VERSION ""

NS_ :

BS_:

BU_: External_Tool IPMA_ADAS SODRR SODRL
VAL_TABLE_ CAN_RADAR_ALIGN_INCOMPLETE 1 "Alignment Incomplete" 0 "Alignment Completed" ;

BO_ 3221225472 VECTOR__INDEPENDENT_SIG_MSG: 0 Vector__XXX
 SG_ FL_Resp_Phys : 0|64@0+ (1,0) [0|0] "" Vector__XXX
 SG_ FR_Resp_Phys : 0|64@0+ (1,0) [0|0] "" Vector__XXX
 SG_ FR_XCP_RESP_DAQ_Byte7 : 0|8@0+ (1,0) [0|0] "" Vector__XXX
 SG_ FR_XCP_RESP_DAQ_Byte6 : 0|8@0+ (1,0) [0|0] "" Vector__XXX
 SG_ FR_XCP_RESP_DAQ_Byte5 : 0|8@0+ (1,0) [0|0] "" Vector__XXX
 SG_ FR_XCP_RESP_DAQ_Byte4 : 0|8@0+ (1,0) [0|0] "" Vector__XXX
 SG_ FR_XCP_RESP_DAQ_Byte3 : 0|8@0+ (1,0) [0|0] "" Vector__XXX
 SG_ FR_XCP_RESP_DAQ_Byte2 : 0|8@0+ (1,0) [0|0] "" Vector__XXX
 SG_ FR_XCP_RESP_DAQ_Byte1 : 0|8@0+ (1,0) [0|0] "" Vector__XXX
 SG_ FR_XCP_RESP_DAQ_Byte0 : 0|8@0+ (1,0) [0|0] "" Vector__XXX
 SG_ FL_XCP_RESP_DAQ_Byte7 : 0|8@0+ (1,0) [0|0] "" Vector__XXX
 SG_ FL_XCP_RESP_DAQ_Byte6 : 0|8@0+ (1,0) [0|0] "" Vector__XXX
 SG_ FL_XCP_RESP_DAQ_Byte5 : 0|8@0+ (1,0) [0|0] "" Vector__XXX
 SG_ FL_XCP_RESP_DAQ_Byte4 : 0|8@0+ (1,0) [0|0] "" Vector__XXX
 SG_ FL_XCP_RESP_DAQ_Byte3 : 0|8@0+ (1,0) [0|0] "" Vector__XXX
 SG_ FL_XCP_RESP_DAQ_Byte2 : 0|8@0+ (1,0) [0|0] "" Vector__XXX
 SG_ FL_XCP_RESP_DAQ_Byte1 : 0|8@0+ (1,0) [0|0] "" Vector__XXX
 SG_ FL_XCP_RESP_DAQ_Byte0 : 0|8@0+ (1,0) [0|0] "" Vector__XXX
 SG_ FR_XCP_RESP_CTO_Byte7 : 0|8@0+ (1,0) [0|0] "" Vector__XXX
 SG_ FR_XCP_RESP_CTO_Byte6 : 0|8@0+ (1,0) [0|0] "" Vector__XXX
 SG_ FR_XCP_RESP_CTO_Byte5 : 0|8@0+ (1,0) [0|0] "" Vector__XXX
 SG_ FR_XCP_RESP_CTO_Byte4 : 0|8@0+ (1,0) [0|0] "" Vector__XXX
 SG_ FR_XCP_RESP_CTO_Byte3 : 0|8@0+ (1,0) [0|0] "" Vector__XXX
 SG_ FR_XCP_RESP_CTO_Byte2 : 0|8@0+ (1,0) [0|0] "" Vector__XXX
 SG_ FR_XCP_RESP_CTO_Byte1 : 0|8@0+ (1,0) [0|0] "" Vector__XXX
 SG_ FR_XCP_RESP_CTO_Byte0 : 0|8@0+ (1,0) [0|0] "" Vector__XXX
 SG_ FL_XCP_RESP_CTO_Byte7 : 0|8@0+ (1,0) [0|0] "" Vector__XXX
 SG_ FL_XCP_RESP_CTO_Byte6 : 0|8@0+ (1,0) [0|0] "" Vector__XXX
 SG_ FL_XCP_RESP_CTO_Byte5 : 0|8@0+ (1,0) [0|0] "" Vector__XXX
 SG_ FL_XCP_RESP_CTO_Byte4 : 0|8@0+ (1,0) [0|0] "" Vector__XXX
 SG_ FL_XCP_RESP_CTO_Byte3 : 0|8@0+ (1,0) [0|0] "" Vector__XXX
 SG_ FL_XCP_RESP_CTO_Byte2 : 0|8@0+ (1,0) [0|0] "" Vector__XXX
 SG_ FL_XCP_RESP_CTO_Byte1 : 0|8@0+ (1,0) [0|0] "" Vector__XXX
 SG_ FL_XCP_RESP_CTO_Byte0 : 0|8@0+ (1,0) [0|0] "" Vector__XXX

BO_ 16 FL_System_Control: 8 External_Tool
 SG_ FL_CAN_INST_MODE : 23|16@0+ (1,0) [0|65535] ""  SODRL

BO_ 17 FR_System_Control: 8 External_Tool
 SG_ FR_CAN_INST_MODE : 23|16@0+ (1,0) [0|65535] ""  SODRL

BO_ 18 RL_System_Control: 8 External_Tool
 SG_ RL_CAN_INST_MODE : 23|16@0+ (1,0) [0|65535] ""  SODRR

BO_ 19 RR_System_Control: 8 External_Tool
 SG_ RR_CAN_INST_MODE : 23|16@0+ (1,0) [0|65535] ""  SODRR

BO_ 396 RL_Header_InformationDetections: 8 SODRL
 SG_ RL_CAN_VRTCL_ALIGN_UPDATES_Nbr : 23|16@0+ (1,0) [0|65535] ""  IPMA_ADAS
 SG_ RL_CAN_HRZNTL_ALIGN_UPDATES_Nbr : 7|16@0+ (1,0) [0|65535] ""  IPMA_ADAS

BO_ 460 RR_Header_InformationDetections: 8 SODRR
 SG_ RR_CAN_VRTCL_ALIGN_UPDATES_Nbr : 23|16@0+ (1,0) [0|65535] ""  IPMA_ADAS
 SG_ RR_CAN_HRZNTL_ALIGN_UPDATES_Nbr : 7|16@0+ (1,0) [0|65535] ""  IPMA_ADAS

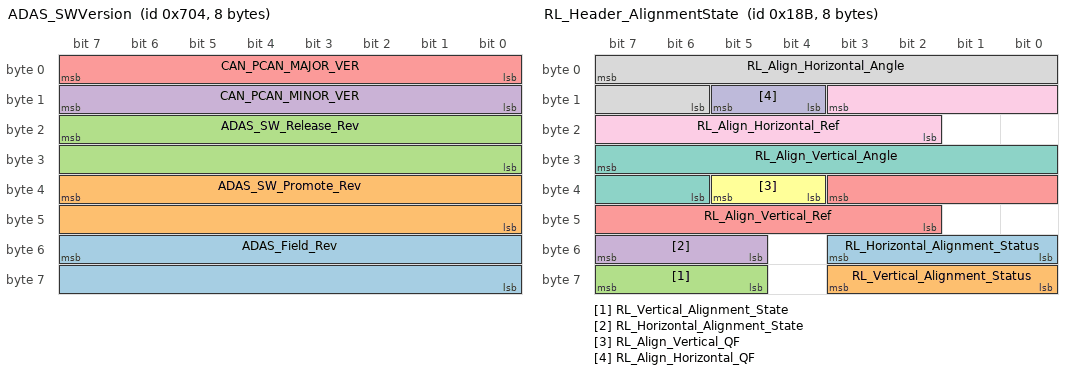
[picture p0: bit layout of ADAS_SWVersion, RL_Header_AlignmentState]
BO_ 1796 ADAS_SWVersion: 8 IPMA_ADAS
 SG_ ADAS_Field_Rev : 55|16@0+ (1,0) [0|0] ""  SODRL,SODRR
 SG_ ADAS_SW_Promote_Rev : 39|16@0+ (1,0) [0|0] ""  SODRL,SODRR
 SG_ ADAS_SW_Release_Rev : 23|16@0+ (1,0) [0|0] ""  SODRL,SODRR
 SG_ CAN_PCAN_MINOR_VER : 15|8@0+ (1,0) [0|0] ""  SODRL,SODRR
 SG_ CAN_PCAN_MAJOR_VER : 7|8@0+ (1,0) [0|0] ""  SODRL,SODRR

BO_ 395 RL_Header_AlignmentState: 8 SODRL
 SG_ RL_Horizontal_Alignment_Status : 51|4@0+ (1,0) [0|15] ""  IPMA_ADAS,External_Tool
 SG_ RL_Vertical_Alignment_Status : 59|4@0+ (1,0) [0|15] ""  IPMA_ADAS,External_Tool
 SG_ RL_Vertical_Alignment_State : 63|3@0+ (1,0) [0|7] ""  IPMA_ADAS,External_Tool
 SG_ RL_Horizontal_Alignment_State : 55|3@0+ (1,0) [0|7] ""  IPMA_ADAS,External_Tool
 SG_ RL_Align_Vertical_Ref : 35|10@0+ (0.000170608920038546,-0.0872664625997165) [-0.0872664625997165|0.0872664625997165] "Rad"  IPMA_ADAS,External_Tool
 SG_ RL_Align_Vertical_QF : 37|2@0+ (1,0) [0|3] ""  IPMA_ADAS,External_Tool
 SG_ RL_Align_Vertical_Angle : 31|10@0+ (0.000170608920038546,-0.0872664625997165) [-0.0872664625997165|0.0872664625997165] "Rad"  IPMA_ADAS,External_Tool
 SG_ RL_Align_Horizontal_Angle : 7|10@0+ (0.000341217840077093,-0.174532925199433) [-0.174532925199433|0.174532925199433] "Rad"  IPMA_ADAS,External_Tool
 SG_ RL_Align_Horizontal_Ref : 11|10@0+ (0.000341217840077093,-0.174532925199433) [-0.174532925199433|0.174532925199433] "Rad"  IPMA_ADAS,External_Tool
 SG_ RL_Align_Horizontal_QF : 13|2@0+ (1,0) [0|3] ""  IPMA_ADAS,External_Tool

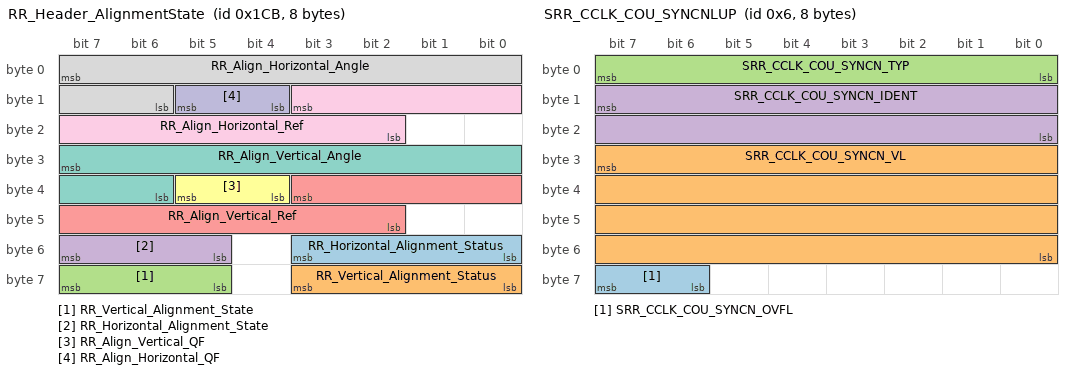
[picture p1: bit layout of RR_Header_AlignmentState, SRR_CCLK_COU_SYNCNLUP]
BO_ 459 RR_Header_AlignmentState: 8 SODRR
 SG_ RR_Horizontal_Alignment_Status : 51|4@0+ (1,0) [0|15] ""  IPMA_ADAS,External_Tool
 SG_ RR_Vertical_Alignment_Status : 59|4@0+ (1,0) [0|15] ""  IPMA_ADAS,External_Tool
 SG_ RR_Vertical_Alignment_State : 63|3@0+ (1,0) [0|7] ""  IPMA_ADAS,External_Tool
 SG_ RR_Horizontal_Alignment_State : 55|3@0+ (1,0) [0|7] ""  IPMA_ADAS,External_Tool
 SG_ RR_Align_Vertical_Ref : 35|10@0+ (0.000170608920038546,-0.0872664625997165) [-0.0872664625997165|0.0872664625997165] "Rad"  IPMA_ADAS,External_Tool
 SG_ RR_Align_Vertical_QF : 37|2@0+ (1,0) [0|3] ""  IPMA_ADAS,External_Tool
 SG_ RR_Align_Vertical_Angle : 31|10@0+ (0.000170608920038546,-0.0872664625997165) [-0.0872664625997165|0.0872664625997165] "Rad"  IPMA_ADAS,External_Tool
 SG_ RR_Align_Horizontal_Angle : 7|10@0+ (0.000341217840077093,-0.174532925199433) [-0.174532925199433|0.174532925199433] "Rad"  IPMA_ADAS,External_Tool
 SG_ RR_Align_Horizontal_Ref : 11|10@0+ (0.000341217840077093,-0.174532925199433) [-0.174532925199433|0.174532925199433] "Rad"  IPMA_ADAS,External_Tool
 SG_ RR_Align_Horizontal_QF : 13|2@0+ (1,0) [0|3] ""  IPMA_ADAS,External_Tool

BO_ 6 SRR_CCLK_COU_SYNCNLUP: 8 External_Tool
 SG_ SRR_CCLK_COU_SYNCN_OVFL : 63|2@0+ (1,0) [0|0] ""  SODRR,SODRL
 SG_ SRR_CCLK_COU_SYNCN_VL : 31|32@0+ (1,0) [0|4294967295] "micro seconds"  SODRR,SODRL
 SG_ SRR_CCLK_COU_SYNCN_TYP : 7|8@0- (1,0) [0|0] ""  SODRR,SODRL
 SG_ SRR_CCLK_COU_SYNCN_IDENT : 15|16@0- (1,0) [0|65532] ""  SODRR,SODRL

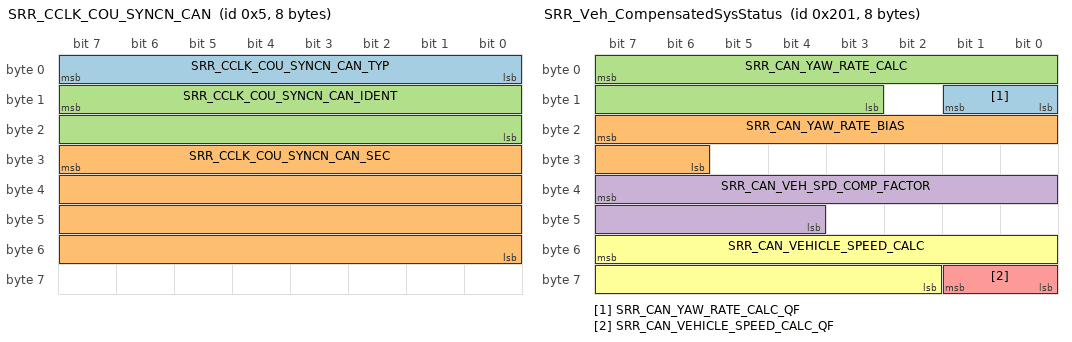
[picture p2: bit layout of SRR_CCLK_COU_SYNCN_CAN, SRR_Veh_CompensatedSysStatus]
BO_ 5 SRR_CCLK_COU_SYNCN_CAN: 8 External_Tool
 SG_ SRR_CCLK_COU_SYNCN_CAN_TYP : 7|8@0+ (1,0) [0|255] ""  SODRR,SODRL
 SG_ SRR_CCLK_COU_SYNCN_CAN_SEC : 31|32@0+ (1,0) [0|4294967292] "seconds"  SODRR,SODRL
 SG_ SRR_CCLK_COU_SYNCN_CAN_IDENT : 15|16@0+ (1,0) [0|65532] ""  SODRR,SODRL

BO_ 513 SRR_Veh_CompensatedSysStatus: 8 IPMA_ADAS
 SG_ SRR_CAN_YAW_RATE_CALC_QF : 9|2@0+ (1,0) [0|3] ""  SODRR,SODRL
 SG_ SRR_CAN_YAW_RATE_BIAS : 23|10@0+ (0.03125,-16) [-16|15.96875] "deg/s"  SODRR,SODRL
 SG_ SRR_CAN_YAW_RATE_CALC : 7|13@0+ (0.03125,-128) [-128|127.96875] "deg/s"  SODRR,SODRL
 SG_ SRR_CAN_VEH_SPD_COMP_FACTOR : 39|12@0+ (9.765625E-005,0.8) [0.8|1.19990234375] "NA"  SODRR,SODRL
 SG_ SRR_CAN_VEHICLE_SPEED_CALC_QF : 57|2@0+ (1,0) [0|3] ""  SODRR,SODRL
 SG_ SRR_CAN_VEHICLE_SPEED_CALC : 55|14@0+ (0.01,0) [0|163.83] "m/s"  SODRR,SODRL

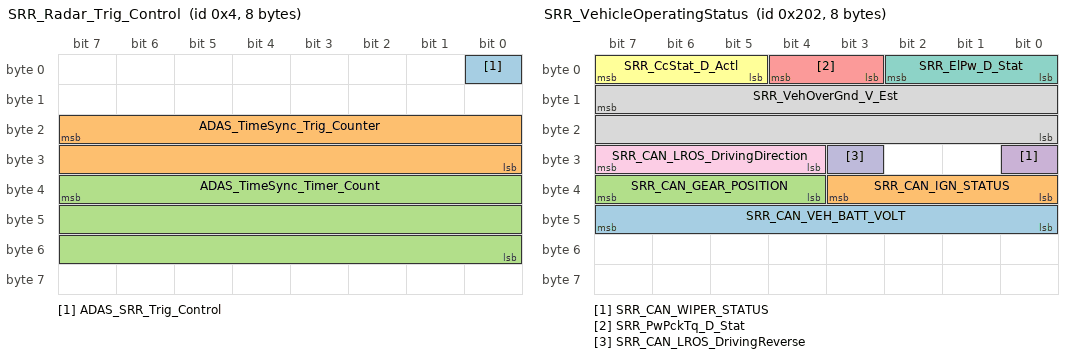
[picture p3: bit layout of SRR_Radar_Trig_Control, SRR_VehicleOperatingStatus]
BO_ 4 SRR_Radar_Trig_Control: 8 IPMA_ADAS
 SG_ ADAS_SRR_Trig_Control : 0|1@0+ (1,0) [0|0] ""  SODRR,SODRL
 SG_ ADAS_TimeSync_Trig_Counter : 23|16@0+ (1,0) [0|0] "us"  SODRR,SODRL
 SG_ ADAS_TimeSync_Timer_Count : 39|24@0+ (1,0) [0|16777215] "us"  SODRR,SODRL

BO_ 514 SRR_VehicleOperatingStatus: 8 IPMA_ADAS
 SG_ SRR_CAN_VEH_BATT_VOLT : 47|8@0+ (0.0625,0) [0|15.875] ""  SODRL,SODRR
 SG_ SRR_CAN_IGN_STATUS : 35|4@0- (1,0) [0|15] ""  SODRL,SODRR
 SG_ SRR_CAN_GEAR_POSITION : 39|4@0+ (1,0) [0|15] ""  SODRL,SODRR
 SG_ SRR_CAN_WIPER_STATUS : 24|1@0+ (1,0) [0|1] ""  SODRL,SODRR
 SG_ SRR_PwPckTq_D_Stat : 4|2@0+ (1,0) [0|3] "SED"  SODRR,SODRL
 SG_ SRR_CcStat_D_Actl : 7|3@0+ (1,0) [0|7] "SED"  SODRR,SODRL
 SG_ SRR_ElPw_D_Stat : 2|3@0+ (1,0) [0|7] "SED"  SODRR,SODRL
 SG_ SRR_VehOverGnd_V_Est : 15|16@0+ (0.01,0) [0|655.33] "kph"  SODRR,SODRL
 SG_ SRR_CAN_LROS_DrivingDirection : 31|4@0+ (1,0) [0|3] ""  SODRR,SODRL
 SG_ SRR_CAN_LROS_DrivingReverse : 27|1@0+ (1,0) [0|1] ""  SODRR,SODRL

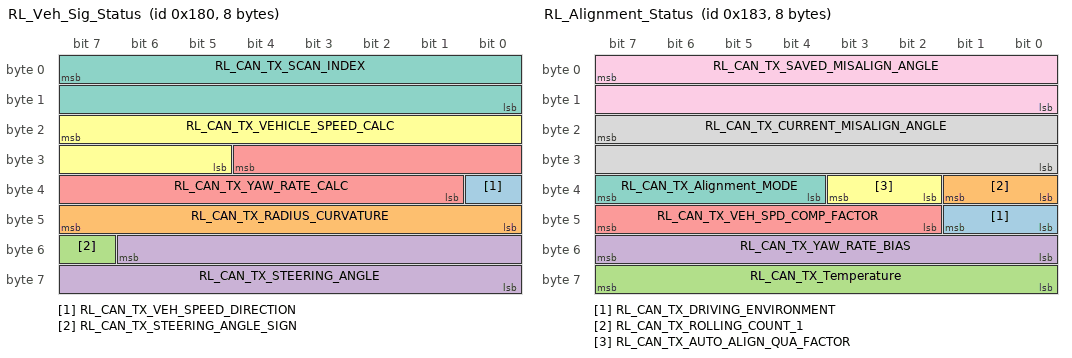
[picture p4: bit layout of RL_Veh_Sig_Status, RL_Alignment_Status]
BO_ 384 RL_Veh_Sig_Status: 8 SODRL
 SG_ RL_CAN_TX_VEH_SPEED_DIRECTION : 32|1@0+ (1,0) [0|0] ""  IPMA_ADAS
 SG_ RL_CAN_TX_RADIUS_CURVATURE : 47|8@0- (25,0) [-3200|3200] "m"  IPMA_ADAS
 SG_ RL_CAN_TX_STEERING_ANGLE_SIGN : 55|1@0+ (1,0) [0|1] ""  IPMA_ADAS
 SG_ RL_CAN_TX_STEERING_ANGLE : 54|15@0+ (1,0) [0|32767] "deg"  IPMA_ADAS
 SG_ RL_CAN_TX_YAW_RATE_CALC : 28|12@0- (0.0625,0) [-128|127.9375] "deg/s"  IPMA_ADAS
 SG_ RL_CAN_TX_VEHICLE_SPEED_CALC : 23|11@0+ (0.0625,0) [0|127.9375] "m/s"  IPMA_ADAS
 SG_ RL_CAN_TX_SCAN_INDEX : 7|16@0+ (1,0) [0|65535] ""  IPMA_ADAS

BO_ 385 RL_HW_Version_Status: 64 SODRL
 SG_ RL_Dolphin_Chip_ID_Part2 : 391|64@0+ (1,0) [0|0] ""  IPMA_ADAS
 SG_ RL_Dolphin_Chip_ID_Part1 : 327|64@0+ (1,0) [0|0] ""  IPMA_ADAS
 SG_ RL_RRU_Chip_ID_Part4 : 263|64@0+ (1,0) [0|0] ""  IPMA_ADAS
 SG_ RL_RRU_Chip_ID_Part3 : 199|64@0+ (1,0) [0|0] ""  IPMA_ADAS
 SG_ RL_RRU_Chip_ID_Part2 : 135|64@0+ (1,0) [0|0] ""  IPMA_ADAS
 SG_ RL_RRU_Chip_ID_Part1 : 71|64@0+ (1,0) [0|0] ""  IPMA_ADAS
 SG_ RL_CAN_TX_SW_VERSION_DSP : 47|24@0+ (1,0) [0|0] ""  IPMA_ADAS
 SG_ RL_CAN_TX_PCAN_PROTOCOL_MINOR : 15|8@0+ (1,0) [0|255] ""  IPMA_ADAS
 SG_ RL_CAN_TX_PCAN_PROTOCOL_MAJOR : 3|4@0+ (1,0) [0|15] ""  IPMA_ADAS
 SG_ RL_CAN_TX_SW_VERSION_ARM : 23|24@0+ (1,0) [0|0] ""  IPMA_ADAS
 SG_ RL_CAN_TX_HW_VERSION : 7|4@0+ (1,0) [0|0] ""  IPMA_ADAS

BO_ 386 RL_SW_Version_Status: 16 SODRL
 SG_ RL_CAN_TX_Field : 23|8@0+ (1,0) [0|0] ""  IPMA_ADAS
 SG_ RL_CAN_TX_Promote : 13|6@0+ (1,0) [0|0] ""  IPMA_ADAS
 SG_ RL_CAN_TX_Major : 3|6@0+ (1,0) [0|0] ""  IPMA_ADAS
 SG_ RL_CAN_TX_Hardware : 7|4@0+ (1,0) [0|0] ""  IPMA_ADAS
 SG_ RL_CAN_TX_SERIAL_NUMBER_SEQUENCE : 35|12@0+ (1,0) [0|0] ""  IPMA_ADAS
 SG_ RL_CAN_TX_SERIAL_NUM_JULIAN_YEAR : 38|3@0+ (1,2014) [0|0] ""  IPMA_ADAS
 SG_ RL_CAN_TX_SERIAL_NUM_JULIAN_DAY : 31|9@0+ (1,0) [0|0] ""  IPMA_ADAS
 SG_ RL_CAN_TX_ARM_THROUGHPUT : 63|5@0+ (3.2258,0) [0|0] ""  IPMA_ADAS
 SG_ RL_CAN_TX_SYSTEM_STATUS : 58|3@0+ (1,0) [0|0] ""  IPMA_ADAS
 SG_ RL_CAN_TX_LOOK_TYPE_1 : 50|1@0+ (1,0) [0|0] ""  IPMA_ADAS
 SG_ RL_CAN_TX_OVERHEAT_ERROR : 51|1@0+ (1,0) [0|0] ""  IPMA_ADAS
 SG_ RL_CAN_TX_RANGE_PERF_ERROR : 52|1@0+ (1,0) [0|0] ""  IPMA_ADAS
 SG_ RL_CAN_TX_COMM_ERROR : 53|1@0+ (1,0) [0|0] ""  IPMA_ADAS
 SG_ RL_CAN_TX_INTERNAL_ERROR : 54|1@0+ (1,0) [0|0] ""  IPMA_ADAS
 SG_ RL_CAN_TX_XCVR_OPERATIONAL : 55|1@0+ (1,0) [0|0] ""  IPMA_ADAS
 SG_ RL_CAN_PBL_Field_Revision : 119|8@0+ (1,0) [0|255] ""  IPMA_ADAS
 SG_ RL_CAN_PBL_Promote_Revision : 111|8@0+ (1,0) [0|255] ""  IPMA_ADAS
 SG_ RL_CAN_SW_Field_Revision : 87|8@0+ (1,0) [0|255] ""  IPMA_ADAS
 SG_ RL_CAN_SW_Promote_Revision : 79|8@0+ (1,0) [0|255] ""  IPMA_ADAS
 SG_ RL_CAN_SW_Field : 95|8@0+ (1,0) [0|255] ""  IPMA_ADAS
 SG_ RL_CAN_SW_Release_Revision : 71|8@0+ (1,0) [0|255] ""  IPMA_ADAS
 SG_ RL_CAN_PBL_Release_Revision : 103|8@0+ (1,0) [0|255] ""  IPMA_ADAS

BO_ 387 RL_Alignment_Status: 8 SODRL
 SG_ RL_CAN_TX_DRIVING_ENVIRONMENT : 41|2@0+ (1,0) [0|0] ""  IPMA_ADAS
 SG_ RL_CAN_TX_ROLLING_COUNT_1 : 33|2@0+ (1,0) [0|0] ""  IPMA_ADAS
 SG_ RL_CAN_TX_Temperature : 63|8@0+ (1,-50) [-50|205] "degC"  IPMA_ADAS
 SG_ RL_CAN_TX_YAW_RATE_BIAS : 55|8@0- (0.125,0) [-16|15.875] ""  IPMA_ADAS
 SG_ RL_CAN_TX_VEH_SPD_COMP_FACTOR : 47|6@0- (0.001953125,1) [0.9375|1.060546875] ""  IPMA_ADAS
 SG_ RL_CAN_TX_AUTO_ALIGN_QUA_FACTOR : 35|2@0+ (1,0) [0|0] ""  IPMA_ADAS
 SG_ RL_CAN_TX_Alignment_MODE : 39|4@0+ (1,0) [0|0] ""  IPMA_ADAS
 SG_ RL_CAN_TX_CURRENT_MISALIGN_ANGLE : 23|16@0- (0.0009765625,0) [-10|10] "Deg"  IPMA_ADAS
 SG_ RL_CAN_TX_SAVED_MISALIGN_ANGLE : 7|16@0- (0.0009765625,0) [-10|10] "Deg"  IPMA_ADAS

BO_ 388 RL_Fault_Status: 8 SODRL
 SG_ RL_Supply_2_3v_Out_Of_Range_Flt : 9|1@0+ (1,0) [0|0] ""  IPMA_ADAS
 SG_ RL_Supply_1_25v_Out_Of_Range_Flt : 10|1@0+ (1,0) [0|0] ""  IPMA_ADAS
 SG_ RL_Software_Incompatible_Flt : 61|1@0+ (1,0) [0|0] ""  IPMA_ADAS
 SG_ RL_Host_Spi_Checksum_Flt : 60|1@0+ (1,0) [0|0] ""  IPMA_ADAS
 SG_ RL_Loss_Of_Comm_With_Dsp_Flt : 59|1@0+ (1,0) [0|0] ""  IPMA_ADAS
 SG_ RL_No_Communication_With_Arm_Flt : 58|1@0+ (1,0) [0|0] ""  IPMA_ADAS
 SG_ RL_Communication_With_Host_Flt : 57|1@0+ (1,0) [0|0] ""  IPMA_ADAS
 SG_ RL_Communication_With_Arm_Flt : 56|1@0+ (1,0) [0|0] ""  IPMA_ADAS
 SG_ RL_Dsp_Loop_Overrun_Flt_Dsp : 51|1@0+ (1,0) [0|0] ""  IPMA_ADAS
 SG_ RL_Tuning_Sensitivity_Flt : 50|1@0+ (1,0) [0|0] ""  IPMA_ADAS
 SG_ RL_Saturated_Tuning_Freq_Flt : 49|1@0+ (1,0) [0|0] ""  IPMA_ADAS
 SG_ RL_Local_Oscillator_Power_Flt : 48|1@0+ (1,0) [0|0] ""  IPMA_ADAS
 SG_ RL_Transmitter_Power_Flt : 47|1@0+ (1,0) [0|0] ""  IPMA_ADAS
 SG_ RL_Radar_Data_Sync_Flt : 46|1@0+ (1,0) [0|0] ""  IPMA_ADAS
 SG_ RL_Dsp_Spi_Hardware_Flt : 45|1@0+ (1,0) [0|0] ""  IPMA_ADAS
 SG_ RL_Transmitter_Device_Spi_Flt : 44|1@0+ (1,0) [0|0] ""  IPMA_ADAS
 SG_ RL_Receiver_Device_Spi_Flt : 43|1@0+ (1,0) [0|0] ""  IPMA_ADAS
 SG_ RL_Freq_Synthe_Device_Spi_Flt : 42|1@0+ (1,0) [0|0] ""  IPMA_ADAS
 SG_ RL_Analog_Cnvrtr_Device_Spi_Flt : 41|1@0+ (1,0) [0|0] ""  IPMA_ADAS
 SG_ RL_Transmitter_Id_Flt : 40|1@0+ (1,0) [0|0] ""  IPMA_ADAS
 SG_ RL_Ecu_Temperature_High_Flt : 39|1@0+ (1,0) [0|0] ""  IPMA_ADAS
 SG_ RL_Transmitter_Temp_High_Flt : 38|1@0+ (1,0) [0|0] ""  IPMA_ADAS
 SG_ RL_Alignment_Routine_Failed_Flt : 37|1@0+ (1,0) [0|0] ""  IPMA_ADAS
 SG_ RL_Unreasonable_Radar_Data : 36|1@0+ (1,0) [0|0] ""  IPMA_ADAS
 SG_ RL_Sensor_Blocked_Flt : 35|1@0+ (1,0) [0|0] ""  IPMA_ADAS
 SG_ RL_Vertical_Alignt_Out_Of_Range : 34|1@0+ (1,0) [0|0] ""  IPMA_ADAS
 SG_ RL_Horizontal_Align_Out_Of_Range : 33|1@0+ (1,0) [0|0] ""  IPMA_ADAS
 SG_ RL_Factory_Alignment_Mode : 32|1@0+ (1,0) [0|0] ""  IPMA_ADAS
 SG_ RL_Battery_Low_Flt : 30|1@0+ (1,0) [0|0] ""  IPMA_ADAS
 SG_ RL_Battery_High_Flt : 29|1@0+ (1,0) [0|0] ""  IPMA_ADAS
 SG_ RL_Ecu_Position_Config_Flt : 28|1@0+ (1,0) [0|0] ""  IPMA_ADAS
 SG_ RL_Supply_1_1v_Out_Of_Range_Flt : 27|1@0+ (1,0) [0|0] ""  IPMA_ADAS
 SG_ RL_Supply_1_8v_Out_Of_Range_Flt : 26|1@0+ (1,0) [0|0] ""  IPMA_ADAS
 SG_ RL_Thermistor_Out_Of_Range_Flt : 25|1@0+ (1,0) [0|0] ""  IPMA_ADAS
 SG_ RL_Supply_5v_Out_Of_Range_Flt : 24|1@0+ (1,0) [0|0] ""  IPMA_ADAS
 SG_ RL_Pcan_Init_Missing_Message_Flt : 22|1@0+ (1,0) [0|0] ""  IPMA_ADAS
 SG_ RL_Pcan_Trk_Data_Unreasnble_Flt : 21|1@0+ (1,0) [0|0] ""  IPMA_ADAS
 SG_ RL_Pcan_Data_Range_Check_Flt : 20|1@0+ (1,0) [0|0] ""  IPMA_ADAS
 SG_ RL_Pcan_Missing_Message_Flt : 19|1@0+ (1,0) [0|0] ""  IPMA_ADAS
 SG_ RL_Pcan_Hw_Rx_Buffer_Flt : 18|1@0+ (1,0) [0|0] ""  IPMA_ADAS
 SG_ RL_Pcan_Sw_Buffer_Flt : 17|1@0+ (1,0) [0|0] ""  IPMA_ADAS
 SG_ RL_Pcan_Bus_Off : 16|1@0+ (1,0) [0|0] ""  IPMA_ADAS
 SG_ RL_Host_Instrctn_Set_Check_Flt : 15|1@0+ (1,0) [0|0] ""  IPMA_ADAS
 SG_ RL_Host_Stack_Overflow_Flt : 14|1@0+ (1,0) [0|0] ""  IPMA_ADAS
 SG_ RL_Sensor_Watchdog_Flt : 13|1@0+ (1,0) [0|0] ""  IPMA_ADAS
 SG_ RL_Sensor_Pll_Lock_Flt : 12|1@0+ (1,0) [0|0] ""  IPMA_ADAS
 SG_ RL_Host_Pll_Lock_Flt : 11|1@0+ (1,0) [0|0] ""  IPMA_ADAS
 SG_ RL_Sensor_Ram_Memory_Test_Flt : 8|1@0+ (1,0) [0|0] ""  IPMA_ADAS
 SG_ RL_Host_Ram_Memory_Test_Flt : 7|1@0+ (1,0) [0|0] ""  IPMA_ADAS
 SG_ RL_Snsr_Custmr_Cal_Flsh_Chksum : 6|1@0+ (1,0) [0|0] ""  IPMA_ADAS
 SG_ RL_Dsp_Usc_Validation_Flt : 5|1@0+ (1,0) [0|0] ""  IPMA_ADAS
 SG_ RL_Snsr_Pgrm_Cal_Flsh_Chksum : 4|1@0+ (1,0) [0|0] ""  IPMA_ADAS
 SG_ RL_Sensor_App_Flash_Checksum_Flt : 3|1@0+ (1,0) [0|0] ""  IPMA_ADAS
 SG_ RL_Host_Kp_Alv_Flsh_Chcksm_Flt : 2|1@0+ (1,0) [0|0] ""  IPMA_ADAS
 SG_ RL_Host_Pgm_Cal_Flsh_Chcksum_Flt : 1|1@0+ (1,0) [0|0] ""  IPMA_ADAS
 SG_ RL_Host_App_Flash_Checksum_Flt : 0|1@0+ (1,0) [0|0] ""  IPMA_ADAS

BO_ 389 RL_Error_Status: 12 SODRL
 SG_ RL_Dolphin_Fault_Detection : 87|8@0+ (1,0) [0|63] ""  IPMA_ADAS
 SG_ RL_RRU_Self_Test_Faults : 79|8@0+ (1,0) [0|63] ""  IPMA_ADAS
 SG_ RL_RRU_Core_Faults : 71|8@0+ (1,0) [0|63] ""  IPMA_ADAS
 SG_ RL_USC_Load_Error : 59|1@0+ (1,0) [0|0] ""  IPMA_ADAS
 SG_ RL_SMC_Load_Error : 58|1@0+ (1,0) [0|0] ""  IPMA_ADAS
 SG_ RL_TX_Temperature_Flt : 57|1@0+ (1,0) [0|0] ""  IPMA_ADAS
 SG_ RL_Dsp_Unit_Cal_Blk_Chcksm_Error : 56|1@0+ (1,0) [0|0] ""  IPMA_ADAS
 SG_ RL_Dsp_Unit_Cal_Checksum_Error : 55|1@0+ (1,0) [0|0] ""  IPMA_ADAS
 SG_ RL_Vertical_Misalignment_error : 54|1@0+ (1,0) [0|0] ""  IPMA_ADAS
 SG_ RL_RTN_SPI_Transfer_Error : 53|1@0+ (1,0) [0|0] ""  IPMA_ADAS
 SG_ RL_RRN_SPI_Transfer_Error : 52|1@0+ (1,0) [0|0] ""  IPMA_ADAS
 SG_ RL_Linearizer_SPI_Transfer_Error : 51|1@0+ (1,0) [0|0] ""  IPMA_ADAS
 SG_ RL_ADC_SPI_Transfer_Error : 50|1@0+ (1,0) [0|0] ""  IPMA_ADAS
 SG_ RL_Transmitter_ID_Error : 49|1@0+ (1,0) [0|0] ""  IPMA_ADAS
 SG_ RL_Dsp_Loop_Overrun_Error : 48|1@0+ (1,0) [0|0] ""  IPMA_ADAS
 SG_ RL_Saturated_Tuning_Freq_Error : 47|1@0+ (1,0) [0|0] ""  IPMA_ADAS
 SG_ RL_Radar_Data_sync_error : 46|1@0+ (1,0) [0|0] ""  IPMA_ADAS
 SG_ RL_Dsp_Tuning_Sensitivity_Error : 45|1@0+ (1,0) [0|0] ""  IPMA_ADAS
 SG_ RL_Radar_LO_Power_Error : 44|1@0+ (1,0) [0|0] ""  IPMA_ADAS
 SG_ RL_Radar_TX_Power_Error : 43|1@0+ (1,0) [0|0] ""  IPMA_ADAS
 SG_ RL_Timer_Create_Error : 6|1@0+ (1,0) [0|0] ""  IPMA_ADAS
 SG_ RL_Thread_Create_Error : 2|1@0+ (1,0) [0|0] ""  IPMA_ADAS
 SG_ RL_ARM_Calibration_Error : 9|1@0+ (1,0) [0|0] ""  IPMA_ADAS
 SG_ RL_SPI_FEE_Error : 14|1@0+ (1,0) [0|0] ""  IPMA_ADAS
 SG_ RL_SPI_Comm_Error : 13|1@0+ (1,0) [0|0] ""  IPMA_ADAS
 SG_ RL_Socket_Write_Error : 39|1@0+ (1,0) [0|0] ""  IPMA_ADAS
 SG_ RL_Socket_Read_error : 38|1@0+ (1,0) [0|0] ""  IPMA_ADAS
 SG_ RL_Socket_Init_Error : 37|1@0+ (1,0) [0|0] ""  IPMA_ADAS
 SG_ RL_Signal_Wait_Error : 4|1@0+ (1,0) [0|0] ""  IPMA_ADAS
 SG_ RL_Signal_Send_Error : 5|1@0+ (1,0) [0|0] ""  IPMA_ADAS
 SG_ RL_Signal_Create_Error : 3|1@0+ (1,0) [0|0] ""  IPMA_ADAS
 SG_ RL_Shared_Mem_Write_Error : 21|1@0+ (1,0) [0|0] ""  IPMA_ADAS
 SG_ RL_Shared_Mem_Read_Error : 20|1@0+ (1,0) [0|0] ""  IPMA_ADAS
 SG_ RL_Shared_Mem_Config_Error : 19|1@0+ (1,0) [0|0] ""  IPMA_ADAS
 SG_ RL_Share_Mem_Init_Error : 18|1@0+ (1,0) [0|0] ""  IPMA_ADAS
 SG_ RL_RAM_Test_Error : 1|1@0+ (1,0) [0|0] ""  IPMA_ADAS
 SG_ RL_Num_Errors : 63|1@0+ (1,0) [0|0] ""  IPMA_ADAS
 SG_ RL_MMAP_Memory_Error : 40|1@0+ (1,0) [0|0] ""  IPMA_ADAS
 SG_ RL_ISR_Attach_Error : 36|1@0+ (1,0) [0|0] ""  IPMA_ADAS
 SG_ RL_IPC_DRV_Write_Error : 29|1@0+ (1,0) [0|0] ""  IPMA_ADAS
 SG_ RL_IPC_DRV_Trigger_Error : 31|1@0+ (1,0) [0|0] ""  IPMA_ADAS
 SG_ RL_IPC_DRV_Sync_Error : 30|1@0+ (1,0) [0|0] ""  IPMA_ADAS
 SG_ RL_IPC_DRV_Read_Error : 28|1@0+ (1,0) [0|0] ""  IPMA_ADAS
 SG_ RL_IPC_DRV_Init_Error : 27|1@0+ (1,0) [0|0] ""  IPMA_ADAS
 SG_ RL_Interrupt_Enable_Error : 42|1@0+ (1,0) [0|0] ""  IPMA_ADAS
 SG_ RL_HIL_Format_Error : 41|1@0+ (1,0) [0|0] ""  IPMA_ADAS
 SG_ RL_Flash_Filesystem_Error : 7|1@0+ (1,0) [0|0] ""  IPMA_ADAS
 SG_ RL_Error_none : 0|1@0+ (1,0) [0|0] ""  IPMA_ADAS
 SG_ RL_Dsp_Load_Read_Error : 34|1@0+ (1,0) [0|0] ""  IPMA_ADAS
 SG_ RL_Dsp_Load_Open_Error : 33|1@0+ (1,0) [0|0] ""  IPMA_ADAS
 SG_ RL_Dsp_Load_Address_Error : 35|1@0+ (1,0) [0|0] ""  IPMA_ADAS
 SG_ RL_Dsp_ISP_Write_Error : 17|1@0+ (1,0) [0|0] ""  IPMA_ADAS
 SG_ RL_Dsp_IPC_Read_Error : 16|1@0+ (1,0) [0|0] ""  IPMA_ADAS
 SG_ RL_Dsp_IPC_Init : 15|1@0+ (1,0) [0|0] ""  IPMA_ADAS
 SG_ RL_Dsp_Init_Error : 32|1@0+ (1,0) [0|0] ""  IPMA_ADAS
 SG_ RL_Dsp_DRV_Start_Error : 26|1@0+ (1,0) [0|0] ""  IPMA_ADAS
 SG_ RL_Dsp_DRV_Load_Error : 25|1@0+ (1,0) [0|0] ""  IPMA_ADAS
 SG_ RL_Dsp_DRV_Init_Error : 22|1@0+ (1,0) [0|0] ""  IPMA_ADAS
 SG_ RL_Dsp_DRV_Init2_error : 24|1@0+ (1,0) [0|0] ""  IPMA_ADAS
 SG_ RL_Dsp_DRV_Init1_error : 23|1@0+ (1,0) [0|0] ""  IPMA_ADAS
 SG_ RL_CAN_XMT_Error : 10|1@0+ (1,0) [0|0] ""  IPMA_ADAS
 SG_ RL_CAN_RCV_Error : 11|1@0+ (1,0) [0|0] ""  IPMA_ADAS
 SG_ RL_CAN_Hardware_Error : 12|1@0+ (1,0) [0|0] ""  IPMA_ADAS
 SG_ RL_Always_True : 62|1@0+ (1,0) [0|0] ""  IPMA_ADAS

BO_ 390 RL_General_Info_Status: 8 SODRL
 SG_ RL_CAN_TX_MUX_SVK_CAL_DATA_5 m128 : 63|8@0+ (1,0) [0|0] ""  IPMA_ADAS
 SG_ RL_CAN_TX_MUX_SVK_CAL_DATA_4 m128 : 55|8@0+ (1,0) [0|0] ""  IPMA_ADAS
 SG_ RL_CAN_TX_MUX_SVK_CAL_DATA_3 m128 : 47|8@0+ (1,0) [0|0] ""  IPMA_ADAS
 SG_ RL_CAN_TX_MUX_SVK_CAL_DATA_2 m128 : 39|8@0+ (1,0) [0|0] ""  IPMA_ADAS
 SG_ RL_CAN_TX_MUX_SVK_CAL_DATA_1 m128 : 31|8@0+ (1,0) [0|0] ""  IPMA_ADAS
 SG_ RL_CAN_TX_MUX_SVK_CAL_DATA_0 m128 : 23|8@0+ (1,0) [0|0] ""  IPMA_ADAS
 SG_ RL_CAN_TX_MUX_SVK_CAL_MSG_CNT m128 : 15|8@0+ (1,0) [0|0] ""  IPMA_ADAS
 SG_ RL_CAN_TX_MUX_RCWM_CAL_MSG_CNT m29 : 15|8@0+ (1,0) [0|0] ""  IPMA_ADAS
 SG_ RL_CAN_TX_MUX_RCWM_CAL_DATA_0 m29 : 23|8@0+ (1,0) [0|0] ""  IPMA_ADAS
 SG_ RL_CAN_TX_MUX_RCWM_CAL_DATA_1 m29 : 31|8@0+ (1,0) [0|0] ""  IPMA_ADAS
 SG_ RL_CAN_TX_MUX_RCWM_CAL_DATA_2 m29 : 39|8@0+ (1,0) [0|0] ""  IPMA_ADAS
 SG_ RL_CAN_TX_MUX_RCWM_CAL_DATA_3 m29 : 47|8@0+ (1,0) [0|0] ""  IPMA_ADAS
 SG_ RL_CAN_TX_MUX_RCWM_CAL_DATA_4 m29 : 55|8@0+ (1,0) [0|0] ""  IPMA_ADAS
 SG_ RL_CAN_TX_MUX_RCWM_CAL_DATA_5 m29 : 63|8@0+ (1,0) [0|0] ""  IPMA_ADAS
 SG_ RL_CAN_TX_MUX_RECW_CAL_MSG_CNT m28 : 15|8@0+ (1,0) [0|0] ""  IPMA_ADAS
 SG_ RL_CAN_TX_MUX_RECW_CAL_DATA_0 m28 : 23|8@0+ (1,0) [0|0] ""  IPMA_ADAS
 SG_ RL_CAN_TX_MUX_RECW_CAL_DATA_1 m28 : 31|8@0+ (1,0) [0|0] ""  IPMA_ADAS
 SG_ RL_CAN_TX_MUX_RECW_CAL_DATA_2 m28 : 39|8@0+ (1,0) [0|0] ""  IPMA_ADAS
 SG_ RL_CAN_TX_MUX_RECW_CAL_DATA_3 m28 : 47|8@0+ (1,0) [0|0] ""  IPMA_ADAS
 SG_ RL_CAN_TX_MUX_RECW_CAL_DATA_4 m28 : 55|8@0+ (1,0) [0|0] ""  IPMA_ADAS
 SG_ RL_CAN_TX_MUX_RECW_CAL_DATA_5 m28 : 63|8@0+ (1,0) [0|0] ""  IPMA_ADAS
 SG_ RL_CAN_TX_MUX_FRESPCE_CALMSG_CNT m27 : 15|8@0+ (1,0) [0|0] ""  IPMA_ADAS
 SG_ RL_CAN_TX_MUX_FRESPCE_CAL_DATA_0 m27 : 23|8@0+ (1,0) [0|0] ""  IPMA_ADAS
 SG_ RL_CAN_TX_MUX_FRESPCE_CAL_DATA_1 m27 : 31|8@0+ (1,0) [0|0] ""  IPMA_ADAS
 SG_ RL_CAN_TX_MUX_FRESPCE_CAL_DATA_2 m27 : 39|8@0+ (1,0) [0|0] ""  IPMA_ADAS
 SG_ RL_CAN_TX_MUX_FRESPCE_CAL_DATA_3 m27 : 47|8@0+ (1,0) [0|0] ""  IPMA_ADAS
 SG_ RL_CAN_TX_MUX_FRESPCE_CAL_DATA_4 m27 : 55|8@0+ (1,0) [0|0] ""  IPMA_ADAS
 SG_ RL_CAN_TX_MUX_FRESPCE_CAL_DATA_5 m27 : 63|8@0+ (1,0) [0|0] ""  IPMA_ADAS
 SG_ RL_CAN_TX_MUX_LCDA_CAL_MSG_CNT m26 : 15|8@0+ (1,0) [0|0] ""  IPMA_ADAS
 SG_ RL_CAN_TX_MUX_LCDA_CAL_DATA_0 m26 : 23|8@0+ (1,0) [0|0] ""  IPMA_ADAS
 SG_ RL_CAN_TX_MUX_LCDA_CAL_DATA_1 m26 : 31|8@0+ (1,0) [0|0] ""  IPMA_ADAS
 SG_ RL_CAN_TX_MUX_LCDA_CAL_DATA_2 m26 : 39|8@0+ (1,0) [0|0] ""  IPMA_ADAS
 SG_ RL_CAN_TX_MUX_LCDA_CAL_DATA_3 m26 : 47|8@0+ (1,0) [0|0] ""  IPMA_ADAS
 SG_ RL_CAN_TX_MUX_LCDA_CAL_DATA_4 m26 : 55|8@0+ (1,0) [0|0] ""  IPMA_ADAS
 SG_ RL_CAN_TX_MUX_LCDA_CAL_DATA_5 m26 : 63|8@0+ (1,0) [0|0] ""  IPMA_ADAS
 SG_ RL_CAN_TX_MUX_CTA_CAL_MSG_CNT m25 : 15|8@0+ (1,0) [0|0] ""  IPMA_ADAS
 SG_ RL_CAN_TX_MUX_CTA_CAL_DATA_0 m25 : 23|8@0+ (1,0) [0|0] ""  IPMA_ADAS
 SG_ RL_CAN_TX_MUX_CTA_CAL_DATA_1 m25 : 31|8@0+ (1,0) [0|0] ""  IPMA_ADAS
 SG_ RL_CAN_TX_MUX_CTA_CAL_DATA_2 m25 : 39|8@0+ (1,0) [0|0] ""  IPMA_ADAS
 SG_ RL_CAN_TX_MUX_CTA_CAL_DATA_3 m25 : 47|8@0+ (1,0) [0|0] ""  IPMA_ADAS
 SG_ RL_CAN_TX_MUX_CTA_CAL_DATA_4 m25 : 55|8@0+ (1,0) [0|0] ""  IPMA_ADAS
 SG_ RL_CAN_TX_MUX_CTA_CAL_DATA_5 m25 : 63|8@0+ (1,0) [0|0] ""  IPMA_ADAS
 SG_ RL_CAN_TX_MUX_LOOKID_CAL_MSG_CNT m24 : 15|8@0+ (1,0) [0|0] ""  IPMA_ADAS
 SG_ RL_CAN_TX_MUX_LOOKID_CAL_DATA_0 m24 : 23|8@0+ (1,0) [0|0] ""  IPMA_ADAS
 SG_ RL_CAN_TX_MUX_LOOKID_CAL_DATA_1 m24 : 31|8@0+ (1,0) [0|0] ""  IPMA_ADAS
 SG_ RL_CAN_TX_MUX_LOOKID_CAL_DATA_2 m24 : 39|8@0+ (1,0) [0|0] ""  IPMA_ADAS
 SG_ RL_CAN_TX_MUX_LOOKID_CAL_DATA_3 m24 : 47|8@0+ (1,0) [0|0] ""  IPMA_ADAS
 SG_ RL_CAN_TX_MUX_LOOKID_CAL_DATA_4 m24 : 55|8@0+ (1,0) [0|0] ""  IPMA_ADAS
 SG_ RL_CAN_TX_MUX_LOOKID_CAL_DATA_5 m24 : 63|8@0+ (1,0) [0|0] ""  IPMA_ADAS
 SG_ RL_CAN_TX_MUX_ALIGNMT_CALMSG_CNT m23 : 15|8@0+ (1,0) [0|0] ""  IPMA_ADAS
 SG_ RL_CAN_TX_MUX_ALIGNMT_CAL_DATA_0 m23 : 23|8@0+ (1,0) [0|0] ""  IPMA_ADAS
 SG_ RL_CAN_TX_MUX_ALIGNMT_CAL_DATA_1 m23 : 31|8@0+ (1,0) [0|0] ""  IPMA_ADAS
 SG_ RL_CAN_TX_MUX_ALIGNMT_CAL_DATA_2 m23 : 39|8@0+ (1,0) [0|0] ""  IPMA_ADAS
 SG_ RL_CAN_TX_MUX_ALIGNMT_CAL_DATA_3 m23 : 47|8@0+ (1,0) [0|0] ""  IPMA_ADAS
 SG_ RL_CAN_TX_MUX_ALIGNMT_CAL_DATA_4 m23 : 55|8@0+ (1,0) [0|0] ""  IPMA_ADAS
 SG_ RL_CAN_TX_MUX_ALIGNMT_CAL_DATA_5 m23 : 63|8@0+ (1,0) [0|0] ""  IPMA_ADAS
 SG_ RL_CAN_TX_MUX_TRKER_CAL_MSG_CNT m22 : 15|8@0+ (1,0) [0|0] ""  IPMA_ADAS
 SG_ RL_CAN_TX_MUX_TRKER_CAL_DATA_0 m22 : 23|8@0+ (1,0) [0|0] ""  IPMA_ADAS
 SG_ RL_CAN_TX_MUX_TRKER_CAL_DATA_1 m22 : 31|8@0+ (1,0) [0|0] ""  IPMA_ADAS
 SG_ RL_CAN_TX_MUX_TRKER_CAL_DATA_2 m22 : 39|8@0+ (1,0) [0|0] ""  IPMA_ADAS
 SG_ RL_CAN_TX_MUX_TRKER_CAL_DATA_3 m22 : 47|8@0+ (1,0) [0|0] ""  IPMA_ADAS
 SG_ RL_CAN_TX_MUX_TRKER_CAL_DATA_4 m22 : 55|8@0+ (1,0) [0|0] ""  IPMA_ADAS
 SG_ RL_CAN_TX_MUX_TRKER_CAL_DATA_5 m22 : 63|8@0+ (1,0) [0|0] ""  IPMA_ADAS
 SG_ RL_CAN_TX_MUX_SMC_CAL_MSG_CNT m21 : 15|8@0+ (1,0) [0|0] ""  IPMA_ADAS
 SG_ RL_CAN_TX_MUX_SMC_CAL_DATA_0 m21 : 23|8@0+ (1,0) [0|0] ""  IPMA_ADAS
 SG_ RL_CAN_TX_MUX_SMC_CAL_DATA_1 m21 : 31|8@0+ (1,0) [0|0] ""  IPMA_ADAS
 SG_ RL_CAN_TX_MUX_SMC_CAL_DATA_2 m21 : 39|8@0+ (1,0) [0|0] ""  IPMA_ADAS
 SG_ RL_CAN_TX_MUX_SMC_CAL_DATA_3 m21 : 47|8@0+ (1,0) [0|0] ""  IPMA_ADAS
 SG_ RL_CAN_TX_MUX_SMC_CAL_DATA_4 m21 : 55|8@0+ (1,0) [0|0] ""  IPMA_ADAS
 SG_ RL_CAN_TX_MUX_SMC_CAL_DATA_5 m21 : 63|8@0+ (1,0) [0|0] ""  IPMA_ADAS
 SG_ RL_CAN_TX_MUX_USC_CAL_MSG_CNT m20 : 15|8@0+ (1,0) [0|0] ""  IPMA_ADAS
 SG_ RL_CAN_TX_MUX_USC_CAL_DATA_0 m20 : 23|8@0+ (1,0) [0|0] ""  IPMA_ADAS
 SG_ RL_CAN_TX_MUX_USC_CAL_DATA_1 m20 : 31|8@0+ (1,0) [0|0] ""  IPMA_ADAS
 SG_ RL_CAN_TX_MUX_USC_CAL_DATA_2 m20 : 39|8@0+ (1,0) [0|0] ""  IPMA_ADAS
 SG_ RL_CAN_TX_MUX_USC_CAL_DATA_3 m20 : 47|8@0+ (1,0) [0|0] ""  IPMA_ADAS
 SG_ RL_CAN_TX_MUX_USC_CAL_DATA_4 m20 : 55|8@0+ (1,0) [0|0] ""  IPMA_ADAS
 SG_ RL_CAN_TX_MUX_USC_CAL_DATA_5 m20 : 63|8@0+ (1,0) [0|0] ""  IPMA_ADAS
 SG_ RL_CAN_TX_MUX_ALIGN_CAL_VER_MNR m18 : 15|16@0+ (1,0) [0|0] ""  IPMA_ADAS
 SG_ RL_CAN_TX_MUX_ALIGN_CAL_VER_MJR m18 : 31|16@0+ (1,0) [0|0] ""  IPMA_ADAS
 SG_ RL_CAN_TX_MUX_ALIGN_SW_VER_MINOR m19 : 15|16@0+ (1,0) [0|0] ""  IPMA_ADAS
 SG_ RL_CAN_TX_MUX_ALIGN_SW_VER_MAJOR m19 : 31|16@0+ (1,0) [0|0] ""  IPMA_ADAS
 SG_ RL_CAN_TX_MUX_USC_CAL_VER_MAJOR m2 : 15|32@0+ (1,0) [0|0] ""  IPMA_ADAS
 SG_ RL_CAN_TX_MUX_TRKR_CAL_VER_MINOR m4 : 15|16@0+ (1,0) [0|0] ""  IPMA_ADAS
 SG_ RL_CAN_TX_MUX_TRKR_CAL_VER_MAJOR m4 : 31|16@0+ (1,0) [0|0] ""  IPMA_ADAS
 SG_ RL_CAN_TX_MUX_TRKR_SW_VER_MINOR m11 : 15|16@0+ (1,0) [0|0] ""  IPMA_ADAS
 SG_ RL_CAN_TX_MUX_TRKR_SW_VER_MAJOR m11 : 31|16@0+ (1,0) [0|0] ""  IPMA_ADAS
 SG_ RL_CAN_TX_MUX_SMC_CAL_VER_MINOR m3 : 15|16@0+ (1,0) [0|0] ""  IPMA_ADAS
 SG_ RL_CAN_TX_MUX_SMC_CAL_VER_MAJOR m3 : 31|16@0+ (1,0) [0|0] ""  IPMA_ADAS
 SG_ RL_CAN_TX_MUX_RECW_CAL_VER_MINOR m8 : 15|16@0+ (1,0) [0|0] ""  IPMA_ADAS
 SG_ RL_CAN_TX_MUX_RECW_CAL_VER_MAJOR m8 : 31|16@0+ (1,0) [0|0] ""  IPMA_ADAS
 SG_ RL_CAN_TX_MUX_RECW_SW_VER_MINOR m12 : 15|16@0+ (1,0) [0|0] ""  IPMA_ADAS
 SG_ RL_CAN_TX_MUX_RECW_SW_VER_MAJOR m12 : 31|16@0+ (1,0) [0|0] ""  IPMA_ADAS
 SG_ RL_CAN_TX_MUX_RCWM_CAL_VER_MINOR m9 : 15|16@0+ (1,0) [0|0] ""  IPMA_ADAS
 SG_ RL_CAN_TX_MUX_RCWM_CAL_VER_MAJOR m9 : 31|16@0+ (1,0) [0|0] ""  IPMA_ADAS
 SG_ RL_CAN_TX_MUX_RCWM_SW_VER_MINOR m13 : 15|16@0+ (1,0) [0|0] ""  IPMA_ADAS
 SG_ RL_CAN_TX_MUX_RCWM_SW_VER_MAJOR m13 : 31|16@0+ (1,0) [0|0] ""  IPMA_ADAS
 SG_ RL_CAN_TX_MUX_RCTA_CAL_VER_MINOR m6 : 15|16@0+ (1,0) [0|0] ""  IPMA_ADAS
 SG_ RL_CAN_TX_MUX_RCTA_CAL_VER_MAJOR m6 : 31|16@0+ (1,0) [0|0] ""  IPMA_ADAS
 SG_ RL_CAN_TX_MUX_RCTA_SW_VER_MINOR m14 : 15|16@0+ (1,0) [0|0] ""  IPMA_ADAS
 SG_ RL_CAN_TX_MUX_RCTA_SW_VER_MAJOR m14 : 31|16@0+ (1,0) [0|0] ""  IPMA_ADAS
 SG_ RL_CAN_TX_MUX_LCDA_CAL_VER_MINOR m5 : 15|16@0+ (1,0) [0|0] ""  IPMA_ADAS
 SG_ RL_CAN_TX_MUX_LCDA_CAL_VER_MAJOR m5 : 31|16@0+ (1,0) [0|0] ""  IPMA_ADAS
 SG_ RL_CAN_TX_MUX_LCDA_SW_VER_MINOR m15 : 15|16@0+ (1,0) [0|0] ""  IPMA_ADAS
 SG_ RL_CAN_TX_MUX_LCDA_SW_VER_MAJOR m15 : 31|16@0+ (1,0) [0|0] ""  IPMA_ADAS
 SG_ RL_CAN_TX_MUX_FRESP_CAL_VER_MNR m10 : 15|16@0+ (1,0) [0|0] ""  IPMA_ADAS
 SG_ RL_CAN_TX_MUX_FRESP_CAL_VER_MJR m10 : 31|16@0+ (1,0) [0|0] ""  IPMA_ADAS
 SG_ RL_CAN_TX_MUX_FRESP_SW_VER_MINOR m16 : 15|16@0+ (1,0) [0|0] ""  IPMA_ADAS
 SG_ RL_CAN_TX_MUX_FRESP_SW_VER_MAJOR m16 : 31|16@0+ (1,0) [0|0] ""  IPMA_ADAS
 SG_ RL_CAN_TX_MUX_FCTA_CAL_VER_MINOR m7 : 15|16@0+ (1,0) [0|0] ""  IPMA_ADAS
 SG_ RL_CAN_TX_MUX_FCTA_CAL_VER_MAJOR m7 : 31|16@0+ (1,0) [0|0] ""  IPMA_ADAS
 SG_ RL_CAN_TX_MUX_FCTA_SW_VER_MINOR m17 : 15|16@0+ (1,0) [0|0] ""  IPMA_ADAS
 SG_ RL_CAN_TX_MUX_FCTA_SW_VER_MAJOR m17 : 31|16@0+ (1,0) [0|0] ""  IPMA_ADAS
 SG_ RL_CAN_TX_MUX_VCS_OFFSET_LONG m1 : 31|16@0+ (0.01,-655.35) [-655.35|0] "cm"  IPMA_ADAS
 SG_ RL_CAN_TX_MUX_VCS_OFFSET_LAT m1 : 15|16@0+ (0.01,-327.675) [-327.675|327.675] "cm"  IPMA_ADAS
 SG_ RL_CAN_TX_MUX_CORE_VERSION m0 : 63|8@0+ (1,0) [0|0] ""  IPMA_ADAS
 SG_ RL_CAN_TX_MUX_SENSOR_POLARITY m0 : 47|1@0+ (1,0) [0|1] ""  IPMA_ADAS
 SG_ RL_CAN_TX_MUX_SENSOR_LAT_OFFSET m0 : 46|15@0+ (0.01,-200) [-200|200] ""  IPMA_ADAS
 SG_ RL_CAN_TX_MUX_SENSOR_LONG_OFFSET m0 : 31|16@0+ (0.01,0) [0|655.35] "cm"  IPMA_ADAS
 SG_ RL_CAN_TX_MUX_SNSR_ANGLE_OFFSET m0 : 15|16@0+ (0.01,-200) [-200|200] "deg"  IPMA_ADAS
 SG_ RL_CAN_TX_MUX_KINK_ANGL_VER_MNR m30 : 15|16@0+ (1,0) [0|0] ""  IPMA_ADAS
 SG_ RL_CAN_TX_MUX_KINK_ANGL_VER_MJR m30 : 31|16@0+ (1,0) [0|0] ""  IPMA_ADAS
 SG_ RL_CAN_TX_MUX_ID M : 7|8@0+ (1,0) [0|255] ""  IPMA_ADAS

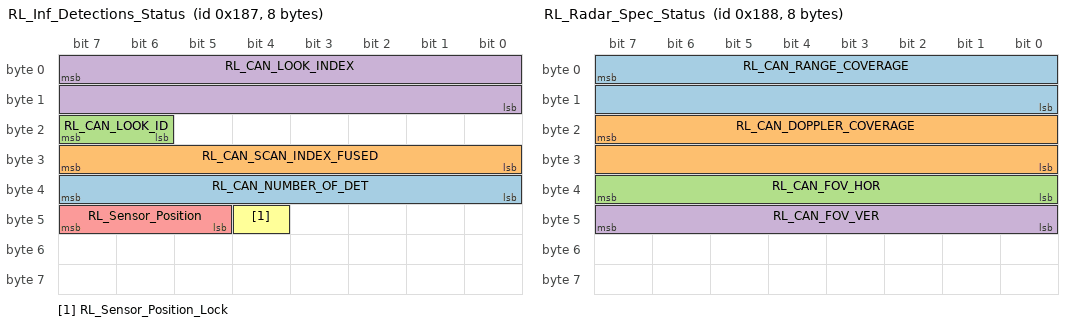
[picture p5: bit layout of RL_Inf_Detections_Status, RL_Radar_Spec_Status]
BO_ 391 RL_Inf_Detections_Status: 8 SODRL
 SG_ RL_CAN_NUMBER_OF_DET : 39|8@0+ (1,0) [0|255] ""  IPMA_ADAS
 SG_ RL_CAN_SCAN_INDEX_FUSED : 31|8@0+ (1,0) [0|255] ""  IPMA_ADAS
 SG_ RL_CAN_LOOK_ID : 23|2@0+ (1,0) [0|3] ""  IPMA_ADAS
 SG_ RL_CAN_LOOK_INDEX : 7|16@0+ (1,0) [0|65535] ""  IPMA_ADAS
 SG_ RL_Sensor_Position : 47|3@0+ (1,0) [0|0] ""  IPMA_ADAS
 SG_ RL_Sensor_Position_Lock : 44|1@0+ (1,0) [0|0] ""  IPMA_ADAS

BO_ 392 RL_Radar_Spec_Status: 8 SODRL
 SG_ RL_CAN_RANGE_COVERAGE : 7|16@0+ (0.00390625,0) [0|255.99609375] "m"  IPMA_ADAS
 SG_ RL_CAN_DOPPLER_COVERAGE : 23|16@0+ (0.00390625,-128) [-128|127.99609375] "m/s"  IPMA_ADAS
 SG_ RL_CAN_FOV_HOR : 39|8@0+ (1,0) [0|255] "deg"  IPMA_ADAS
 SG_ RL_CAN_FOV_VER : 47|8@0+ (1,0) [0|255] "deg"  IPMA_ADAS

BO_ 393 RL_Active_Flts_Status: 8 SODRL
 SG_ RL_CAN_ACTIVE_FAULTS : 7|64@0+ (1,0) [0|1.8446744074E+019] ""  IPMA_ADAS

BO_ 394 RL_Latch_Flts_Status: 8 SODRL
 SG_ RL_CAN_LATCH_FAULTS : 7|64@0+ (1,0) [0|1.84467E+019] ""  IPMA_ADAS

BO_ 397 RL_Status_Temp_Volt: 12 SODRL
 SG_ RL_CAN_Dolphin_AFC : 95|8@0+ (1,-50) [-50|205] "C"  External_Tool,IPMA_ADAS
 SG_ RL_CAN_Dolphin_Tx3 : 87|8@0+ (1,-50) [-50|205] "C"  External_Tool,IPMA_ADAS
 SG_ RL_CAN_Dolphin_Tx2 : 79|8@0+ (1,-50) [-50|205] "C"  External_Tool,IPMA_ADAS
 SG_ RL_CAN_1_8_V : 71|8@0+ (1,0) [0|0] ""  External_Tool,IPMA_ADAS
 SG_ RL_CAN_BATT_VOLTS : 63|8@0+ (0.08,0) [0|20.4] "V"  External_Tool,IPMA_ADAS
 SG_ RL_CAN_1_25_V : 55|8@0+ (0.08,0) [0|20.4] "V"  External_Tool,IPMA_ADAS
 SG_ RL_CAN_5_V : 47|8@0+ (0.08,0) [0|20.4] "V"  External_Tool,IPMA_ADAS
 SG_ RL_CAN_1_1_V : 31|8@0+ (0.08,0) [0|20.4] "V"  External_Tool,IPMA_ADAS
 SG_ RL_CAN_2_3_V : 15|8@0+ (0.08,0) [0|20.4] "V"  External_Tool,IPMA_ADAS
 SG_ RL_CAN_Dolphin_Tx1 : 39|8@0+ (1,-50) [-50|205] "C"  External_Tool,IPMA_ADAS
 SG_ RL_CAN_OnBoard_Thermistor : 23|8@0+ (1,-50) [-50|205] "C"  External_Tool,IPMA_ADAS
 SG_ RL_CAN_RRU_Temp1 : 7|8@0+ (1,-50) [-50|205] "C"  External_Tool,IPMA_ADAS

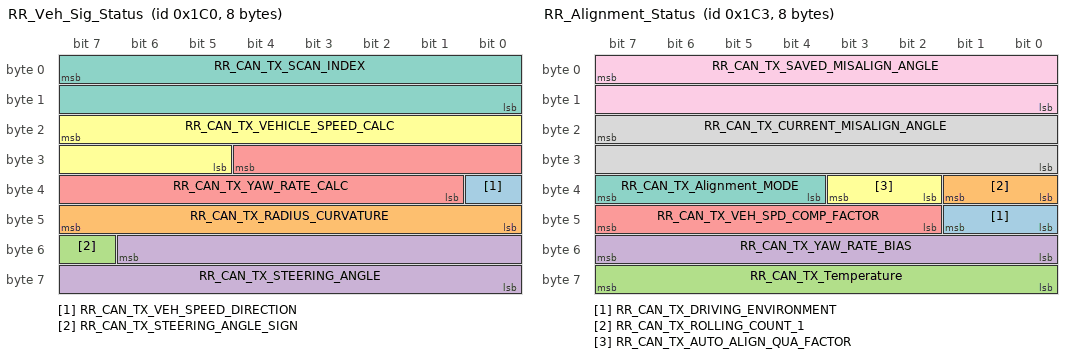
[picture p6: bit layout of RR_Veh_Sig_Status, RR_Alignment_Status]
BO_ 448 RR_Veh_Sig_Status: 8 SODRR
 SG_ RR_CAN_TX_VEH_SPEED_DIRECTION : 32|1@0+ (1,0) [0|0] ""  IPMA_ADAS
 SG_ RR_CAN_TX_RADIUS_CURVATURE : 47|8@0- (25,0) [-3200|3200] "m"  IPMA_ADAS
 SG_ RR_CAN_TX_STEERING_ANGLE_SIGN : 55|1@0+ (1,0) [0|1] ""  IPMA_ADAS
 SG_ RR_CAN_TX_STEERING_ANGLE : 54|15@0+ (1,0) [0|32767] "deg"  IPMA_ADAS
 SG_ RR_CAN_TX_YAW_RATE_CALC : 28|12@0- (0.0625,0) [-128|127.9375] "deg/s"  IPMA_ADAS
 SG_ RR_CAN_TX_VEHICLE_SPEED_CALC : 23|11@0+ (0.0625,0) [0|127.9375] "m/s"  IPMA_ADAS
 SG_ RR_CAN_TX_SCAN_INDEX : 7|16@0+ (1,0) [0|65535] ""  IPMA_ADAS

BO_ 449 RR_HW_Version_Status: 64 SODRR
 SG_ RR_Dolphin_Chip_ID_Part2 : 391|64@0+ (1,0) [0|0] ""  IPMA_ADAS
 SG_ RR_Dolphin_Chip_ID_Part1 : 327|64@0+ (1,0) [0|0] ""  IPMA_ADAS
 SG_ RR_RRU_Chip_ID_Part4 : 263|64@0+ (1,0) [0|0] ""  IPMA_ADAS
 SG_ RR_RRU_Chip_ID_Part3 : 199|64@0+ (1,0) [0|0] ""  IPMA_ADAS
 SG_ RR_RRU_Chip_ID_Part2 : 135|64@0+ (1,0) [0|0] ""  IPMA_ADAS
 SG_ RR_RRU_Chip_ID_Part1 : 71|64@0+ (1,0) [0|0] ""  IPMA_ADAS
 SG_ RR_CAN_TX_SW_VERSION_DSP : 47|24@0+ (1,0) [0|0] ""  IPMA_ADAS
 SG_ RR_CAN_TX_PCAN_PROTOCOL_MINOR : 15|8@0+ (1,0) [0|255] ""  IPMA_ADAS
 SG_ RR_CAN_TX_PCAN_PROTOCOL_MAJOR : 3|4@0+ (1,0) [0|15] ""  IPMA_ADAS
 SG_ RR_CAN_TX_SW_VERSION_ARM : 23|24@0+ (1,0) [0|0] ""  IPMA_ADAS
 SG_ RR_CAN_TX_HW_VERSION : 7|4@0+ (1,0) [0|0] ""  IPMA_ADAS

BO_ 450 RR_SW_Version_Status: 16 SODRR
 SG_ RR_CAN_TX_Field : 47|8@0+ (1,0) [0|0] ""  IPMA_ADAS
 SG_ RR_CAN_TX_Promote : 13|6@0+ (1,0) [0|0] ""  IPMA_ADAS
 SG_ RR_CAN_TX_Major : 3|6@0+ (1,0) [0|0] ""  IPMA_ADAS
 SG_ RR_CAN_TX_Hardware : 7|4@0+ (1,0) [0|0] ""  IPMA_ADAS
 SG_ RR_CAN_TX_SERIAL_NUMBER_SEQUENCE : 27|12@0+ (1,0) [0|0] ""  IPMA_ADAS
 SG_ RR_CAN_TX_SERIAL_NUM_JULIAN_YEAR : 30|3@0+ (1,2014) [0|0] ""  IPMA_ADAS
 SG_ RR_CAN_TX_SERIAL_NUM_JULIAN_DAY : 23|9@0+ (1,0) [0|0] ""  IPMA_ADAS
 SG_ RR_CAN_TX_ARM_THROUGHPUT : 63|5@0+ (3.2258,0) [0|0] ""  IPMA_ADAS
 SG_ RR_CAN_TX_SYSTEM_STATUS : 58|3@0+ (1,0) [0|0] ""  IPMA_ADAS
 SG_ RR_CAN_TX_LOOK_TYPE_1 : 50|1@0+ (1,0) [0|0] ""  IPMA_ADAS
 SG_ RR_CAN_TX_OVERHEAT_ERROR : 51|1@0+ (1,0) [0|0] ""  IPMA_ADAS
 SG_ RR_CAN_TX_RANGE_PERF_ERROR : 52|1@0+ (1,0) [0|0] ""  IPMA_ADAS
 SG_ RR_CAN_TX_COMM_ERROR : 53|1@0+ (1,0) [0|0] ""  IPMA_ADAS
 SG_ RR_CAN_TX_INTERNAL_ERROR : 54|1@0+ (1,0) [0|0] ""  IPMA_ADAS
 SG_ RR_CAN_TX_XCVR_OPERATIONAL : 55|1@0+ (1,0) [0|0] ""  IPMA_ADAS
 SG_ RR_CAN_PBL_Field_Revision : 119|8@0+ (1,0) [0|255] ""  IPMA_ADAS
 SG_ RR_CAN_PBL_Promote_Revision : 111|8@0+ (1,0) [0|255] ""  IPMA_ADAS
 SG_ RR_CAN_SW_Field_Revision : 87|8@0+ (1,0) [0|255] ""  IPMA_ADAS
 SG_ RR_CAN_SW_Promote_Revision : 79|8@0+ (1,0) [0|255] ""  IPMA_ADAS
 SG_ RR_CAN_SW_Field : 95|8@0+ (1,0) [0|255] ""  IPMA_ADAS
 SG_ RR_CAN_SW_Release_Revision : 71|8@0+ (1,0) [0|255] ""  IPMA_ADAS
 SG_ RR_CAN_PBL_Release_Revision : 103|8@0+ (1,0) [0|255] ""  IPMA_ADAS

BO_ 451 RR_Alignment_Status: 8 SODRR
 SG_ RR_CAN_TX_DRIVING_ENVIRONMENT : 41|2@0+ (1,0) [0|0] ""  IPMA_ADAS
 SG_ RR_CAN_TX_ROLLING_COUNT_1 : 33|2@0+ (1,0) [0|0] ""  IPMA_ADAS
 SG_ RR_CAN_TX_Temperature : 63|8@0+ (1,-50) [-50|205] "degC"  IPMA_ADAS
 SG_ RR_CAN_TX_YAW_RATE_BIAS : 55|8@0- (0.125,0) [-16|15.875] ""  IPMA_ADAS
 SG_ RR_CAN_TX_VEH_SPD_COMP_FACTOR : 47|6@0- (0.001953125,1) [0.9375|1.060546875] ""  IPMA_ADAS
 SG_ RR_CAN_TX_AUTO_ALIGN_QUA_FACTOR : 35|2@0+ (1,0) [0|0] ""  IPMA_ADAS
 SG_ RR_CAN_TX_Alignment_MODE : 39|4@0+ (1,0) [0|0] ""  IPMA_ADAS
 SG_ RR_CAN_TX_CURRENT_MISALIGN_ANGLE : 23|16@0- (0.0009765625,0) [-10|10] "Deg"  IPMA_ADAS
 SG_ RR_CAN_TX_SAVED_MISALIGN_ANGLE : 7|16@0- (0.0009765625,0) [-10|10] "Deg"  IPMA_ADAS

BO_ 452 RR_Fault_Status: 8 SODRR
 SG_ RR_Supply_2_3v_Out_Of_Range_Flt : 9|1@0+ (1,0) [0|0] ""  IPMA_ADAS
 SG_ RR_Supply_1_25v_Out_Of_Range_Flt : 10|1@0+ (1,0) [0|0] ""  IPMA_ADAS
 SG_ RR_Software_Incompatible_Flt : 61|1@0+ (1,0) [0|0] ""  IPMA_ADAS
 SG_ RR_Host_Spi_Checksum_Flt : 60|1@0+ (1,0) [0|0] ""  IPMA_ADAS
 SG_ RR_Loss_Of_Comm_With_Dsp_Flt : 59|1@0+ (1,0) [0|0] ""  IPMA_ADAS
 SG_ RR_No_Communication_With_Arm_Flt : 58|1@0+ (1,0) [0|0] ""  IPMA_ADAS
 SG_ RR_Communication_With_Host_Flt : 57|1@0+ (1,0) [0|0] ""  IPMA_ADAS
 SG_ RR_Communication_With_Arm_Flt : 56|1@0+ (1,0) [0|0] ""  IPMA_ADAS
 SG_ RR_Dsp_Loop_Overrun_Flt_Dsp : 51|1@0+ (1,0) [0|0] ""  IPMA_ADAS
 SG_ RR_Tuning_Sensitivity_Flt : 50|1@0+ (1,0) [0|0] ""  IPMA_ADAS
 SG_ RR_Saturated_Tuning_Freq_Flt : 49|1@0+ (1,0) [0|0] ""  IPMA_ADAS
 SG_ RR_Local_Oscillator_Power_Flt : 48|1@0+ (1,0) [0|0] ""  IPMA_ADAS
 SG_ RR_Transmitter_Power_Flt : 47|1@0+ (1,0) [0|0] ""  IPMA_ADAS
 SG_ RR_Radar_Data_Sync_Flt : 46|1@0+ (1,0) [0|0] ""  IPMA_ADAS
 SG_ RR_Dsp_Spi_Hardware_Flt : 45|1@0+ (1,0) [0|0] ""  IPMA_ADAS
 SG_ RR_Transmitter_Device_Spi_Flt : 44|1@0+ (1,0) [0|0] ""  IPMA_ADAS
 SG_ RR_Receiver_Device_Spi_Flt : 43|1@0+ (1,0) [0|0] ""  IPMA_ADAS
 SG_ RR_Freq_Synthe_Device_Spi_Flt : 42|1@0+ (1,0) [0|0] ""  IPMA_ADAS
 SG_ RR_Analog_Cnvrtr_Device_Spi_Flt : 41|1@0+ (1,0) [0|0] ""  IPMA_ADAS
 SG_ RR_Transmitter_Id_Flt : 40|1@0+ (1,0) [0|0] ""  IPMA_ADAS
 SG_ RR_Ecu_Temperature_High_Flt : 39|1@0+ (1,0) [0|0] ""  IPMA_ADAS
 SG_ RR_Transmitter_Temp_High_Flt : 38|1@0+ (1,0) [0|0] ""  IPMA_ADAS
 SG_ RR_Alignment_Routine_Failed_Flt : 37|1@0+ (1,0) [0|0] ""  IPMA_ADAS
 SG_ RR_Unreasonable_Radar_Data : 36|1@0+ (1,0) [0|0] ""  IPMA_ADAS
 SG_ RR_Sensor_Blocked_Flt : 35|1@0+ (1,0) [0|0] ""  IPMA_ADAS
 SG_ RR_Vertical_Alignt_Out_Of_Range : 34|1@0+ (1,0) [0|0] ""  IPMA_ADAS
 SG_ RR_Horizontal_Align_Out_Of_Range : 33|1@0+ (1,0) [0|0] ""  IPMA_ADAS
 SG_ RR_Factory_Alignment_Mode : 32|1@0+ (1,0) [0|0] ""  IPMA_ADAS
 SG_ RR_Battery_Low_Flt : 30|1@0+ (1,0) [0|0] ""  IPMA_ADAS
 SG_ RR_Battery_High_Flt : 29|1@0+ (1,0) [0|0] ""  IPMA_ADAS
 SG_ RR_Ecu_Position_Config_Flt : 28|1@0+ (1,0) [0|0] ""  IPMA_ADAS
 SG_ RR_Supply_1_1v_Out_Of_Range_Flt : 27|1@0+ (1,0) [0|0] ""  IPMA_ADAS
 SG_ RR_Supply_1_8v_Out_Of_Range_Flt : 26|1@0+ (1,0) [0|0] ""  IPMA_ADAS
 SG_ RR_Thermistor_Out_Of_Range_Flt : 25|1@0+ (1,0) [0|0] ""  IPMA_ADAS
 SG_ RR_Supply_5v_Out_Of_Range_Flt : 24|1@0+ (1,0) [0|0] ""  IPMA_ADAS
 SG_ RR_Pcan_Init_Missing_Message_Flt : 22|1@0+ (1,0) [0|0] ""  IPMA_ADAS
 SG_ RR_Pcan_Trk_Data_Unreasnble_Flt : 21|1@0+ (1,0) [0|0] ""  IPMA_ADAS
 SG_ RR_Pcan_Data_Range_Check_Flt : 20|1@0+ (1,0) [0|0] ""  IPMA_ADAS
 SG_ RR_Pcan_Missing_Message_Flt : 19|1@0+ (1,0) [0|0] ""  IPMA_ADAS
 SG_ RR_Pcan_Hw_Rx_Buffer_Flt : 18|1@0+ (1,0) [0|0] ""  IPMA_ADAS
 SG_ RR_Pcan_Sw_Buffer_Flt : 17|1@0+ (1,0) [0|0] ""  IPMA_ADAS
 SG_ RR_Pcan_Bus_Off : 16|1@0+ (1,0) [0|0] ""  IPMA_ADAS
 SG_ RR_Host_Instrctn_Set_Check_Flt : 15|1@0+ (1,0) [0|0] ""  IPMA_ADAS
 SG_ RR_Host_Stack_Overflow_Flt : 14|1@0+ (1,0) [0|0] ""  IPMA_ADAS
 SG_ RR_Sensor_Watchdog_Flt : 13|1@0+ (1,0) [0|0] ""  IPMA_ADAS
 SG_ RR_Sensor_Pll_Lock_Flt : 12|1@0+ (1,0) [0|0] ""  IPMA_ADAS
 SG_ RR_Host_Pll_Lock_Flt : 11|1@0+ (1,0) [0|0] ""  IPMA_ADAS
 SG_ RR_Sensor_Ram_Memory_Test_Flt : 8|1@0+ (1,0) [0|0] ""  IPMA_ADAS
 SG_ RR_Host_Ram_Memory_Test_Flt : 7|1@0+ (1,0) [0|0] ""  IPMA_ADAS
 SG_ RR_Snsr_Custmr_Cal_Flsh_Chksum : 6|1@0+ (1,0) [0|0] ""  IPMA_ADAS
 SG_ RR_Dsp_Usc_Validation_Flt : 5|1@0+ (1,0) [0|0] ""  IPMA_ADAS
 SG_ RR_Snsr_Pgrm_Cal_Flsh_Chksum : 4|1@0+ (1,0) [0|0] ""  IPMA_ADAS
 SG_ RR_Sensor_App_Flash_Checksum_Flt : 3|1@0+ (1,0) [0|0] ""  IPMA_ADAS
 SG_ RR_Host_Kp_Alv_Flsh_Chcksm_Flt : 2|1@0+ (1,0) [0|0] ""  IPMA_ADAS
 SG_ RR_Host_Pgm_Cal_Flsh_Chcksum_Flt : 1|1@0+ (1,0) [0|0] ""  IPMA_ADAS
 SG_ RR_Host_App_Flash_Checksum_Flt : 0|1@0+ (1,0) [0|0] ""  IPMA_ADAS

BO_ 453 RR_Error_Status: 12 SODRR
 SG_ RR_Dolphin_Fault_Detection : 87|8@0+ (1,0) [0|63] ""  IPMA_ADAS
 SG_ RR_RRU_Self_Test_Faults : 79|8@0+ (1,0) [0|63] ""  IPMA_ADAS
 SG_ RR_RRU_Core_Faults : 71|8@0+ (1,0) [0|63] ""  IPMA_ADAS
 SG_ RR_USC_Load_Error : 59|1@0+ (1,0) [0|0] ""  IPMA_ADAS
 SG_ RR_SMC_Load_Error : 58|1@0+ (1,0) [0|0] ""  IPMA_ADAS
 SG_ RR_TX_Temperature_Flt : 57|1@0+ (1,0) [0|0] ""  IPMA_ADAS
 SG_ RR_Dsp_Unit_Cal_Blk_Chcksm_Error : 56|1@0+ (1,0) [0|0] ""  IPMA_ADAS
 SG_ RR_Dsp_Unit_Cal_Checksum_Error : 55|1@0+ (1,0) [0|0] ""  IPMA_ADAS
 SG_ RR_Vertical_Misalignment_error : 54|1@0+ (1,0) [0|0] ""  IPMA_ADAS
 SG_ RR_RTN_SPI_Transfer_Error : 53|1@0+ (1,0) [0|0] ""  IPMA_ADAS
 SG_ RR_RRN_SPI_Transfer_Error : 52|1@0+ (1,0) [0|0] ""  IPMA_ADAS
 SG_ RR_Linearizer_SPI_Transfer_Error : 51|1@0+ (1,0) [0|0] ""  IPMA_ADAS
 SG_ RR_ADC_SPI_Transfer_Error : 50|1@0+ (1,0) [0|0] ""  IPMA_ADAS
 SG_ RR_Transmitter_ID_Error : 49|1@0+ (1,0) [0|0] ""  IPMA_ADAS
 SG_ RR_Dsp_Loop_Overrun_Error : 48|1@0+ (1,0) [0|0] ""  IPMA_ADAS
 SG_ RR_Saturated_Tuning_Freq_Error : 47|1@0+ (1,0) [0|0] ""  IPMA_ADAS
 SG_ RR_Radar_Data_sync_error : 46|1@0+ (1,0) [0|0] ""  IPMA_ADAS
 SG_ RR_Dsp_Tuning_Sensitivity_Error : 45|1@0+ (1,0) [0|0] ""  IPMA_ADAS
 SG_ RR_Radar_LO_Power_Error : 44|1@0+ (1,0) [0|0] ""  IPMA_ADAS
 SG_ RR_Radar_TX_Power_Error : 43|1@0+ (1,0) [0|0] ""  IPMA_ADAS
 SG_ RR_Timer_Create_Error : 6|1@0+ (1,0) [0|0] ""  IPMA_ADAS
 SG_ RR_Thread_Create_Error : 2|1@0+ (1,0) [0|0] ""  IPMA_ADAS
 SG_ RR_ARM_Calibration_Error : 9|1@0+ (1,0) [0|0] ""  IPMA_ADAS
 SG_ RR_SPI_FEE_Error : 14|1@0+ (1,0) [0|0] ""  IPMA_ADAS
 SG_ RR_SPI_Comm_Error : 13|1@0+ (1,0) [0|0] ""  IPMA_ADAS
 SG_ RR_Socket_Write_Error : 39|1@0+ (1,0) [0|0] ""  IPMA_ADAS
 SG_ RR_Socket_Read_error : 38|1@0+ (1,0) [0|0] ""  IPMA_ADAS
 SG_ RR_Socket_Init_Error : 37|1@0+ (1,0) [0|0] ""  IPMA_ADAS
 SG_ RR_Signal_Wait_Error : 4|1@0+ (1,0) [0|0] ""  IPMA_ADAS
 SG_ RR_Signal_Send_Error : 5|1@0+ (1,0) [0|0] ""  IPMA_ADAS
 SG_ RR_Signal_Create_Error : 3|1@0+ (1,0) [0|0] ""  IPMA_ADAS
 SG_ RR_Shared_Mem_Write_Error : 21|1@0+ (1,0) [0|0] ""  IPMA_ADAS
 SG_ RR_Shared_Mem_Read_Error : 20|1@0+ (1,0) [0|0] ""  IPMA_ADAS
 SG_ RR_Shared_Mem_Config_Error : 19|1@0+ (1,0) [0|0] ""  IPMA_ADAS
 SG_ RR_Share_Mem_Init_Error : 18|1@0+ (1,0) [0|0] ""  IPMA_ADAS
 SG_ RR_RAM_Test_Error : 1|1@0+ (1,0) [0|0] ""  IPMA_ADAS
 SG_ RR_Num_Errors : 63|1@0+ (1,0) [0|0] ""  IPMA_ADAS
 SG_ RR_MMAP_Memory_Error : 40|1@0+ (1,0) [0|0] ""  IPMA_ADAS
 SG_ RR_ISR_Attach_Error : 36|1@0+ (1,0) [0|0] ""  IPMA_ADAS
 SG_ RR_IPC_DRV_Write_Error : 29|1@0+ (1,0) [0|0] ""  IPMA_ADAS
 SG_ RR_IPC_DRV_Trigger_Error : 31|1@0+ (1,0) [0|0] ""  IPMA_ADAS
 SG_ RR_IPC_DRV_Sync_Error : 30|1@0+ (1,0) [0|0] ""  IPMA_ADAS
 SG_ RR_IPC_DRV_Read_Error : 28|1@0+ (1,0) [0|0] ""  IPMA_ADAS
 SG_ RR_IPC_DRV_Init_Error : 27|1@0+ (1,0) [0|0] ""  IPMA_ADAS
 SG_ RR_Interrupt_Enable_Error : 42|1@0+ (1,0) [0|0] ""  IPMA_ADAS
 SG_ RR_HIL_Format_Error : 41|1@0+ (1,0) [0|0] ""  IPMA_ADAS
 SG_ RR_Flash_Filesystem_Error : 7|1@0+ (1,0) [0|0] ""  IPMA_ADAS
 SG_ RR_Error_none : 0|1@0+ (1,0) [0|0] ""  IPMA_ADAS
 SG_ RR_Dsp_Load_Read_Error : 34|1@0+ (1,0) [0|0] ""  IPMA_ADAS
 SG_ RR_Dsp_Load_Open_Error : 33|1@0+ (1,0) [0|0] ""  IPMA_ADAS
 SG_ RR_Dsp_Load_Address_Error : 35|1@0+ (1,0) [0|0] ""  IPMA_ADAS
 SG_ RR_Dsp_ISP_Write_Error : 17|1@0+ (1,0) [0|0] ""  IPMA_ADAS
 SG_ RR_Dsp_IPC_Read_Error : 16|1@0+ (1,0) [0|0] ""  IPMA_ADAS
 SG_ RR_Dsp_IPC_Init : 15|1@0+ (1,0) [0|0] ""  IPMA_ADAS
 SG_ RR_Dsp_Init_Error : 32|1@0+ (1,0) [0|0] ""  IPMA_ADAS
 SG_ RR_Dsp_DRV_Start_Error : 26|1@0+ (1,0) [0|0] ""  IPMA_ADAS
 SG_ RR_Dsp_DRV_Load_Error : 25|1@0+ (1,0) [0|0] ""  IPMA_ADAS
 SG_ RR_Dsp_DRV_Init_Error : 22|1@0+ (1,0) [0|0] ""  IPMA_ADAS
 SG_ RR_Dsp_DRV_Init2_error : 24|1@0+ (1,0) [0|0] ""  IPMA_ADAS
 SG_ RR_Dsp_DRV_Init1_error : 23|1@0+ (1,0) [0|0] ""  IPMA_ADAS
 SG_ RR_CAN_XMT_Error : 10|1@0+ (1,0) [0|0] ""  IPMA_ADAS
 SG_ RR_CAN_RCV_Error : 11|1@0+ (1,0) [0|0] ""  IPMA_ADAS
 SG_ RR_CAN_Hardware_Error : 12|1@0+ (1,0) [0|0] ""  IPMA_ADAS
 SG_ RR_Always_True : 62|1@0+ (1,0) [0|0] ""  IPMA_ADAS

BO_ 454 RR_General_Info_Status: 8 SODRR
 SG_ RR_CAN_TX_MUX_SVK_CAL_DATA_5 m128 : 63|8@0+ (1,0) [0|0] ""  IPMA_ADAS
 SG_ RR_CAN_TX_MUX_SVK_CAL_DATA_4 m128 : 55|8@0+ (1,0) [0|0] ""  IPMA_ADAS
 SG_ RR_CAN_TX_MUX_SVK_CAL_DATA_3 m128 : 47|8@0+ (1,0) [0|0] ""  IPMA_ADAS
 SG_ RR_CAN_TX_MUX_SVK_CAL_DATA_2 m128 : 39|8@0+ (1,0) [0|0] ""  IPMA_ADAS
 SG_ RR_CAN_TX_MUX_SVK_CAL_DATA_1 m128 : 31|8@0+ (1,0) [0|0] ""  IPMA_ADAS
 SG_ RR_CAN_TX_MUX_SVK_CAL_DATA_0 m128 : 23|8@0+ (1,0) [0|0] ""  IPMA_ADAS
 SG_ RR_CAN_TX_MUX_SVK_CAL_MSG_CNT m128 : 15|8@0+ (1,0) [0|0] ""  IPMA_ADAS
 SG_ RR_CAN_TX_MUX_RCWM_CAL_MSG_CNT m29 : 15|8@0+ (1,0) [0|0] ""  IPMA_ADAS
 SG_ RR_CAN_TX_MUX_RCWM_CAL_DATA_0 m29 : 23|8@0+ (1,0) [0|0] ""  IPMA_ADAS
 SG_ RR_CAN_TX_MUX_RCWM_CAL_DATA_1 m29 : 31|8@0+ (1,0) [0|0] ""  IPMA_ADAS
 SG_ RR_CAN_TX_MUX_RCWM_CAL_DATA_2 m29 : 39|8@0+ (1,0) [0|0] ""  IPMA_ADAS
 SG_ RR_CAN_TX_MUX_RCWM_CAL_DATA_3 m29 : 47|8@0+ (1,0) [0|0] ""  IPMA_ADAS
 SG_ RR_CAN_TX_MUX_RCWM_CAL_DATA_4 m29 : 55|8@0+ (1,0) [0|0] ""  IPMA_ADAS
 SG_ RR_CAN_TX_MUX_RCWM_CAL_DATA_5 m29 : 63|8@0+ (1,0) [0|0] ""  IPMA_ADAS
 SG_ RR_CAN_TX_MUX_RECW_CAL_MSG_CNT m28 : 15|8@0+ (1,0) [0|0] ""  IPMA_ADAS
 SG_ RR_CAN_TX_MUX_RECW_CAL_DATA_0 m28 : 23|8@0+ (1,0) [0|0] ""  IPMA_ADAS
 SG_ RR_CAN_TX_MUX_RECW_CAL_DATA_1 m28 : 31|8@0+ (1,0) [0|0] ""  IPMA_ADAS
 SG_ RR_CAN_TX_MUX_RECW_CAL_DATA_2 m28 : 39|8@0+ (1,0) [0|0] ""  IPMA_ADAS
 SG_ RR_CAN_TX_MUX_RECW_CAL_DATA_3 m28 : 47|8@0+ (1,0) [0|0] ""  IPMA_ADAS
 SG_ RR_CAN_TX_MUX_RECW_CAL_DATA_4 m28 : 55|8@0+ (1,0) [0|0] ""  IPMA_ADAS
 SG_ RR_CAN_TX_MUX_RECW_CAL_DATA_5 m28 : 63|8@0+ (1,0) [0|0] ""  IPMA_ADAS
 SG_ RR_CAN_TX_MUX_FRESPCE_CALMSG_CNT m27 : 15|8@0+ (1,0) [0|0] ""  IPMA_ADAS
 SG_ RR_CAN_TX_MUX_FRESPCE_CAL_DATA_0 m27 : 23|8@0+ (1,0) [0|0] ""  IPMA_ADAS
 SG_ RR_CAN_TX_MUX_FRESPCE_CAL_DATA_1 m27 : 31|8@0+ (1,0) [0|0] ""  IPMA_ADAS
 SG_ RR_CAN_TX_MUX_FRESPCE_CAL_DATA_2 m27 : 39|8@0+ (1,0) [0|0] ""  IPMA_ADAS
 SG_ RR_CAN_TX_MUX_FRESPCE_CAL_DATA_3 m27 : 47|8@0+ (1,0) [0|0] ""  IPMA_ADAS
 SG_ RR_CAN_TX_MUX_FRESPCE_CAL_DATA_4 m27 : 55|8@0+ (1,0) [0|0] ""  IPMA_ADAS
 SG_ RR_CAN_TX_MUX_FRESPCE_CAL_DATA_5 m27 : 63|8@0+ (1,0) [0|0] ""  IPMA_ADAS
 SG_ RR_CAN_TX_MUX_LCDA_CAL_MSG_CNT m26 : 15|8@0+ (1,0) [0|0] ""  IPMA_ADAS
 SG_ RR_CAN_TX_MUX_LCDA_CAL_DATA_0 m26 : 23|8@0+ (1,0) [0|0] ""  IPMA_ADAS
 SG_ RR_CAN_TX_MUX_LCDA_CAL_DATA_1 m26 : 31|8@0+ (1,0) [0|0] ""  IPMA_ADAS
 SG_ RR_CAN_TX_MUX_LCDA_CAL_DATA_2 m26 : 39|8@0+ (1,0) [0|0] ""  IPMA_ADAS
 SG_ RR_CAN_TX_MUX_LCDA_CAL_DATA_3 m26 : 47|8@0+ (1,0) [0|0] ""  IPMA_ADAS
 SG_ RR_CAN_TX_MUX_LCDA_CAL_DATA_4 m26 : 55|8@0+ (1,0) [0|0] ""  IPMA_ADAS
 SG_ RR_CAN_TX_MUX_LCDA_CAL_DATA_5 m26 : 63|8@0+ (1,0) [0|0] ""  IPMA_ADAS
 SG_ RR_CAN_TX_MUX_CTA_CAL_MSG_CNT m25 : 15|8@0+ (1,0) [0|0] ""  IPMA_ADAS
 SG_ RR_CAN_TX_MUX_CTA_CAL_DATA_0 m25 : 23|8@0+ (1,0) [0|0] ""  IPMA_ADAS
 SG_ RR_CAN_TX_MUX_CTA_CAL_DATA_1 m25 : 31|8@0+ (1,0) [0|0] ""  IPMA_ADAS
 SG_ RR_CAN_TX_MUX_CTA_CAL_DATA_2 m25 : 39|8@0+ (1,0) [0|0] ""  IPMA_ADAS
 SG_ RR_CAN_TX_MUX_CTA_CAL_DATA_3 m25 : 47|8@0+ (1,0) [0|0] ""  IPMA_ADAS
 SG_ RR_CAN_TX_MUX_CTA_CAL_DATA_4 m25 : 55|8@0+ (1,0) [0|0] ""  IPMA_ADAS
 SG_ RR_CAN_TX_MUX_CTA_CAL_DATA_5 m25 : 63|8@0+ (1,0) [0|0] ""  IPMA_ADAS
 SG_ RR_CAN_TX_MUX_LOOKID_CAL_MSG_CNT m24 : 15|8@0+ (1,0) [0|0] ""  IPMA_ADAS
 SG_ RR_CAN_TX_MUX_LOOKID_CAL_DATA_0 m24 : 23|8@0+ (1,0) [0|0] ""  IPMA_ADAS
 SG_ RR_CAN_TX_MUX_LOOKID_CAL_DATA_1 m24 : 31|8@0+ (1,0) [0|0] ""  IPMA_ADAS
 SG_ RR_CAN_TX_MUX_LOOKID_CAL_DATA_2 m24 : 39|8@0+ (1,0) [0|0] ""  IPMA_ADAS
 SG_ RR_CAN_TX_MUX_LOOKID_CAL_DATA_3 m24 : 47|8@0+ (1,0) [0|0] ""  IPMA_ADAS
 SG_ RR_CAN_TX_MUX_LOOKID_CAL_DATA_4 m24 : 55|8@0+ (1,0) [0|0] ""  IPMA_ADAS
 SG_ RR_CAN_TX_MUX_LOOKID_CAL_DATA_5 m24 : 63|8@0+ (1,0) [0|0] ""  IPMA_ADAS
 SG_ RR_CAN_TX_MUX_ALIGNMT_CALMSG_CNT m23 : 15|8@0+ (1,0) [0|0] ""  IPMA_ADAS
 SG_ RR_CAN_TX_MUX_ALIGNMT_CAL_DATA_0 m23 : 23|8@0+ (1,0) [0|0] ""  IPMA_ADAS
 SG_ RR_CAN_TX_MUX_ALIGNMT_CAL_DATA_1 m23 : 31|8@0+ (1,0) [0|0] ""  IPMA_ADAS
 SG_ RR_CAN_TX_MUX_ALIGNMT_CAL_DATA_2 m23 : 39|8@0+ (1,0) [0|0] ""  IPMA_ADAS
 SG_ RR_CAN_TX_MUX_ALIGNMT_CAL_DATA_3 m23 : 47|8@0+ (1,0) [0|0] ""  IPMA_ADAS
 SG_ RR_CAN_TX_MUX_ALIGNMT_CAL_DATA_4 m23 : 55|8@0+ (1,0) [0|0] ""  IPMA_ADAS
 SG_ RR_CAN_TX_MUX_ALIGNMT_CAL_DATA_5 m23 : 63|8@0+ (1,0) [0|0] ""  IPMA_ADAS
 SG_ RR_CAN_TX_MUX_TRKER_CAL_MSG_CNT m22 : 15|8@0+ (1,0) [0|0] ""  IPMA_ADAS
 SG_ RR_CAN_TX_MUX_TRKER_CAL_DATA_0 m22 : 23|8@0+ (1,0) [0|0] ""  IPMA_ADAS
 SG_ RR_CAN_TX_MUX_TRKER_CAL_DATA_1 m22 : 31|8@0+ (1,0) [0|0] ""  IPMA_ADAS
 SG_ RR_CAN_TX_MUX_TRKER_CAL_DATA_2 m22 : 39|8@0+ (1,0) [0|0] ""  IPMA_ADAS
 SG_ RR_CAN_TX_MUX_TRKER_CAL_DATA_3 m22 : 47|8@0+ (1,0) [0|0] ""  IPMA_ADAS
 SG_ RR_CAN_TX_MUX_TRKER_CAL_DATA_4 m22 : 55|8@0+ (1,0) [0|0] ""  IPMA_ADAS
 SG_ RR_CAN_TX_MUX_TRKER_CAL_DATA_5 m22 : 63|8@0+ (1,0) [0|0] ""  IPMA_ADAS
 SG_ RR_CAN_TX_MUX_SMC_CAL_MSG_CNT m21 : 15|8@0+ (1,0) [0|0] ""  IPMA_ADAS
 SG_ RR_CAN_TX_MUX_SMC_CAL_DATA_0 m21 : 23|8@0+ (1,0) [0|0] ""  IPMA_ADAS
 SG_ RR_CAN_TX_MUX_SMC_CAL_DATA_1 m21 : 31|8@0+ (1,0) [0|0] ""  IPMA_ADAS
 SG_ RR_CAN_TX_MUX_SMC_CAL_DATA_2 m21 : 39|8@0+ (1,0) [0|0] ""  IPMA_ADAS
 SG_ RR_CAN_TX_MUX_SMC_CAL_DATA_3 m21 : 47|8@0+ (1,0) [0|0] ""  IPMA_ADAS
 SG_ RR_CAN_TX_MUX_SMC_CAL_DATA_4 m21 : 55|8@0+ (1,0) [0|0] ""  IPMA_ADAS
 SG_ RR_CAN_TX_MUX_SMC_CAL_DATA_5 m21 : 63|8@0+ (1,0) [0|0] ""  IPMA_ADAS
 SG_ RR_CAN_TX_MUX_USC_CAL_MSG_CNT m20 : 15|8@0+ (1,0) [0|0] ""  IPMA_ADAS
 SG_ RR_CAN_TX_MUX_USC_CAL_DATA_0 m20 : 23|8@0+ (1,0) [0|0] ""  IPMA_ADAS
 SG_ RR_CAN_TX_MUX_USC_CAL_DATA_1 m20 : 31|8@0+ (1,0) [0|0] ""  IPMA_ADAS
 SG_ RR_CAN_TX_MUX_USC_CAL_DATA_2 m20 : 39|8@0+ (1,0) [0|0] ""  IPMA_ADAS
 SG_ RR_CAN_TX_MUX_USC_CAL_DATA_3 m20 : 47|8@0+ (1,0) [0|0] ""  IPMA_ADAS
 SG_ RR_CAN_TX_MUX_USC_CAL_DATA_4 m20 : 55|8@0+ (1,0) [0|0] ""  IPMA_ADAS
 SG_ RR_CAN_TX_MUX_USC_CAL_DATA_5 m20 : 63|8@0+ (1,0) [0|0] ""  IPMA_ADAS
 SG_ RR_CAN_TX_MUX_ALIGN_CAL_VER_MNR m18 : 15|16@0+ (1,0) [0|0] ""  IPMA_ADAS
 SG_ RR_CAN_TX_MUX_ALIGN_CAL_VER_MJR m18 : 31|16@0+ (1,0) [0|0] ""  IPMA_ADAS
 SG_ RR_CAN_TX_MUX_ALIGN_SW_VER_MINOR m19 : 15|16@0+ (1,0) [0|0] ""  IPMA_ADAS
 SG_ RR_CAN_TX_MUX_ALIGN_SW_VER_MAJOR m19 : 31|16@0+ (1,0) [0|0] ""  IPMA_ADAS
 SG_ RR_CAN_TX_MUX_USC_CAL_VER_MAJOR m2 : 15|32@0+ (1,0) [0|0] ""  IPMA_ADAS
 SG_ RR_CAN_TX_MUX_TRKR_CAL_VER_MINOR m4 : 15|16@0+ (1,0) [0|0] ""  IPMA_ADAS
 SG_ RR_CAN_TX_MUX_TRKR_CAL_VER_MAJOR m4 : 31|16@0+ (1,0) [0|0] ""  IPMA_ADAS
 SG_ RR_CAN_TX_MUX_TRKR_SW_VER_MINOR m11 : 15|16@0+ (1,0) [0|0] ""  IPMA_ADAS
 SG_ RR_CAN_TX_MUX_TRKR_SW_VER_MAJOR m11 : 31|16@0+ (1,0) [0|0] ""  IPMA_ADAS
 SG_ RR_CAN_TX_MUX_SMC_CAL_VER_MINOR m3 : 15|16@0+ (1,0) [0|0] ""  IPMA_ADAS
 SG_ RR_CAN_TX_MUX_SMC_CAL_VER_MAJOR m3 : 31|16@0+ (1,0) [0|0] ""  IPMA_ADAS
 SG_ RR_CAN_TX_MUX_RECW_CAL_VER_MINOR m8 : 15|16@0+ (1,0) [0|0] ""  IPMA_ADAS
 SG_ RR_CAN_TX_MUX_RECW_CAL_VER_MAJOR m8 : 31|16@0+ (1,0) [0|0] ""  IPMA_ADAS
 SG_ RR_CAN_TX_MUX_RECW_SW_VER_MINOR m12 : 15|16@0+ (1,0) [0|0] ""  IPMA_ADAS
 SG_ RR_CAN_TX_MUX_RECW_SW_VER_MAJOR m12 : 31|16@0+ (1,0) [0|0] ""  IPMA_ADAS
 SG_ RR_CAN_TX_MUX_RCWM_CAL_VER_MINOR m9 : 15|16@0+ (1,0) [0|0] ""  IPMA_ADAS
 SG_ RR_CAN_TX_MUX_RCWM_CAL_VER_MAJOR m9 : 31|16@0+ (1,0) [0|0] ""  IPMA_ADAS
 SG_ RR_CAN_TX_MUX_RCWM_SW_VER_MINOR m13 : 15|16@0+ (1,0) [0|0] ""  IPMA_ADAS
 SG_ RR_CAN_TX_MUX_RCWM_SW_VER_MAJOR m13 : 31|16@0+ (1,0) [0|0] ""  IPMA_ADAS
 SG_ RR_CAN_TX_MUX_RCTA_CAL_VER_MINOR m6 : 15|16@0+ (1,0) [0|0] ""  IPMA_ADAS
 SG_ RR_CAN_TX_MUX_RCTA_CAL_VER_MAJOR m6 : 31|16@0+ (1,0) [0|0] ""  IPMA_ADAS
 SG_ RR_CAN_TX_MUX_RCTA_SW_VER_MINOR m14 : 15|16@0+ (1,0) [0|0] ""  IPMA_ADAS
 SG_ RR_CAN_TX_MUX_RCTA_SW_VER_MAJOR m14 : 31|16@0+ (1,0) [0|0] ""  IPMA_ADAS
 SG_ RR_CAN_TX_MUX_LCDA_CAL_VER_MINOR m5 : 15|16@0+ (1,0) [0|0] ""  IPMA_ADAS
 SG_ RR_CAN_TX_MUX_LCDA_CAL_VER_MAJOR m5 : 31|16@0+ (1,0) [0|0] ""  IPMA_ADAS
 SG_ RR_CAN_TX_MUX_LCDA_SW_VER_MINOR m15 : 15|16@0+ (1,0) [0|0] ""  IPMA_ADAS
 SG_ RR_CAN_TX_MUX_LCDA_SW_VER_MAJOR m15 : 31|16@0+ (1,0) [0|0] ""  IPMA_ADAS
 SG_ RR_CAN_TX_MUX_FRESP_CAL_VER_MNR m10 : 15|16@0+ (1,0) [0|0] ""  IPMA_ADAS
 SG_ RR_CAN_TX_MUX_FRESP_CAL_VER_MJR m10 : 31|16@0+ (1,0) [0|0] ""  IPMA_ADAS
 SG_ RR_CAN_TX_MUX_FRESP_SW_VER_MINOR m16 : 15|16@0+ (1,0) [0|0] ""  IPMA_ADAS
 SG_ RR_CAN_TX_MUX_FRESP_SW_VER_MAJOR m16 : 31|16@0+ (1,0) [0|0] ""  IPMA_ADAS
 SG_ RR_CAN_TX_MUX_FCTA_CAL_VER_MINOR m7 : 15|16@0+ (1,0) [0|0] ""  IPMA_ADAS
 SG_ RR_CAN_TX_MUX_FCTA_CAL_VER_MAJOR m7 : 31|16@0+ (1,0) [0|0] ""  IPMA_ADAS
 SG_ RR_CAN_TX_MUX_FCTA_SW_VER_MINOR m17 : 15|16@0+ (1,0) [0|0] ""  IPMA_ADAS
 SG_ RR_CAN_TX_MUX_FCTA_SW_VER_MAJOR m17 : 31|16@0+ (1,0) [0|0] ""  IPMA_ADAS
 SG_ RR_CAN_TX_MUX_VCS_OFFSET_LONG m1 : 31|16@0+ (0.01,-655.35) [-655.35|0] "cm"  IPMA_ADAS
 SG_ RR_CAN_TX_MUX_VCS_OFFSET_LAT m1 : 15|16@0+ (0.01,-327.675) [-327.675|327.675] "cm"  IPMA_ADAS
 SG_ RR_CAN_TX_MUX_CORE_VERSION m0 : 63|8@0+ (1,0) [0|0] ""  IPMA_ADAS
 SG_ RR_CAN_TX_MUX_SENSOR_POLARITY m0 : 47|1@0+ (1,0) [0|1] ""  IPMA_ADAS
 SG_ RR_CAN_TX_MUX_SENSOR_LAT_OFFSET m0 : 46|15@0+ (0.01,-200) [-200|200] ""  IPMA_ADAS
 SG_ RR_CAN_TX_MUX_SENSOR_LONG_OFFSET m0 : 31|16@0+ (0.01,0) [0|655.35] "cm"  IPMA_ADAS
 SG_ RR_CAN_TX_MUX_SNSR_ANGLE_OFFSET m0 : 15|16@0+ (0.01,-200) [-200|200] "deg"  IPMA_ADAS
 SG_ RR_CAN_TX_MUX_KINK_ANGL_VER_MNR m30 : 15|16@0+ (1,0) [0|0] ""  IPMA_ADAS
 SG_ RR_CAN_TX_MUX_KINK_ANGL_VER_MJR m30 : 31|16@0+ (1,0) [0|0] ""  IPMA_ADAS
 SG_ RR_CAN_TX_MUX_ID M : 7|8@0+ (1,0) [0|255] ""  IPMA_ADAS

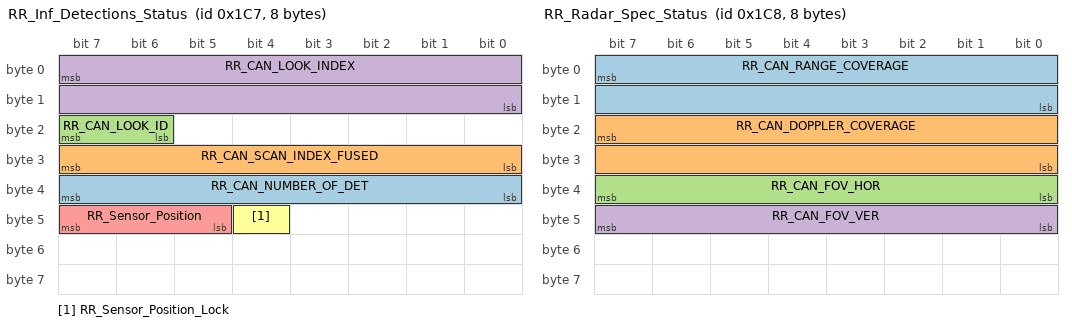
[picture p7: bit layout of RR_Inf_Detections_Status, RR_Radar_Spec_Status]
BO_ 455 RR_Inf_Detections_Status: 8 SODRR
 SG_ RR_CAN_NUMBER_OF_DET : 39|8@0+ (1,0) [0|255] ""  IPMA_ADAS
 SG_ RR_CAN_SCAN_INDEX_FUSED : 31|8@0+ (1,0) [0|255] ""  IPMA_ADAS
 SG_ RR_CAN_LOOK_ID : 23|2@0+ (1,0) [0|3] ""  IPMA_ADAS
 SG_ RR_CAN_LOOK_INDEX : 7|16@0+ (1,0) [0|65535] ""  IPMA_ADAS
 SG_ RR_Sensor_Position : 47|3@0+ (1,0) [0|0] ""  IPMA_ADAS
 SG_ RR_Sensor_Position_Lock : 44|1@0+ (1,0) [0|0] ""  IPMA_ADAS

BO_ 456 RR_Radar_Spec_Status: 8 SODRR
 SG_ RR_CAN_RANGE_COVERAGE : 7|16@0+ (0.00390625,0) [0|255.99609375] "m"  IPMA_ADAS
 SG_ RR_CAN_DOPPLER_COVERAGE : 23|16@0+ (0.00390625,-128) [-128|127.99609375] "m/s"  IPMA_ADAS
 SG_ RR_CAN_FOV_HOR : 39|8@0+ (1,0) [0|255] "deg"  IPMA_ADAS
 SG_ RR_CAN_FOV_VER : 47|8@0+ (1,0) [0|255] "deg"  IPMA_ADAS

BO_ 457 RR_Active_Flts_Status: 8 SODRR
 SG_ RR_CAN_ACTIVE_FAULTS : 7|64@0+ (1,0) [0|1.8446744074E+019] ""  IPMA_ADAS

BO_ 458 RR_Latch_Flts_Status: 8 SODRR
 SG_ RR_CAN_LATCH_FAULTS : 7|64@0+ (1,0) [0|1.84467E+019] ""  IPMA_ADAS

BO_ 461 RR_Status_Temp_Volt: 12 SODRR
 SG_ RR_CAN_Dolphin_AFC : 95|8@0+ (1,-50) [-50|205] "C"  External_Tool,IPMA_ADAS
 SG_ RR_CAN_Dolphin_Tx3 : 87|8@0+ (1,-50) [-50|205] "C"  External_Tool,IPMA_ADAS
 SG_ RR_CAN_Dolphin_Tx2 : 79|8@0+ (1,-50) [-50|205] "C"  External_Tool,IPMA_ADAS
 SG_ RR_CAN_1_8_V : 71|8@0+ (0.08,0) [0|20.4] ""  External_Tool,IPMA_ADAS
 SG_ RR_CAN_BATT_VOLTS : 63|8@0+ (0.08,0) [0|20.4] "V"  External_Tool,IPMA_ADAS
 SG_ RR_CAN_1_25_V : 55|8@0+ (0.08,0) [0|20.4] "V"  External_Tool,IPMA_ADAS
 SG_ RR_CAN_5_V : 47|8@0+ (0.08,0) [0|20.4] "V"  External_Tool,IPMA_ADAS
 SG_ RR_CAN_1_1_V : 31|8@0+ (0.08,0) [0|20.4] "V"  External_Tool,IPMA_ADAS
 SG_ RR_CAN_2_3_V : 15|8@0+ (0.08,0) [0|20.4] "V"  External_Tool,IPMA_ADAS
 SG_ RR_CAN_Dolphin_Tx1 : 39|8@0+ (1,-50) [-50|205] "C"  External_Tool,IPMA_ADAS
 SG_ RR_CAN_OnBoard_Thermistor : 23|8@0+ (1,-50) [-50|205] "C"  External_Tool,IPMA_ADAS
 SG_ RR_CAN_RRU_Temp1 : 7|8@0+ (1,-50) [-50|205] "C"  External_Tool,IPMA_ADAS

CM_ "CAN bus that communicates the Short Range Radars with ADAS";
CM_ BO_ 3221225472 "This is a message for not used signals, created by Vector CANdb++ DBC OLE DB Provider.";
CM_ SG_ 5 SRR_CCLK_COU_SYNCN_CAN_SEC "For Delphi message definition, this signal is NOT USED. This signal is used when in BMW message format is being used.";
BA_DEF_ BU_  "NodeLayerModules" STRING ;
BA_DEF_ BO_  "VFrameFormat" ENUM  "StandardCAN","ExtendedCAN","reserved","reserved","reserved","reserved","reserved","reserved","reserved","reserved","reserved","reserved","reserved","reserved","StandardCAN_FD","ExtendedCAN_FD";
BA_DEF_ BO_  "DiagConnection" INT 0 65535;
BA_DEF_ BO_  "CanTpBs" INT 0 255;
BA_DEF_ BO_  "EventRateOfChange" INT 10 10000;
BA_DEF_ BO_  "DiagState" ENUM  "No","Yes";
BA_DEF_ BO_  "DiagRequest" ENUM  "No","Yes";
BA_DEF_ BO_  "DiagResponse" ENUM  "No","Yes";
BA_DEF_ BU_  "NmAsrNodeIdentifier" HEX 128 255;
BA_DEF_ BU_  "TpOwnSystemEcuNumber" HEX 0 255;
BA_DEF_  "NetworkSpeed" ENUM  "500kBits/s","125kBit/s","2MBits/s";
BA_DEF_  "NmAsrMessageCount" INT 64 128;
BA_DEF_  "NmAsrBaseAddress" HEX 1408 1408;
BA_DEF_  "VersionDay" INT 1 31;
BA_DEF_  "Manufacturer" STRING ;
BA_DEF_  "VersionMonth" INT 1 12;
BA_DEF_  "VersionYear" INT 2000 3000;
BA_DEF_ SG_  "GenSigTimeoutTime_SRR01RR" INT 0 0;
BA_DEF_ SG_  "GenSigCycleTime" INT 0 0;
BA_DEF_ SG_  "GenSigVtName" STRING ;
BA_DEF_ SG_  "GenSigVtEn" STRING ;
BA_DEF_  "GenNetworkMuxEn" STRING ;
BA_DEF_  "GenNetworkBaudrate" STRING ;
BA_DEF_  "GenNetworkName" STRING ;
BA_DEF_ SG_  "GenSigCmt" STRING ;
BA_DEF_  "GenRevisionDate" STRING ;
BA_DEF_  "GenRevision" STRING ;
BA_DEF_  "GenDescription" STRING ;
BA_DEF_  "GenCompany" STRING ;
BA_DEF_  "GenAuthor" STRING ;
BA_DEF_ BU_  "NmStationAddress" HEX 0 0;
BA_DEF_ SG_  "GenSigSendType" ENUM  "Cyclic","OnWrite","OnChange","IfActive","NoSigSendType";
BA_DEF_ SG_  "GenSigInactiveValue" INT 0 100000;
BA_DEF_ SG_  "GenSigMissingSourceValue" INT 0 1000000000;
BA_DEF_ SG_  "GenSigStartValue" INT 0 1000000000;
BA_DEF_ BO_  "GenMsgILSupport" ENUM  "No","Yes";
BA_DEF_ BO_  "GenMsgSendType" ENUM  "FixedPeriodic","Event","EnabledPeriodic","EventPeriodic","NoMsgSendType";
BA_DEF_ BO_  "GenMsgCycleTime" INT 0 100000;
BA_DEF_ BO_  "GenMsgNrOfRepetition" INT 0 100;
BA_DEF_ BO_  "NetworkInitialization" ENUM  "No","Yes";
BA_DEF_ BU_  "PowerType" ENUM  "Switched","Latched","Sleep";
BA_DEF_ BU_  "NodeStartUpTime" INT 0 10000;
BA_DEF_ BU_  "NodeWakeUpTime" INT 0 10000;
BA_DEF_  "DBName" STRING ;
BA_DEF_  "BusType" STRING ;
BA_DEF_DEF_  "NodeLayerModules" "CANoeILNLFord.dll";
BA_DEF_DEF_  "VFrameFormat" "StandardCAN_FD";
BA_DEF_DEF_  "DiagConnection" 0;
BA_DEF_DEF_  "CanTpBs" 255;
BA_DEF_DEF_  "EventRateOfChange" 10000;
BA_DEF_DEF_  "DiagState" "No";
BA_DEF_DEF_  "DiagRequest" "No";
BA_DEF_DEF_  "DiagResponse" "No";
BA_DEF_DEF_  "NmAsrNodeIdentifier" 128;
BA_DEF_DEF_  "TpOwnSystemEcuNumber" 0;
BA_DEF_DEF_  "NetworkSpeed" "2MBits/s";
BA_DEF_DEF_  "NmAsrMessageCount" 64;
BA_DEF_DEF_  "NmAsrBaseAddress" 1408;
BA_DEF_DEF_  "VersionDay" 23;
BA_DEF_DEF_  "Manufacturer" "Ford";
BA_DEF_DEF_  "VersionMonth" 5;
BA_DEF_DEF_  "VersionYear" 2018;
BA_DEF_DEF_  "GenSigTimeoutTime_SRR01RR" 0;
BA_DEF_DEF_  "GenSigCycleTime" 0;
BA_DEF_DEF_  "GenSigVtName" "";
BA_DEF_DEF_  "GenSigVtEn" "";
BA_DEF_DEF_  "GenNetworkMuxEn" "FALSE";
BA_DEF_DEF_  "GenNetworkBaudrate" "500 kbps";
BA_DEF_DEF_  "GenNetworkName" "SRR5 PCAN";
BA_DEF_DEF_  "GenSigCmt" "";
BA_DEF_DEF_  "GenRevisionDate" "June 7, 2018";
BA_DEF_DEF_  "GenRevision" "v3.04";
BA_DEF_DEF_  "GenDescription" "CAN bus that communicates the Short Range Radars with ADAS";
BA_DEF_DEF_  "GenCompany" "APTIV";
BA_DEF_DEF_  "GenAuthor" "Salah Mohamed";
BA_DEF_DEF_  "NmStationAddress" 0;
BA_DEF_DEF_  "GenSigSendType" "OnWrite";
BA_DEF_DEF_  "GenSigInactiveValue" 0;
BA_DEF_DEF_  "GenSigMissingSourceValue" 0;
BA_DEF_DEF_  "GenSigStartValue" 0;
BA_DEF_DEF_  "GenMsgILSupport" "Yes";
BA_DEF_DEF_  "GenMsgSendType" "NoMsgSendType";
BA_DEF_DEF_  "GenMsgCycleTime" 0;
BA_DEF_DEF_  "GenMsgNrOfRepetition" 0;
BA_DEF_DEF_  "NetworkInitialization" "Yes";
BA_DEF_DEF_  "PowerType" "Switched";
BA_DEF_DEF_  "NodeStartUpTime" 250;
BA_DEF_DEF_  "NodeWakeUpTime" 10;
BA_DEF_DEF_  "DBName" "";
BA_DEF_DEF_  "BusType" "CAN";
BA_ "GenCompany" "Aptiv";
BA_ "VersionMonth" 6;
BA_ "BusType" "CAN FD";
BA_ "GenNetworkBaudrate" "500000";
BA_ "GenRevisionDate" "July 2, 2018";
BA_ "GenRevision" "V03.05";
BA_ "GenAuthor" "Osama Ghanem";
BA_ "VersionDay" 7;
BA_ "DBName" "PCAN_SRR5_R";
BA_ "GenMsgSendType" BO_ 16 1;
BA_ "GenMsgSendType" BO_ 17 1;
BA_ "GenMsgSendType" BO_ 18 1;
BA_ "GenMsgSendType" BO_ 19 1;
BA_ "GenMsgSendType" BO_ 396 1;
BA_ "GenMsgSendType" BO_ 460 1;
BA_ "GenMsgCycleTime" BO_ 1796 50;
BA_ "GenMsgSendType" BO_ 1796 0;
BA_ "GenMsgSendType" BO_ 395 1;
BA_ "GenMsgSendType" BO_ 459 1;
BA_ "GenMsgSendType" BO_ 6 1;
BA_ "GenMsgSendType" BO_ 5 1;
BA_ "GenMsgCycleTime" BO_ 513 25;
BA_ "GenMsgSendType" BO_ 513 0;
BA_ "GenMsgSendType" BO_ 4 1;
BA_ "GenMsgCycleTime" BO_ 4 50;
BA_ "GenMsgCycleTime" BO_ 514 25;
BA_ "GenMsgSendType" BO_ 514 0;
BA_ "GenMsgSendType" BO_ 384 1;
BA_ "GenMsgSendType" BO_ 385 1;
BA_ "GenMsgSendType" BO_ 386 1;
BA_ "GenMsgSendType" BO_ 387 1;
BA_ "GenMsgSendType" BO_ 388 1;
BA_ "GenMsgSendType" BO_ 389 1;
BA_ "GenMsgSendType" BO_ 390 1;
BA_ "GenMsgSendType" BO_ 391 1;
BA_ "GenMsgSendType" BO_ 392 1;
BA_ "GenMsgSendType" BO_ 393 1;
BA_ "GenMsgSendType" BO_ 394 1;
BA_ "GenMsgSendType" BO_ 397 1;
BA_ "GenMsgSendType" BO_ 448 1;
BA_ "GenMsgSendType" BO_ 449 1;
BA_ "GenMsgSendType" BO_ 450 1;
BA_ "GenMsgSendType" BO_ 451 1;
BA_ "GenMsgSendType" BO_ 452 1;
BA_ "GenMsgSendType" BO_ 453 1;
BA_ "GenMsgSendType" BO_ 454 1;
BA_ "GenMsgSendType" BO_ 455 1;
BA_ "GenMsgSendType" BO_ 456 1;
BA_ "GenMsgSendType" BO_ 457 1;
BA_ "GenMsgSendType" BO_ 458 1;
BA_ "GenMsgSendType" BO_ 461 1;
BA_ "GenSigCmt" SG_ 16 FL_CAN_INST_MODE "Instrumentation mode";
BA_ "GenSigVtName" SG_ 16 FL_CAN_INST_MODE "VtSig_CAN_INST_MODE";
BA_ "GenSigVtEn" SG_ 16 FL_CAN_INST_MODE "TRUE";
BA_ "GenSigCmt" SG_ 17 FR_CAN_INST_MODE "Instrumentation mode";
BA_ "GenSigVtName" SG_ 17 FR_CAN_INST_MODE "VtSig_CAN_INST_MODE";
BA_ "GenSigVtEn" SG_ 17 FR_CAN_INST_MODE "TRUE";
BA_ "GenSigCmt" SG_ 18 RL_CAN_INST_MODE "Instrumentation mode";
BA_ "GenSigVtName" SG_ 18 RL_CAN_INST_MODE "VtSig_CAN_INST_MODE";
BA_ "GenSigVtEn" SG_ 18 RL_CAN_INST_MODE "TRUE";
BA_ "GenSigCmt" SG_ 19 RR_CAN_INST_MODE "Instrumentation mode";
BA_ "GenSigVtName" SG_ 19 RR_CAN_INST_MODE "VtSig_CAN_INST_MODE";
BA_ "GenSigVtEn" SG_ 19 RR_CAN_INST_MODE "TRUE";
BA_ "GenSigCmt" SG_ 396 RL_CAN_VRTCL_ALIGN_UPDATES_Nbr "Number of alignment updates done.";
BA_ "GenSigCmt" SG_ 396 RL_CAN_HRZNTL_ALIGN_UPDATES_Nbr "Number of alignment updates done.";
BA_ "GenSigCmt" SG_ 460 RR_CAN_VRTCL_ALIGN_UPDATES_Nbr "Number of alignment updates done.";
BA_ "GenSigCmt" SG_ 460 RR_CAN_HRZNTL_ALIGN_UPDATES_Nbr "Number of alignment updates done.";
BA_ "GenSigStartValue" SG_ 395 RL_Align_Vertical_Ref 511.500000000001;
BA_ "GenSigStartValue" SG_ 395 RL_Align_Vertical_Angle 511.500000000001;
BA_ "GenSigStartValue" SG_ 395 RL_Align_Horizontal_Angle 511.5;
BA_ "GenSigStartValue" SG_ 395 RL_Align_Horizontal_Ref 511.5;
BA_ "GenSigStartValue" SG_ 459 RR_Align_Vertical_Ref 511.500000000001;
BA_ "GenSigStartValue" SG_ 459 RR_Align_Vertical_Angle 511.500000000001;
BA_ "GenSigStartValue" SG_ 459 RR_Align_Horizontal_Angle 511.5;
BA_ "GenSigStartValue" SG_ 459 RR_Align_Horizontal_Ref 511.5;
BA_ "GenSigCmt" SG_ 513 SRR_CAN_YAW_RATE_CALC_QF "Quality factor of the CAN_YAW_RATE_CALC signal";
BA_ "GenSigVtName" SG_ 513 SRR_CAN_YAW_RATE_CALC_QF "VtSig_CAN_YAW_RATE_CALC_QF";
BA_ "GenSigVtEn" SG_ 513 SRR_CAN_YAW_RATE_CALC_QF "TRUE";
BA_ "GenSigStartValue" SG_ 513 SRR_CAN_YAW_RATE_BIAS 512;
BA_ "GenSigCmt" SG_ 513 SRR_CAN_YAW_RATE_BIAS "Yaw rate bias";
BA_ "GenSigStartValue" SG_ 513 SRR_CAN_YAW_RATE_CALC 4096;
BA_ "GenSigCmt" SG_ 513 SRR_CAN_YAW_RATE_CALC "Contains the bias-compensated yaw rate";
BA_ "GenSigCmt" SG_ 513 SRR_CAN_VEH_SPD_COMP_FACTOR "Compensated vehicle speed factor";
BA_ "GenSigStartValue" SG_ 513 SRR_CAN_VEH_SPD_COMP_FACTOR 2048;
BA_ "GenSigCmt" SG_ 513 SRR_CAN_VEHICLE_SPEED_CALC_QF "Quality factor of the CAN_VEHICLE_SPEED_CALC";
BA_ "GenSigVtName" SG_ 513 SRR_CAN_VEHICLE_SPEED_CALC_QF "VtSig_CAN_VEHICLE_SPEED_CALC_QF";
BA_ "GenSigVtEn" SG_ 513 SRR_CAN_VEHICLE_SPEED_CALC_QF "TRUE";
BA_ "GenSigCmt" SG_ 513 SRR_CAN_VEHICLE_SPEED_CALC "Contains the compensated vehicle speed used within the FCR";
BA_ "GenSigCmt" SG_ 514 SRR_CAN_GEAR_POSITION "Gear Position";
BA_ "GenSigVtEn" SG_ 514 SRR_CAN_GEAR_POSITION "TRUE";
BA_ "GenSigVtName" SG_ 514 SRR_CAN_GEAR_POSITION "VtSig_CAN_GEAR_POSITION";
BA_ "GenSigCycleTime" SG_ 384 RL_CAN_TX_VEH_SPEED_DIRECTION 50;
BA_ "GenSigTimeoutTime_SRR01RR" SG_ 384 RL_CAN_TX_VEH_SPEED_DIRECTION 150;
BA_ "GenSigCycleTime" SG_ 384 RL_CAN_TX_RADIUS_CURVATURE 50;
BA_ "GenSigTimeoutTime_SRR01RR" SG_ 384 RL_CAN_TX_RADIUS_CURVATURE 150;
BA_ "GenSigCycleTime" SG_ 384 RL_CAN_TX_STEERING_ANGLE_SIGN 50;
BA_ "GenSigTimeoutTime_SRR01RR" SG_ 384 RL_CAN_TX_STEERING_ANGLE_SIGN 150;
BA_ "GenSigCycleTime" SG_ 384 RL_CAN_TX_STEERING_ANGLE 50;
BA_ "GenSigTimeoutTime_SRR01RR" SG_ 384 RL_CAN_TX_STEERING_ANGLE 150;
BA_ "GenSigCycleTime" SG_ 384 RL_CAN_TX_YAW_RATE_CALC 50;
BA_ "GenSigTimeoutTime_SRR01RR" SG_ 384 RL_CAN_TX_YAW_RATE_CALC 150;
BA_ "GenSigCycleTime" SG_ 384 RL_CAN_TX_VEHICLE_SPEED_CALC 50;
BA_ "GenSigTimeoutTime_SRR01RR" SG_ 384 RL_CAN_TX_VEHICLE_SPEED_CALC 150;
BA_ "GenSigCycleTime" SG_ 384 RL_CAN_TX_SCAN_INDEX 50;
BA_ "GenSigTimeoutTime_SRR01RR" SG_ 384 RL_CAN_TX_SCAN_INDEX 150;
BA_ "GenSigCycleTime" SG_ 385 RL_CAN_TX_SW_VERSION_DSP 50;
BA_ "GenSigTimeoutTime_SRR01RR" SG_ 385 RL_CAN_TX_SW_VERSION_DSP 150;
BA_ "GenSigCycleTime" SG_ 385 RL_CAN_TX_PCAN_PROTOCOL_MINOR 50;
BA_ "GenSigTimeoutTime_SRR01RR" SG_ 385 RL_CAN_TX_PCAN_PROTOCOL_MINOR 150;
BA_ "GenSigCycleTime" SG_ 385 RL_CAN_TX_PCAN_PROTOCOL_MAJOR 50;
BA_ "GenSigTimeoutTime_SRR01RR" SG_ 385 RL_CAN_TX_PCAN_PROTOCOL_MAJOR 150;
BA_ "GenSigCycleTime" SG_ 385 RL_CAN_TX_SW_VERSION_ARM 50;
BA_ "GenSigTimeoutTime_SRR01RR" SG_ 385 RL_CAN_TX_SW_VERSION_ARM 150;
BA_ "GenSigCycleTime" SG_ 385 RL_CAN_TX_HW_VERSION 50;
BA_ "GenSigTimeoutTime_SRR01RR" SG_ 385 RL_CAN_TX_HW_VERSION 150;
BA_ "GenSigCycleTime" SG_ 386 RL_CAN_TX_SERIAL_NUMBER_SEQUENCE 50;
BA_ "GenSigTimeoutTime_SRR01RR" SG_ 386 RL_CAN_TX_SERIAL_NUMBER_SEQUENCE 150;
BA_ "GenSigCycleTime" SG_ 386 RL_CAN_TX_SERIAL_NUM_JULIAN_YEAR 50;
BA_ "GenSigTimeoutTime_SRR01RR" SG_ 386 RL_CAN_TX_SERIAL_NUM_JULIAN_YEAR 150;
BA_ "GenSigCycleTime" SG_ 386 RL_CAN_TX_SERIAL_NUM_JULIAN_DAY 50;
BA_ "GenSigTimeoutTime_SRR01RR" SG_ 386 RL_CAN_TX_SERIAL_NUM_JULIAN_DAY 150;
BA_ "GenSigCycleTime" SG_ 386 RL_CAN_TX_ARM_THROUGHPUT 50;
BA_ "GenSigTimeoutTime_SRR01RR" SG_ 386 RL_CAN_TX_ARM_THROUGHPUT 150;
BA_ "GenSigCycleTime" SG_ 386 RL_CAN_TX_SYSTEM_STATUS 50;
BA_ "GenSigTimeoutTime_SRR01RR" SG_ 386 RL_CAN_TX_SYSTEM_STATUS 150;
BA_ "GenSigCycleTime" SG_ 386 RL_CAN_TX_LOOK_TYPE_1 50;
BA_ "GenSigTimeoutTime_SRR01RR" SG_ 386 RL_CAN_TX_LOOK_TYPE_1 150;
BA_ "GenSigCycleTime" SG_ 386 RL_CAN_TX_OVERHEAT_ERROR 50;
BA_ "GenSigTimeoutTime_SRR01RR" SG_ 386 RL_CAN_TX_OVERHEAT_ERROR 150;
BA_ "GenSigCycleTime" SG_ 386 RL_CAN_TX_RANGE_PERF_ERROR 50;
BA_ "GenSigTimeoutTime_SRR01RR" SG_ 386 RL_CAN_TX_RANGE_PERF_ERROR 150;
BA_ "GenSigCycleTime" SG_ 386 RL_CAN_TX_COMM_ERROR 50;
BA_ "GenSigTimeoutTime_SRR01RR" SG_ 386 RL_CAN_TX_COMM_ERROR 150;
BA_ "GenSigCycleTime" SG_ 386 RL_CAN_TX_INTERNAL_ERROR 50;
BA_ "GenSigTimeoutTime_SRR01RR" SG_ 386 RL_CAN_TX_INTERNAL_ERROR 150;
BA_ "GenSigCycleTime" SG_ 386 RL_CAN_TX_XCVR_OPERATIONAL 50;
BA_ "GenSigTimeoutTime_SRR01RR" SG_ 386 RL_CAN_TX_XCVR_OPERATIONAL 150;
BA_ "GenSigCycleTime" SG_ 387 RL_CAN_TX_DRIVING_ENVIRONMENT 50;
BA_ "GenSigTimeoutTime_SRR01RR" SG_ 387 RL_CAN_TX_DRIVING_ENVIRONMENT 150;
BA_ "GenSigCycleTime" SG_ 387 RL_CAN_TX_ROLLING_COUNT_1 50;
BA_ "GenSigTimeoutTime_SRR01RR" SG_ 387 RL_CAN_TX_ROLLING_COUNT_1 150;
BA_ "GenSigCycleTime" SG_ 387 RL_CAN_TX_Temperature 50;
BA_ "GenSigTimeoutTime_SRR01RR" SG_ 387 RL_CAN_TX_Temperature 150;
BA_ "GenSigCycleTime" SG_ 387 RL_CAN_TX_YAW_RATE_BIAS 50;
BA_ "GenSigTimeoutTime_SRR01RR" SG_ 387 RL_CAN_TX_YAW_RATE_BIAS 150;
BA_ "GenSigCycleTime" SG_ 387 RL_CAN_TX_VEH_SPD_COMP_FACTOR 50;
BA_ "GenSigTimeoutTime_SRR01RR" SG_ 387 RL_CAN_TX_VEH_SPD_COMP_FACTOR 150;
BA_ "GenSigCycleTime" SG_ 387 RL_CAN_TX_AUTO_ALIGN_QUA_FACTOR 50;
BA_ "GenSigTimeoutTime_SRR01RR" SG_ 387 RL_CAN_TX_AUTO_ALIGN_QUA_FACTOR 150;
BA_ "GenSigCycleTime" SG_ 387 RL_CAN_TX_Alignment_MODE 50;
BA_ "GenSigTimeoutTime_SRR01RR" SG_ 387 RL_CAN_TX_Alignment_MODE 150;
BA_ "GenSigCycleTime" SG_ 387 RL_CAN_TX_CURRENT_MISALIGN_ANGLE 50;
BA_ "GenSigTimeoutTime_SRR01RR" SG_ 387 RL_CAN_TX_CURRENT_MISALIGN_ANGLE 150;
BA_ "GenSigCycleTime" SG_ 387 RL_CAN_TX_SAVED_MISALIGN_ANGLE 50;
BA_ "GenSigTimeoutTime_SRR01RR" SG_ 387 RL_CAN_TX_SAVED_MISALIGN_ANGLE 150;
BA_ "GenSigCycleTime" SG_ 388 RL_Supply_2_3v_Out_Of_Range_Flt 50;
BA_ "GenSigTimeoutTime_SRR01RR" SG_ 388 RL_Supply_2_3v_Out_Of_Range_Flt 150;
BA_ "GenSigCycleTime" SG_ 388 RL_Supply_1_25v_Out_Of_Range_Flt 50;
BA_ "GenSigTimeoutTime_SRR01RR" SG_ 388 RL_Supply_1_25v_Out_Of_Range_Flt 150;
BA_ "GenSigCycleTime" SG_ 388 RL_Software_Incompatible_Flt 50;
BA_ "GenSigTimeoutTime_SRR01RR" SG_ 388 RL_Software_Incompatible_Flt 150;
BA_ "GenSigCycleTime" SG_ 388 RL_Host_Spi_Checksum_Flt 50;
BA_ "GenSigTimeoutTime_SRR01RR" SG_ 388 RL_Host_Spi_Checksum_Flt 150;
BA_ "GenSigCycleTime" SG_ 388 RL_Loss_Of_Comm_With_Dsp_Flt 50;
BA_ "GenSigTimeoutTime_SRR01RR" SG_ 388 RL_Loss_Of_Comm_With_Dsp_Flt 150;
BA_ "GenSigCycleTime" SG_ 388 RL_No_Communication_With_Arm_Flt 50;
BA_ "GenSigTimeoutTime_SRR01RR" SG_ 388 RL_No_Communication_With_Arm_Flt 150;
BA_ "GenSigCycleTime" SG_ 388 RL_Communication_With_Host_Flt 50;
BA_ "GenSigTimeoutTime_SRR01RR" SG_ 388 RL_Communication_With_Host_Flt 150;
BA_ "GenSigCycleTime" SG_ 388 RL_Communication_With_Arm_Flt 50;
BA_ "GenSigTimeoutTime_SRR01RR" SG_ 388 RL_Communication_With_Arm_Flt 150;
BA_ "GenSigCycleTime" SG_ 388 RL_Dsp_Loop_Overrun_Flt_Dsp 50;
BA_ "GenSigTimeoutTime_SRR01RR" SG_ 388 RL_Dsp_Loop_Overrun_Flt_Dsp 150;
BA_ "GenSigCycleTime" SG_ 388 RL_Tuning_Sensitivity_Flt 50;
BA_ "GenSigTimeoutTime_SRR01RR" SG_ 388 RL_Tuning_Sensitivity_Flt 150;
BA_ "GenSigCycleTime" SG_ 388 RL_Saturated_Tuning_Freq_Flt 50;
BA_ "GenSigTimeoutTime_SRR01RR" SG_ 388 RL_Saturated_Tuning_Freq_Flt 150;
BA_ "GenSigCycleTime" SG_ 388 RL_Local_Oscillator_Power_Flt 50;
BA_ "GenSigTimeoutTime_SRR01RR" SG_ 388 RL_Local_Oscillator_Power_Flt 150;
BA_ "GenSigCycleTime" SG_ 388 RL_Transmitter_Power_Flt 50;
BA_ "GenSigTimeoutTime_SRR01RR" SG_ 388 RL_Transmitter_Power_Flt 150;
BA_ "GenSigCycleTime" SG_ 388 RL_Radar_Data_Sync_Flt 50;
BA_ "GenSigTimeoutTime_SRR01RR" SG_ 388 RL_Radar_Data_Sync_Flt 150;
BA_ "GenSigCycleTime" SG_ 388 RL_Dsp_Spi_Hardware_Flt 50;
BA_ "GenSigTimeoutTime_SRR01RR" SG_ 388 RL_Dsp_Spi_Hardware_Flt 150;
BA_ "GenSigCycleTime" SG_ 388 RL_Transmitter_Device_Spi_Flt 50;
BA_ "GenSigTimeoutTime_SRR01RR" SG_ 388 RL_Transmitter_Device_Spi_Flt 150;
BA_ "GenSigCycleTime" SG_ 388 RL_Receiver_Device_Spi_Flt 50;
BA_ "GenSigTimeoutTime_SRR01RR" SG_ 388 RL_Receiver_Device_Spi_Flt 150;
BA_ "GenSigCycleTime" SG_ 388 RL_Freq_Synthe_Device_Spi_Flt 50;
BA_ "GenSigTimeoutTime_SRR01RR" SG_ 388 RL_Freq_Synthe_Device_Spi_Flt 150;
BA_ "GenSigCycleTime" SG_ 388 RL_Analog_Cnvrtr_Device_Spi_Flt 50;
BA_ "GenSigTimeoutTime_SRR01RR" SG_ 388 RL_Analog_Cnvrtr_Device_Spi_Flt 150;
BA_ "GenSigCycleTime" SG_ 388 RL_Transmitter_Id_Flt 50;
BA_ "GenSigTimeoutTime_SRR01RR" SG_ 388 RL_Transmitter_Id_Flt 150;
BA_ "GenSigCycleTime" SG_ 388 RL_Ecu_Temperature_High_Flt 50;
BA_ "GenSigTimeoutTime_SRR01RR" SG_ 388 RL_Ecu_Temperature_High_Flt 150;
BA_ "GenSigCycleTime" SG_ 388 RL_Transmitter_Temp_High_Flt 50;
BA_ "GenSigTimeoutTime_SRR01RR" SG_ 388 RL_Transmitter_Temp_High_Flt 150;
BA_ "GenSigCycleTime" SG_ 388 RL_Alignment_Routine_Failed_Flt 50;
BA_ "GenSigTimeoutTime_SRR01RR" SG_ 388 RL_Alignment_Routine_Failed_Flt 150;
BA_ "GenSigCycleTime" SG_ 388 RL_Unreasonable_Radar_Data 50;
BA_ "GenSigTimeoutTime_SRR01RR" SG_ 388 RL_Unreasonable_Radar_Data 150;
BA_ "GenSigCycleTime" SG_ 388 RL_Sensor_Blocked_Flt 50;
BA_ "GenSigTimeoutTime_SRR01RR" SG_ 388 RL_Sensor_Blocked_Flt 150;
BA_ "GenSigCycleTime" SG_ 388 RL_Vertical_Alignt_Out_Of_Range 50;
BA_ "GenSigTimeoutTime_SRR01RR" SG_ 388 RL_Vertical_Alignt_Out_Of_Range 150;
BA_ "GenSigCycleTime" SG_ 388 RL_Horizontal_Align_Out_Of_Range 50;
BA_ "GenSigTimeoutTime_SRR01RR" SG_ 388 RL_Horizontal_Align_Out_Of_Range 150;
BA_ "GenSigCycleTime" SG_ 388 RL_Factory_Alignment_Mode 50;
BA_ "GenSigTimeoutTime_SRR01RR" SG_ 388 RL_Factory_Alignment_Mode 150;
BA_ "GenSigCycleTime" SG_ 388 RL_Battery_Low_Flt 50;
BA_ "GenSigTimeoutTime_SRR01RR" SG_ 388 RL_Battery_Low_Flt 150;
BA_ "GenSigCycleTime" SG_ 388 RL_Battery_High_Flt 50;
BA_ "GenSigTimeoutTime_SRR01RR" SG_ 388 RL_Battery_High_Flt 150;
BA_ "GenSigCycleTime" SG_ 388 RL_Ecu_Position_Config_Flt 50;
BA_ "GenSigTimeoutTime_SRR01RR" SG_ 388 RL_Ecu_Position_Config_Flt 150;
BA_ "GenSigCycleTime" SG_ 388 RL_Supply_1_1v_Out_Of_Range_Flt 50;
BA_ "GenSigTimeoutTime_SRR01RR" SG_ 388 RL_Supply_1_1v_Out_Of_Range_Flt 150;
BA_ "GenSigCycleTime" SG_ 388 RL_Supply_1_8v_Out_Of_Range_Flt 50;
BA_ "GenSigTimeoutTime_SRR01RR" SG_ 388 RL_Supply_1_8v_Out_Of_Range_Flt 150;
BA_ "GenSigCycleTime" SG_ 388 RL_Thermistor_Out_Of_Range_Flt 50;
BA_ "GenSigTimeoutTime_SRR01RR" SG_ 388 RL_Thermistor_Out_Of_Range_Flt 150;
BA_ "GenSigCycleTime" SG_ 388 RL_Supply_5v_Out_Of_Range_Flt 50;
BA_ "GenSigTimeoutTime_SRR01RR" SG_ 388 RL_Supply_5v_Out_Of_Range_Flt 150;
BA_ "GenSigCycleTime" SG_ 388 RL_Pcan_Init_Missing_Message_Flt 50;
BA_ "GenSigTimeoutTime_SRR01RR" SG_ 388 RL_Pcan_Init_Missing_Message_Flt 150;
BA_ "GenSigCycleTime" SG_ 388 RL_Pcan_Trk_Data_Unreasnble_Flt 50;
BA_ "GenSigTimeoutTime_SRR01RR" SG_ 388 RL_Pcan_Trk_Data_Unreasnble_Flt 150;
BA_ "GenSigCycleTime" SG_ 388 RL_Pcan_Data_Range_Check_Flt 50;
BA_ "GenSigTimeoutTime_SRR01RR" SG_ 388 RL_Pcan_Data_Range_Check_Flt 150;
BA_ "GenSigCycleTime" SG_ 388 RL_Pcan_Missing_Message_Flt 50;
BA_ "GenSigTimeoutTime_SRR01RR" SG_ 388 RL_Pcan_Missing_Message_Flt 150;
BA_ "GenSigCycleTime" SG_ 388 RL_Pcan_Hw_Rx_Buffer_Flt 50;
BA_ "GenSigTimeoutTime_SRR01RR" SG_ 388 RL_Pcan_Hw_Rx_Buffer_Flt 150;
BA_ "GenSigCycleTime" SG_ 388 RL_Pcan_Sw_Buffer_Flt 50;
BA_ "GenSigTimeoutTime_SRR01RR" SG_ 388 RL_Pcan_Sw_Buffer_Flt 150;
BA_ "GenSigCycleTime" SG_ 388 RL_Pcan_Bus_Off 50;
BA_ "GenSigTimeoutTime_SRR01RR" SG_ 388 RL_Pcan_Bus_Off 150;
BA_ "GenSigCycleTime" SG_ 388 RL_Host_Instrctn_Set_Check_Flt 50;
BA_ "GenSigTimeoutTime_SRR01RR" SG_ 388 RL_Host_Instrctn_Set_Check_Flt 150;
BA_ "GenSigCycleTime" SG_ 388 RL_Host_Stack_Overflow_Flt 50;
BA_ "GenSigTimeoutTime_SRR01RR" SG_ 388 RL_Host_Stack_Overflow_Flt 150;
BA_ "GenSigCycleTime" SG_ 388 RL_Sensor_Watchdog_Flt 50;
BA_ "GenSigTimeoutTime_SRR01RR" SG_ 388 RL_Sensor_Watchdog_Flt 150;
BA_ "GenSigCycleTime" SG_ 388 RL_Sensor_Pll_Lock_Flt 50;
BA_ "GenSigTimeoutTime_SRR01RR" SG_ 388 RL_Sensor_Pll_Lock_Flt 150;
BA_ "GenSigCycleTime" SG_ 388 RL_Host_Pll_Lock_Flt 50;
BA_ "GenSigTimeoutTime_SRR01RR" SG_ 388 RL_Host_Pll_Lock_Flt 150;
BA_ "GenSigCycleTime" SG_ 388 RL_Sensor_Ram_Memory_Test_Flt 50;
BA_ "GenSigTimeoutTime_SRR01RR" SG_ 388 RL_Sensor_Ram_Memory_Test_Flt 150;
BA_ "GenSigCycleTime" SG_ 388 RL_Host_Ram_Memory_Test_Flt 50;
BA_ "GenSigTimeoutTime_SRR01RR" SG_ 388 RL_Host_Ram_Memory_Test_Flt 150;
BA_ "GenSigCycleTime" SG_ 388 RL_Snsr_Custmr_Cal_Flsh_Chksum 50;
BA_ "GenSigTimeoutTime_SRR01RR" SG_ 388 RL_Snsr_Custmr_Cal_Flsh_Chksum 150;
BA_ "GenSigCycleTime" SG_ 388 RL_Dsp_Usc_Validation_Flt 50;
BA_ "GenSigTimeoutTime_SRR01RR" SG_ 388 RL_Dsp_Usc_Validation_Flt 150;
BA_ "GenSigCycleTime" SG_ 388 RL_Sensor_App_Flash_Checksum_Flt 50;
BA_ "GenSigTimeoutTime_SRR01RR" SG_ 388 RL_Sensor_App_Flash_Checksum_Flt 150;
BA_ "GenSigCycleTime" SG_ 388 RL_Host_Kp_Alv_Flsh_Chcksm_Flt 50;
BA_ "GenSigTimeoutTime_SRR01RR" SG_ 388 RL_Host_Kp_Alv_Flsh_Chcksm_Flt 150;
BA_ "GenSigCycleTime" SG_ 388 RL_Host_Pgm_Cal_Flsh_Chcksum_Flt 50;
BA_ "GenSigTimeoutTime_SRR01RR" SG_ 388 RL_Host_Pgm_Cal_Flsh_Chcksum_Flt 150;
BA_ "GenSigCycleTime" SG_ 388 RL_Host_App_Flash_Checksum_Flt 50;
BA_ "GenSigTimeoutTime_SRR01RR" SG_ 388 RL_Host_App_Flash_Checksum_Flt 150;
BA_ "GenSigCycleTime" SG_ 389 RL_USC_Load_Error 50;
BA_ "GenSigTimeoutTime_SRR01RR" SG_ 389 RL_USC_Load_Error 150;
BA_ "GenSigCycleTime" SG_ 389 RL_SMC_Load_Error 50;
BA_ "GenSigTimeoutTime_SRR01RR" SG_ 389 RL_SMC_Load_Error 150;
BA_ "GenSigCycleTime" SG_ 389 RL_TX_Temperature_Flt 50;
BA_ "GenSigTimeoutTime_SRR01RR" SG_ 389 RL_TX_Temperature_Flt 150;
BA_ "GenSigCycleTime" SG_ 389 RL_Dsp_Unit_Cal_Blk_Chcksm_Error 50;
BA_ "GenSigTimeoutTime_SRR01RR" SG_ 389 RL_Dsp_Unit_Cal_Blk_Chcksm_Error 150;
BA_ "GenSigCycleTime" SG_ 389 RL_Dsp_Unit_Cal_Checksum_Error 50;
BA_ "GenSigTimeoutTime_SRR01RR" SG_ 389 RL_Dsp_Unit_Cal_Checksum_Error 150;
BA_ "GenSigCycleTime" SG_ 389 RL_Vertical_Misalignment_error 50;
BA_ "GenSigTimeoutTime_SRR01RR" SG_ 389 RL_Vertical_Misalignment_error 150;
BA_ "GenSigCycleTime" SG_ 389 RL_RTN_SPI_Transfer_Error 50;
BA_ "GenSigTimeoutTime_SRR01RR" SG_ 389 RL_RTN_SPI_Transfer_Error 150;
BA_ "GenSigCycleTime" SG_ 389 RL_RRN_SPI_Transfer_Error 50;
BA_ "GenSigTimeoutTime_SRR01RR" SG_ 389 RL_RRN_SPI_Transfer_Error 150;
BA_ "GenSigCycleTime" SG_ 389 RL_Linearizer_SPI_Transfer_Error 50;
BA_ "GenSigTimeoutTime_SRR01RR" SG_ 389 RL_Linearizer_SPI_Transfer_Error 150;
BA_ "GenSigCycleTime" SG_ 389 RL_ADC_SPI_Transfer_Error 50;
BA_ "GenSigTimeoutTime_SRR01RR" SG_ 389 RL_ADC_SPI_Transfer_Error 150;
BA_ "GenSigCycleTime" SG_ 389 RL_Transmitter_ID_Error 50;
BA_ "GenSigTimeoutTime_SRR01RR" SG_ 389 RL_Transmitter_ID_Error 150;
BA_ "GenSigCycleTime" SG_ 389 RL_Dsp_Loop_Overrun_Error 50;
BA_ "GenSigTimeoutTime_SRR01RR" SG_ 389 RL_Dsp_Loop_Overrun_Error 150;
BA_ "GenSigCycleTime" SG_ 389 RL_Saturated_Tuning_Freq_Error 50;
BA_ "GenSigTimeoutTime_SRR01RR" SG_ 389 RL_Saturated_Tuning_Freq_Error 150;
BA_ "GenSigCycleTime" SG_ 389 RL_Radar_Data_sync_error 50;
BA_ "GenSigTimeoutTime_SRR01RR" SG_ 389 RL_Radar_Data_sync_error 150;
BA_ "GenSigCycleTime" SG_ 389 RL_Dsp_Tuning_Sensitivity_Error 50;
BA_ "GenSigTimeoutTime_SRR01RR" SG_ 389 RL_Dsp_Tuning_Sensitivity_Error 150;
BA_ "GenSigCycleTime" SG_ 389 RL_Radar_LO_Power_Error 50;
BA_ "GenSigTimeoutTime_SRR01RR" SG_ 389 RL_Radar_LO_Power_Error 150;
BA_ "GenSigCycleTime" SG_ 389 RL_Radar_TX_Power_Error 50;
BA_ "GenSigTimeoutTime_SRR01RR" SG_ 389 RL_Radar_TX_Power_Error 150;
BA_ "GenSigCycleTime" SG_ 389 RL_Timer_Create_Error 50;
BA_ "GenSigTimeoutTime_SRR01RR" SG_ 389 RL_Timer_Create_Error 150;
BA_ "GenSigCycleTime" SG_ 389 RL_Thread_Create_Error 50;
BA_ "GenSigTimeoutTime_SRR01RR" SG_ 389 RL_Thread_Create_Error 150;
BA_ "GenSigCycleTime" SG_ 389 RL_ARM_Calibration_Error 50;
BA_ "GenSigTimeoutTime_SRR01RR" SG_ 389 RL_ARM_Calibration_Error 150;
BA_ "GenSigCycleTime" SG_ 389 RL_SPI_FEE_Error 50;
BA_ "GenSigTimeoutTime_SRR01RR" SG_ 389 RL_SPI_FEE_Error 150;
BA_ "GenSigCycleTime" SG_ 389 RL_SPI_Comm_Error 50;
BA_ "GenSigTimeoutTime_SRR01RR" SG_ 389 RL_SPI_Comm_Error 150;
BA_ "GenSigCycleTime" SG_ 389 RL_Socket_Write_Error 50;
BA_ "GenSigTimeoutTime_SRR01RR" SG_ 389 RL_Socket_Write_Error 150;
BA_ "GenSigCycleTime" SG_ 389 RL_Socket_Read_error 50;
BA_ "GenSigTimeoutTime_SRR01RR" SG_ 389 RL_Socket_Read_error 150;
BA_ "GenSigCycleTime" SG_ 389 RL_Socket_Init_Error 50;
BA_ "GenSigTimeoutTime_SRR01RR" SG_ 389 RL_Socket_Init_Error 150;
BA_ "GenSigCycleTime" SG_ 389 RL_Signal_Wait_Error 50;
BA_ "GenSigTimeoutTime_SRR01RR" SG_ 389 RL_Signal_Wait_Error 150;
BA_ "GenSigCycleTime" SG_ 389 RL_Signal_Send_Error 50;
BA_ "GenSigTimeoutTime_SRR01RR" SG_ 389 RL_Signal_Send_Error 150;
BA_ "GenSigCycleTime" SG_ 389 RL_Signal_Create_Error 50;
BA_ "GenSigTimeoutTime_SRR01RR" SG_ 389 RL_Signal_Create_Error 150;
BA_ "GenSigCycleTime" SG_ 389 RL_Shared_Mem_Write_Error 50;
BA_ "GenSigTimeoutTime_SRR01RR" SG_ 389 RL_Shared_Mem_Write_Error 150;
BA_ "GenSigCycleTime" SG_ 389 RL_Shared_Mem_Read_Error 50;
BA_ "GenSigTimeoutTime_SRR01RR" SG_ 389 RL_Shared_Mem_Read_Error 150;
BA_ "GenSigCycleTime" SG_ 389 RL_Shared_Mem_Config_Error 50;
BA_ "GenSigTimeoutTime_SRR01RR" SG_ 389 RL_Shared_Mem_Config_Error 150;
BA_ "GenSigCycleTime" SG_ 389 RL_Share_Mem_Init_Error 50;
BA_ "GenSigTimeoutTime_SRR01RR" SG_ 389 RL_Share_Mem_Init_Error 150;
BA_ "GenSigCycleTime" SG_ 389 RL_RAM_Test_Error 50;
BA_ "GenSigTimeoutTime_SRR01RR" SG_ 389 RL_RAM_Test_Error 150;
BA_ "GenSigCycleTime" SG_ 389 RL_Num_Errors 50;
BA_ "GenSigTimeoutTime_SRR01RR" SG_ 389 RL_Num_Errors 150;
BA_ "GenSigCycleTime" SG_ 389 RL_MMAP_Memory_Error 50;
BA_ "GenSigTimeoutTime_SRR01RR" SG_ 389 RL_MMAP_Memory_Error 150;
BA_ "GenSigCycleTime" SG_ 389 RL_ISR_Attach_Error 50;
BA_ "GenSigTimeoutTime_SRR01RR" SG_ 389 RL_ISR_Attach_Error 150;
BA_ "GenSigCycleTime" SG_ 389 RL_IPC_DRV_Write_Error 50;
BA_ "GenSigTimeoutTime_SRR01RR" SG_ 389 RL_IPC_DRV_Write_Error 150;
BA_ "GenSigCycleTime" SG_ 389 RL_IPC_DRV_Trigger_Error 50;
BA_ "GenSigTimeoutTime_SRR01RR" SG_ 389 RL_IPC_DRV_Trigger_Error 150;
BA_ "GenSigCycleTime" SG_ 389 RL_IPC_DRV_Sync_Error 50;
BA_ "GenSigTimeoutTime_SRR01RR" SG_ 389 RL_IPC_DRV_Sync_Error 150;
BA_ "GenSigCycleTime" SG_ 389 RL_IPC_DRV_Read_Error 50;
BA_ "GenSigTimeoutTime_SRR01RR" SG_ 389 RL_IPC_DRV_Read_Error 150;
BA_ "GenSigCycleTime" SG_ 389 RL_IPC_DRV_Init_Error 50;
BA_ "GenSigTimeoutTime_SRR01RR" SG_ 389 RL_IPC_DRV_Init_Error 150;
BA_ "GenSigCycleTime" SG_ 389 RL_Interrupt_Enable_Error 50;
BA_ "GenSigTimeoutTime_SRR01RR" SG_ 389 RL_Interrupt_Enable_Error 150;
BA_ "GenSigCycleTime" SG_ 389 RL_HIL_Format_Error 50;
BA_ "GenSigTimeoutTime_SRR01RR" SG_ 389 RL_HIL_Format_Error 150;
BA_ "GenSigCycleTime" SG_ 389 RL_Flash_Filesystem_Error 50;
BA_ "GenSigTimeoutTime_SRR01RR" SG_ 389 RL_Flash_Filesystem_Error 150;
BA_ "GenSigCycleTime" SG_ 389 RL_Error_none 50;
BA_ "GenSigTimeoutTime_SRR01RR" SG_ 389 RL_Error_none 150;
BA_ "GenSigCycleTime" SG_ 389 RL_Dsp_Load_Read_Error 50;
BA_ "GenSigTimeoutTime_SRR01RR" SG_ 389 RL_Dsp_Load_Read_Error 150;
BA_ "GenSigCycleTime" SG_ 389 RL_Dsp_Load_Open_Error 50;
BA_ "GenSigTimeoutTime_SRR01RR" SG_ 389 RL_Dsp_Load_Open_Error 150;
BA_ "GenSigCycleTime" SG_ 389 RL_Dsp_Load_Address_Error 50;
BA_ "GenSigTimeoutTime_SRR01RR" SG_ 389 RL_Dsp_Load_Address_Error 150;
BA_ "GenSigCycleTime" SG_ 389 RL_Dsp_ISP_Write_Error 50;
BA_ "GenSigTimeoutTime_SRR01RR" SG_ 389 RL_Dsp_ISP_Write_Error 150;
BA_ "GenSigCycleTime" SG_ 389 RL_Dsp_IPC_Read_Error 50;
BA_ "GenSigTimeoutTime_SRR01RR" SG_ 389 RL_Dsp_IPC_Read_Error 150;
BA_ "GenSigCycleTime" SG_ 389 RL_Dsp_IPC_Init 50;
BA_ "GenSigTimeoutTime_SRR01RR" SG_ 389 RL_Dsp_IPC_Init 150;
BA_ "GenSigCycleTime" SG_ 389 RL_Dsp_Init_Error 50;
BA_ "GenSigTimeoutTime_SRR01RR" SG_ 389 RL_Dsp_Init_Error 150;
BA_ "GenSigCycleTime" SG_ 389 RL_Dsp_DRV_Start_Error 50;
BA_ "GenSigTimeoutTime_SRR01RR" SG_ 389 RL_Dsp_DRV_Start_Error 150;
BA_ "GenSigCycleTime" SG_ 389 RL_Dsp_DRV_Load_Error 50;
BA_ "GenSigTimeoutTime_SRR01RR" SG_ 389 RL_Dsp_DRV_Load_Error 150;
BA_ "GenSigCycleTime" SG_ 389 RL_Dsp_DRV_Init_Error 50;
BA_ "GenSigTimeoutTime_SRR01RR" SG_ 389 RL_Dsp_DRV_Init_Error 150;
BA_ "GenSigCycleTime" SG_ 389 RL_Dsp_DRV_Init2_error 50;
BA_ "GenSigTimeoutTime_SRR01RR" SG_ 389 RL_Dsp_DRV_Init2_error 150;
BA_ "GenSigCycleTime" SG_ 389 RL_Dsp_DRV_Init1_error 50;
BA_ "GenSigTimeoutTime_SRR01RR" SG_ 389 RL_Dsp_DRV_Init1_error 150;
BA_ "GenSigCycleTime" SG_ 389 RL_CAN_XMT_Error 50;
BA_ "GenSigTimeoutTime_SRR01RR" SG_ 389 RL_CAN_XMT_Error 150;
BA_ "GenSigCycleTime" SG_ 389 RL_CAN_RCV_Error 50;
BA_ "GenSigTimeoutTime_SRR01RR" SG_ 389 RL_CAN_RCV_Error 150;
BA_ "GenSigCycleTime" SG_ 389 RL_CAN_Hardware_Error 50;
BA_ "GenSigTimeoutTime_SRR01RR" SG_ 389 RL_CAN_Hardware_Error 150;
BA_ "GenSigCycleTime" SG_ 389 RL_Always_True 50;
BA_ "GenSigTimeoutTime_SRR01RR" SG_ 389 RL_Always_True 150;
BA_ "GenSigCycleTime" SG_ 390 RL_CAN_TX_MUX_SVK_CAL_DATA_5 50;
BA_ "GenSigTimeoutTime_SRR01RR" SG_ 390 RL_CAN_TX_MUX_SVK_CAL_DATA_5 150;
BA_ "GenSigCycleTime" SG_ 390 RL_CAN_TX_MUX_SVK_CAL_DATA_4 50;
BA_ "GenSigTimeoutTime_SRR01RR" SG_ 390 RL_CAN_TX_MUX_SVK_CAL_DATA_4 150;
BA_ "GenSigCycleTime" SG_ 390 RL_CAN_TX_MUX_SVK_CAL_DATA_3 50;
BA_ "GenSigTimeoutTime_SRR01RR" SG_ 390 RL_CAN_TX_MUX_SVK_CAL_DATA_3 150;
BA_ "GenSigCycleTime" SG_ 390 RL_CAN_TX_MUX_SVK_CAL_DATA_2 50;
BA_ "GenSigTimeoutTime_SRR01RR" SG_ 390 RL_CAN_TX_MUX_SVK_CAL_DATA_2 150;
BA_ "GenSigCycleTime" SG_ 390 RL_CAN_TX_MUX_SVK_CAL_DATA_1 50;
BA_ "GenSigTimeoutTime_SRR01RR" SG_ 390 RL_CAN_TX_MUX_SVK_CAL_DATA_1 150;
BA_ "GenSigCycleTime" SG_ 390 RL_CAN_TX_MUX_SVK_CAL_DATA_0 50;
BA_ "GenSigTimeoutTime_SRR01RR" SG_ 390 RL_CAN_TX_MUX_SVK_CAL_DATA_0 150;
BA_ "GenSigCycleTime" SG_ 390 RL_CAN_TX_MUX_SVK_CAL_MSG_CNT 50;
BA_ "GenSigTimeoutTime_SRR01RR" SG_ 390 RL_CAN_TX_MUX_SVK_CAL_MSG_CNT 150;
BA_ "GenSigCycleTime" SG_ 390 RL_CAN_TX_MUX_RCWM_CAL_MSG_CNT 50;
BA_ "GenSigTimeoutTime_SRR01RR" SG_ 390 RL_CAN_TX_MUX_RCWM_CAL_MSG_CNT 150;
BA_ "GenSigCycleTime" SG_ 390 RL_CAN_TX_MUX_RCWM_CAL_DATA_0 50;
BA_ "GenSigTimeoutTime_SRR01RR" SG_ 390 RL_CAN_TX_MUX_RCWM_CAL_DATA_0 150;
BA_ "GenSigCycleTime" SG_ 390 RL_CAN_TX_MUX_RCWM_CAL_DATA_1 50;
BA_ "GenSigTimeoutTime_SRR01RR" SG_ 390 RL_CAN_TX_MUX_RCWM_CAL_DATA_1 150;
BA_ "GenSigCycleTime" SG_ 390 RL_CAN_TX_MUX_RCWM_CAL_DATA_2 50;
BA_ "GenSigTimeoutTime_SRR01RR" SG_ 390 RL_CAN_TX_MUX_RCWM_CAL_DATA_2 150;
BA_ "GenSigCycleTime" SG_ 390 RL_CAN_TX_MUX_RCWM_CAL_DATA_3 50;
BA_ "GenSigTimeoutTime_SRR01RR" SG_ 390 RL_CAN_TX_MUX_RCWM_CAL_DATA_3 150;
BA_ "GenSigCycleTime" SG_ 390 RL_CAN_TX_MUX_RCWM_CAL_DATA_4 50;
BA_ "GenSigTimeoutTime_SRR01RR" SG_ 390 RL_CAN_TX_MUX_RCWM_CAL_DATA_4 150;
BA_ "GenSigCycleTime" SG_ 390 RL_CAN_TX_MUX_RCWM_CAL_DATA_5 50;
BA_ "GenSigTimeoutTime_SRR01RR" SG_ 390 RL_CAN_TX_MUX_RCWM_CAL_DATA_5 150;
BA_ "GenSigCycleTime" SG_ 390 RL_CAN_TX_MUX_RECW_CAL_MSG_CNT 50;
BA_ "GenSigTimeoutTime_SRR01RR" SG_ 390 RL_CAN_TX_MUX_RECW_CAL_MSG_CNT 150;
BA_ "GenSigCycleTime" SG_ 390 RL_CAN_TX_MUX_RECW_CAL_DATA_0 50;
BA_ "GenSigTimeoutTime_SRR01RR" SG_ 390 RL_CAN_TX_MUX_RECW_CAL_DATA_0 150;
BA_ "GenSigCycleTime" SG_ 390 RL_CAN_TX_MUX_RECW_CAL_DATA_1 50;
BA_ "GenSigTimeoutTime_SRR01RR" SG_ 390 RL_CAN_TX_MUX_RECW_CAL_DATA_1 150;
BA_ "GenSigCycleTime" SG_ 390 RL_CAN_TX_MUX_RECW_CAL_DATA_2 50;
BA_ "GenSigTimeoutTime_SRR01RR" SG_ 390 RL_CAN_TX_MUX_RECW_CAL_DATA_2 150;
BA_ "GenSigCycleTime" SG_ 390 RL_CAN_TX_MUX_RECW_CAL_DATA_3 50;
BA_ "GenSigTimeoutTime_SRR01RR" SG_ 390 RL_CAN_TX_MUX_RECW_CAL_DATA_3 150;
BA_ "GenSigCycleTime" SG_ 390 RL_CAN_TX_MUX_RECW_CAL_DATA_4 50;
BA_ "GenSigTimeoutTime_SRR01RR" SG_ 390 RL_CAN_TX_MUX_RECW_CAL_DATA_4 150;
BA_ "GenSigCycleTime" SG_ 390 RL_CAN_TX_MUX_RECW_CAL_DATA_5 50;
BA_ "GenSigTimeoutTime_SRR01RR" SG_ 390 RL_CAN_TX_MUX_RECW_CAL_DATA_5 150;
BA_ "GenSigCycleTime" SG_ 390 RL_CAN_TX_MUX_FRESPCE_CALMSG_CNT 50;
BA_ "GenSigTimeoutTime_SRR01RR" SG_ 390 RL_CAN_TX_MUX_FRESPCE_CALMSG_CNT 150;
BA_ "GenSigCycleTime" SG_ 390 RL_CAN_TX_MUX_FRESPCE_CAL_DATA_0 50;
BA_ "GenSigTimeoutTime_SRR01RR" SG_ 390 RL_CAN_TX_MUX_FRESPCE_CAL_DATA_0 150;
BA_ "GenSigCycleTime" SG_ 390 RL_CAN_TX_MUX_FRESPCE_CAL_DATA_1 50;
BA_ "GenSigTimeoutTime_SRR01RR" SG_ 390 RL_CAN_TX_MUX_FRESPCE_CAL_DATA_1 150;
BA_ "GenSigCycleTime" SG_ 390 RL_CAN_TX_MUX_FRESPCE_CAL_DATA_2 50;
BA_ "GenSigTimeoutTime_SRR01RR" SG_ 390 RL_CAN_TX_MUX_FRESPCE_CAL_DATA_2 150;
BA_ "GenSigCycleTime" SG_ 390 RL_CAN_TX_MUX_FRESPCE_CAL_DATA_3 50;
BA_ "GenSigTimeoutTime_SRR01RR" SG_ 390 RL_CAN_TX_MUX_FRESPCE_CAL_DATA_3 150;
BA_ "GenSigCycleTime" SG_ 390 RL_CAN_TX_MUX_FRESPCE_CAL_DATA_4 50;
BA_ "GenSigTimeoutTime_SRR01RR" SG_ 390 RL_CAN_TX_MUX_FRESPCE_CAL_DATA_4 150;
BA_ "GenSigCycleTime" SG_ 390 RL_CAN_TX_MUX_FRESPCE_CAL_DATA_5 50;
BA_ "GenSigTimeoutTime_SRR01RR" SG_ 390 RL_CAN_TX_MUX_FRESPCE_CAL_DATA_5 150;
BA_ "GenSigCycleTime" SG_ 390 RL_CAN_TX_MUX_LCDA_CAL_MSG_CNT 50;
BA_ "GenSigTimeoutTime_SRR01RR" SG_ 390 RL_CAN_TX_MUX_LCDA_CAL_MSG_CNT 150;
BA_ "GenSigCycleTime" SG_ 390 RL_CAN_TX_MUX_LCDA_CAL_DATA_0 50;
BA_ "GenSigTimeoutTime_SRR01RR" SG_ 390 RL_CAN_TX_MUX_LCDA_CAL_DATA_0 150;
BA_ "GenSigCycleTime" SG_ 390 RL_CAN_TX_MUX_LCDA_CAL_DATA_1 50;
BA_ "GenSigTimeoutTime_SRR01RR" SG_ 390 RL_CAN_TX_MUX_LCDA_CAL_DATA_1 150;
BA_ "GenSigCycleTime" SG_ 390 RL_CAN_TX_MUX_LCDA_CAL_DATA_2 50;
BA_ "GenSigTimeoutTime_SRR01RR" SG_ 390 RL_CAN_TX_MUX_LCDA_CAL_DATA_2 150;
BA_ "GenSigCycleTime" SG_ 390 RL_CAN_TX_MUX_LCDA_CAL_DATA_3 50;
BA_ "GenSigTimeoutTime_SRR01RR" SG_ 390 RL_CAN_TX_MUX_LCDA_CAL_DATA_3 150;
BA_ "GenSigCycleTime" SG_ 390 RL_CAN_TX_MUX_LCDA_CAL_DATA_4 50;
BA_ "GenSigTimeoutTime_SRR01RR" SG_ 390 RL_CAN_TX_MUX_LCDA_CAL_DATA_4 150;
BA_ "GenSigCycleTime" SG_ 390 RL_CAN_TX_MUX_LCDA_CAL_DATA_5 50;
BA_ "GenSigTimeoutTime_SRR01RR" SG_ 390 RL_CAN_TX_MUX_LCDA_CAL_DATA_5 150;
BA_ "GenSigCycleTime" SG_ 390 RL_CAN_TX_MUX_CTA_CAL_MSG_CNT 50;
BA_ "GenSigTimeoutTime_SRR01RR" SG_ 390 RL_CAN_TX_MUX_CTA_CAL_MSG_CNT 150;
BA_ "GenSigCycleTime" SG_ 390 RL_CAN_TX_MUX_CTA_CAL_DATA_0 50;
BA_ "GenSigTimeoutTime_SRR01RR" SG_ 390 RL_CAN_TX_MUX_CTA_CAL_DATA_0 150;
BA_ "GenSigCycleTime" SG_ 390 RL_CAN_TX_MUX_CTA_CAL_DATA_1 50;
BA_ "GenSigTimeoutTime_SRR01RR" SG_ 390 RL_CAN_TX_MUX_CTA_CAL_DATA_1 150;
BA_ "GenSigCycleTime" SG_ 390 RL_CAN_TX_MUX_CTA_CAL_DATA_2 50;
BA_ "GenSigTimeoutTime_SRR01RR" SG_ 390 RL_CAN_TX_MUX_CTA_CAL_DATA_2 150;
BA_ "GenSigCycleTime" SG_ 390 RL_CAN_TX_MUX_CTA_CAL_DATA_3 50;
BA_ "GenSigTimeoutTime_SRR01RR" SG_ 390 RL_CAN_TX_MUX_CTA_CAL_DATA_3 150;
BA_ "GenSigCycleTime" SG_ 390 RL_CAN_TX_MUX_CTA_CAL_DATA_4 50;
BA_ "GenSigTimeoutTime_SRR01RR" SG_ 390 RL_CAN_TX_MUX_CTA_CAL_DATA_4 150;
BA_ "GenSigCycleTime" SG_ 390 RL_CAN_TX_MUX_CTA_CAL_DATA_5 50;
BA_ "GenSigTimeoutTime_SRR01RR" SG_ 390 RL_CAN_TX_MUX_CTA_CAL_DATA_5 150;
BA_ "GenSigCycleTime" SG_ 390 RL_CAN_TX_MUX_LOOKID_CAL_MSG_CNT 50;
BA_ "GenSigTimeoutTime_SRR01RR" SG_ 390 RL_CAN_TX_MUX_LOOKID_CAL_MSG_CNT 150;
BA_ "GenSigCycleTime" SG_ 390 RL_CAN_TX_MUX_LOOKID_CAL_DATA_0 50;
BA_ "GenSigTimeoutTime_SRR01RR" SG_ 390 RL_CAN_TX_MUX_LOOKID_CAL_DATA_0 150;
BA_ "GenSigCycleTime" SG_ 390 RL_CAN_TX_MUX_LOOKID_CAL_DATA_1 50;
BA_ "GenSigTimeoutTime_SRR01RR" SG_ 390 RL_CAN_TX_MUX_LOOKID_CAL_DATA_1 150;
BA_ "GenSigCycleTime" SG_ 390 RL_CAN_TX_MUX_LOOKID_CAL_DATA_2 50;
BA_ "GenSigTimeoutTime_SRR01RR" SG_ 390 RL_CAN_TX_MUX_LOOKID_CAL_DATA_2 150;
BA_ "GenSigCycleTime" SG_ 390 RL_CAN_TX_MUX_LOOKID_CAL_DATA_3 50;
BA_ "GenSigTimeoutTime_SRR01RR" SG_ 390 RL_CAN_TX_MUX_LOOKID_CAL_DATA_3 150;
BA_ "GenSigCycleTime" SG_ 390 RL_CAN_TX_MUX_LOOKID_CAL_DATA_4 50;
BA_ "GenSigTimeoutTime_SRR01RR" SG_ 390 RL_CAN_TX_MUX_LOOKID_CAL_DATA_4 150;
BA_ "GenSigCycleTime" SG_ 390 RL_CAN_TX_MUX_LOOKID_CAL_DATA_5 50;
BA_ "GenSigTimeoutTime_SRR01RR" SG_ 390 RL_CAN_TX_MUX_LOOKID_CAL_DATA_5 150;
BA_ "GenSigCycleTime" SG_ 390 RL_CAN_TX_MUX_ALIGNMT_CALMSG_CNT 50;
BA_ "GenSigTimeoutTime_SRR01RR" SG_ 390 RL_CAN_TX_MUX_ALIGNMT_CALMSG_CNT 150;
BA_ "GenSigCycleTime" SG_ 390 RL_CAN_TX_MUX_ALIGNMT_CAL_DATA_0 50;
BA_ "GenSigTimeoutTime_SRR01RR" SG_ 390 RL_CAN_TX_MUX_ALIGNMT_CAL_DATA_0 150;
BA_ "GenSigCycleTime" SG_ 390 RL_CAN_TX_MUX_ALIGNMT_CAL_DATA_1 50;
BA_ "GenSigTimeoutTime_SRR01RR" SG_ 390 RL_CAN_TX_MUX_ALIGNMT_CAL_DATA_1 150;
BA_ "GenSigCycleTime" SG_ 390 RL_CAN_TX_MUX_ALIGNMT_CAL_DATA_2 50;
BA_ "GenSigTimeoutTime_SRR01RR" SG_ 390 RL_CAN_TX_MUX_ALIGNMT_CAL_DATA_2 150;
BA_ "GenSigCycleTime" SG_ 390 RL_CAN_TX_MUX_ALIGNMT_CAL_DATA_3 50;
BA_ "GenSigTimeoutTime_SRR01RR" SG_ 390 RL_CAN_TX_MUX_ALIGNMT_CAL_DATA_3 150;
BA_ "GenSigCycleTime" SG_ 390 RL_CAN_TX_MUX_ALIGNMT_CAL_DATA_4 50;
BA_ "GenSigTimeoutTime_SRR01RR" SG_ 390 RL_CAN_TX_MUX_ALIGNMT_CAL_DATA_4 150;
BA_ "GenSigCycleTime" SG_ 390 RL_CAN_TX_MUX_ALIGNMT_CAL_DATA_5 50;
BA_ "GenSigTimeoutTime_SRR01RR" SG_ 390 RL_CAN_TX_MUX_ALIGNMT_CAL_DATA_5 150;
BA_ "GenSigCycleTime" SG_ 390 RL_CAN_TX_MUX_TRKER_CAL_MSG_CNT 50;
BA_ "GenSigTimeoutTime_SRR01RR" SG_ 390 RL_CAN_TX_MUX_TRKER_CAL_MSG_CNT 150;
BA_ "GenSigCycleTime" SG_ 390 RL_CAN_TX_MUX_TRKER_CAL_DATA_0 50;
BA_ "GenSigTimeoutTime_SRR01RR" SG_ 390 RL_CAN_TX_MUX_TRKER_CAL_DATA_0 150;
BA_ "GenSigCycleTime" SG_ 390 RL_CAN_TX_MUX_TRKER_CAL_DATA_1 50;
BA_ "GenSigTimeoutTime_SRR01RR" SG_ 390 RL_CAN_TX_MUX_TRKER_CAL_DATA_1 150;
BA_ "GenSigCycleTime" SG_ 390 RL_CAN_TX_MUX_TRKER_CAL_DATA_2 50;
BA_ "GenSigTimeoutTime_SRR01RR" SG_ 390 RL_CAN_TX_MUX_TRKER_CAL_DATA_2 150;
BA_ "GenSigCycleTime" SG_ 390 RL_CAN_TX_MUX_TRKER_CAL_DATA_3 50;
BA_ "GenSigTimeoutTime_SRR01RR" SG_ 390 RL_CAN_TX_MUX_TRKER_CAL_DATA_3 150;
BA_ "GenSigCycleTime" SG_ 390 RL_CAN_TX_MUX_TRKER_CAL_DATA_4 50;
BA_ "GenSigTimeoutTime_SRR01RR" SG_ 390 RL_CAN_TX_MUX_TRKER_CAL_DATA_4 150;
BA_ "GenSigCycleTime" SG_ 390 RL_CAN_TX_MUX_TRKER_CAL_DATA_5 50;
BA_ "GenSigTimeoutTime_SRR01RR" SG_ 390 RL_CAN_TX_MUX_TRKER_CAL_DATA_5 150;
BA_ "GenSigCycleTime" SG_ 390 RL_CAN_TX_MUX_SMC_CAL_MSG_CNT 50;
BA_ "GenSigTimeoutTime_SRR01RR" SG_ 390 RL_CAN_TX_MUX_SMC_CAL_MSG_CNT 150;
BA_ "GenSigCycleTime" SG_ 390 RL_CAN_TX_MUX_SMC_CAL_DATA_0 50;
BA_ "GenSigTimeoutTime_SRR01RR" SG_ 390 RL_CAN_TX_MUX_SMC_CAL_DATA_0 150;
BA_ "GenSigCycleTime" SG_ 390 RL_CAN_TX_MUX_SMC_CAL_DATA_1 50;
BA_ "GenSigTimeoutTime_SRR01RR" SG_ 390 RL_CAN_TX_MUX_SMC_CAL_DATA_1 150;
BA_ "GenSigCycleTime" SG_ 390 RL_CAN_TX_MUX_SMC_CAL_DATA_2 50;
BA_ "GenSigTimeoutTime_SRR01RR" SG_ 390 RL_CAN_TX_MUX_SMC_CAL_DATA_2 150;
BA_ "GenSigCycleTime" SG_ 390 RL_CAN_TX_MUX_SMC_CAL_DATA_3 50;
BA_ "GenSigTimeoutTime_SRR01RR" SG_ 390 RL_CAN_TX_MUX_SMC_CAL_DATA_3 150;
BA_ "GenSigCycleTime" SG_ 390 RL_CAN_TX_MUX_SMC_CAL_DATA_4 50;
BA_ "GenSigTimeoutTime_SRR01RR" SG_ 390 RL_CAN_TX_MUX_SMC_CAL_DATA_4 150;
BA_ "GenSigCycleTime" SG_ 390 RL_CAN_TX_MUX_SMC_CAL_DATA_5 50;
BA_ "GenSigTimeoutTime_SRR01RR" SG_ 390 RL_CAN_TX_MUX_SMC_CAL_DATA_5 150;
BA_ "GenSigCycleTime" SG_ 390 RL_CAN_TX_MUX_USC_CAL_MSG_CNT 50;
BA_ "GenSigTimeoutTime_SRR01RR" SG_ 390 RL_CAN_TX_MUX_USC_CAL_MSG_CNT 150;
BA_ "GenSigCycleTime" SG_ 390 RL_CAN_TX_MUX_USC_CAL_DATA_0 50;
BA_ "GenSigTimeoutTime_SRR01RR" SG_ 390 RL_CAN_TX_MUX_USC_CAL_DATA_0 150;
BA_ "GenSigCycleTime" SG_ 390 RL_CAN_TX_MUX_USC_CAL_DATA_1 50;
BA_ "GenSigTimeoutTime_SRR01RR" SG_ 390 RL_CAN_TX_MUX_USC_CAL_DATA_1 150;
BA_ "GenSigCycleTime" SG_ 390 RL_CAN_TX_MUX_USC_CAL_DATA_2 50;
BA_ "GenSigTimeoutTime_SRR01RR" SG_ 390 RL_CAN_TX_MUX_USC_CAL_DATA_2 150;
BA_ "GenSigCycleTime" SG_ 390 RL_CAN_TX_MUX_USC_CAL_DATA_3 50;
BA_ "GenSigTimeoutTime_SRR01RR" SG_ 390 RL_CAN_TX_MUX_USC_CAL_DATA_3 150;
BA_ "GenSigCycleTime" SG_ 390 RL_CAN_TX_MUX_USC_CAL_DATA_4 50;
BA_ "GenSigTimeoutTime_SRR01RR" SG_ 390 RL_CAN_TX_MUX_USC_CAL_DATA_4 150;
BA_ "GenSigCycleTime" SG_ 390 RL_CAN_TX_MUX_USC_CAL_DATA_5 50;
BA_ "GenSigTimeoutTime_SRR01RR" SG_ 390 RL_CAN_TX_MUX_USC_CAL_DATA_5 150;
BA_ "GenSigCycleTime" SG_ 390 RL_CAN_TX_MUX_ALIGN_CAL_VER_MNR 50;
BA_ "GenSigTimeoutTime_SRR01RR" SG_ 390 RL_CAN_TX_MUX_ALIGN_CAL_VER_MNR 150;
BA_ "GenSigCycleTime" SG_ 390 RL_CAN_TX_MUX_ALIGN_CAL_VER_MJR 50;
BA_ "GenSigTimeoutTime_SRR01RR" SG_ 390 RL_CAN_TX_MUX_ALIGN_CAL_VER_MJR 150;
BA_ "GenSigCycleTime" SG_ 390 RL_CAN_TX_MUX_ALIGN_SW_VER_MINOR 50;
BA_ "GenSigTimeoutTime_SRR01RR" SG_ 390 RL_CAN_TX_MUX_ALIGN_SW_VER_MINOR 150;
BA_ "GenSigCycleTime" SG_ 390 RL_CAN_TX_MUX_ALIGN_SW_VER_MAJOR 50;
BA_ "GenSigTimeoutTime_SRR01RR" SG_ 390 RL_CAN_TX_MUX_ALIGN_SW_VER_MAJOR 150;
BA_ "GenSigCycleTime" SG_ 390 RL_CAN_TX_MUX_USC_CAL_VER_MAJOR 50;
BA_ "GenSigTimeoutTime_SRR01RR" SG_ 390 RL_CAN_TX_MUX_USC_CAL_VER_MAJOR 150;
BA_ "GenSigCycleTime" SG_ 390 RL_CAN_TX_MUX_TRKR_CAL_VER_MINOR 50;
BA_ "GenSigTimeoutTime_SRR01RR" SG_ 390 RL_CAN_TX_MUX_TRKR_CAL_VER_MINOR 150;
BA_ "GenSigCycleTime" SG_ 390 RL_CAN_TX_MUX_TRKR_CAL_VER_MAJOR 50;
BA_ "GenSigTimeoutTime_SRR01RR" SG_ 390 RL_CAN_TX_MUX_TRKR_CAL_VER_MAJOR 150;
BA_ "GenSigCycleTime" SG_ 390 RL_CAN_TX_MUX_TRKR_SW_VER_MINOR 50;
BA_ "GenSigTimeoutTime_SRR01RR" SG_ 390 RL_CAN_TX_MUX_TRKR_SW_VER_MINOR 150;
BA_ "GenSigCycleTime" SG_ 390 RL_CAN_TX_MUX_TRKR_SW_VER_MAJOR 50;
BA_ "GenSigTimeoutTime_SRR01RR" SG_ 390 RL_CAN_TX_MUX_TRKR_SW_VER_MAJOR 150;
BA_ "GenSigCycleTime" SG_ 390 RL_CAN_TX_MUX_SMC_CAL_VER_MINOR 50;
BA_ "GenSigTimeoutTime_SRR01RR" SG_ 390 RL_CAN_TX_MUX_SMC_CAL_VER_MINOR 150;
BA_ "GenSigCycleTime" SG_ 390 RL_CAN_TX_MUX_SMC_CAL_VER_MAJOR 50;
BA_ "GenSigTimeoutTime_SRR01RR" SG_ 390 RL_CAN_TX_MUX_SMC_CAL_VER_MAJOR 150;
BA_ "GenSigCycleTime" SG_ 390 RL_CAN_TX_MUX_RECW_CAL_VER_MINOR 50;
BA_ "GenSigTimeoutTime_SRR01RR" SG_ 390 RL_CAN_TX_MUX_RECW_CAL_VER_MINOR 150;
BA_ "GenSigCycleTime" SG_ 390 RL_CAN_TX_MUX_RECW_CAL_VER_MAJOR 50;
BA_ "GenSigTimeoutTime_SRR01RR" SG_ 390 RL_CAN_TX_MUX_RECW_CAL_VER_MAJOR 150;
BA_ "GenSigCycleTime" SG_ 390 RL_CAN_TX_MUX_RECW_SW_VER_MINOR 50;
BA_ "GenSigTimeoutTime_SRR01RR" SG_ 390 RL_CAN_TX_MUX_RECW_SW_VER_MINOR 150;
BA_ "GenSigCycleTime" SG_ 390 RL_CAN_TX_MUX_RECW_SW_VER_MAJOR 50;
BA_ "GenSigTimeoutTime_SRR01RR" SG_ 390 RL_CAN_TX_MUX_RECW_SW_VER_MAJOR 150;
BA_ "GenSigCycleTime" SG_ 390 RL_CAN_TX_MUX_RCWM_CAL_VER_MINOR 50;
BA_ "GenSigTimeoutTime_SRR01RR" SG_ 390 RL_CAN_TX_MUX_RCWM_CAL_VER_MINOR 150;
BA_ "GenSigCycleTime" SG_ 390 RL_CAN_TX_MUX_RCWM_CAL_VER_MAJOR 50;
BA_ "GenSigTimeoutTime_SRR01RR" SG_ 390 RL_CAN_TX_MUX_RCWM_CAL_VER_MAJOR 150;
BA_ "GenSigCycleTime" SG_ 390 RL_CAN_TX_MUX_RCWM_SW_VER_MINOR 50;
BA_ "GenSigTimeoutTime_SRR01RR" SG_ 390 RL_CAN_TX_MUX_RCWM_SW_VER_MINOR 150;
BA_ "GenSigCycleTime" SG_ 390 RL_CAN_TX_MUX_RCWM_SW_VER_MAJOR 50;
BA_ "GenSigTimeoutTime_SRR01RR" SG_ 390 RL_CAN_TX_MUX_RCWM_SW_VER_MAJOR 150;
BA_ "GenSigCycleTime" SG_ 390 RL_CAN_TX_MUX_RCTA_CAL_VER_MINOR 50;
BA_ "GenSigTimeoutTime_SRR01RR" SG_ 390 RL_CAN_TX_MUX_RCTA_CAL_VER_MINOR 150;
BA_ "GenSigCycleTime" SG_ 390 RL_CAN_TX_MUX_RCTA_CAL_VER_MAJOR 50;
BA_ "GenSigTimeoutTime_SRR01RR" SG_ 390 RL_CAN_TX_MUX_RCTA_CAL_VER_MAJOR 150;
BA_ "GenSigCycleTime" SG_ 390 RL_CAN_TX_MUX_RCTA_SW_VER_MINOR 50;
BA_ "GenSigTimeoutTime_SRR01RR" SG_ 390 RL_CAN_TX_MUX_RCTA_SW_VER_MINOR 150;
BA_ "GenSigCycleTime" SG_ 390 RL_CAN_TX_MUX_RCTA_SW_VER_MAJOR 50;
BA_ "GenSigTimeoutTime_SRR01RR" SG_ 390 RL_CAN_TX_MUX_RCTA_SW_VER_MAJOR 150;
BA_ "GenSigCycleTime" SG_ 390 RL_CAN_TX_MUX_LCDA_CAL_VER_MINOR 50;
BA_ "GenSigTimeoutTime_SRR01RR" SG_ 390 RL_CAN_TX_MUX_LCDA_CAL_VER_MINOR 150;
BA_ "GenSigCycleTime" SG_ 390 RL_CAN_TX_MUX_LCDA_CAL_VER_MAJOR 50;
BA_ "GenSigTimeoutTime_SRR01RR" SG_ 390 RL_CAN_TX_MUX_LCDA_CAL_VER_MAJOR 150;
BA_ "GenSigCycleTime" SG_ 390 RL_CAN_TX_MUX_LCDA_SW_VER_MINOR 50;
BA_ "GenSigTimeoutTime_SRR01RR" SG_ 390 RL_CAN_TX_MUX_LCDA_SW_VER_MINOR 150;
BA_ "GenSigCycleTime" SG_ 390 RL_CAN_TX_MUX_LCDA_SW_VER_MAJOR 50;
BA_ "GenSigTimeoutTime_SRR01RR" SG_ 390 RL_CAN_TX_MUX_LCDA_SW_VER_MAJOR 150;
BA_ "GenSigCycleTime" SG_ 390 RL_CAN_TX_MUX_FRESP_CAL_VER_MNR 50;
BA_ "GenSigTimeoutTime_SRR01RR" SG_ 390 RL_CAN_TX_MUX_FRESP_CAL_VER_MNR 150;
BA_ "GenSigCycleTime" SG_ 390 RL_CAN_TX_MUX_FRESP_CAL_VER_MJR 50;
BA_ "GenSigTimeoutTime_SRR01RR" SG_ 390 RL_CAN_TX_MUX_FRESP_CAL_VER_MJR 150;
BA_ "GenSigCycleTime" SG_ 390 RL_CAN_TX_MUX_FRESP_SW_VER_MINOR 50;
BA_ "GenSigTimeoutTime_SRR01RR" SG_ 390 RL_CAN_TX_MUX_FRESP_SW_VER_MINOR 150;
BA_ "GenSigCycleTime" SG_ 390 RL_CAN_TX_MUX_FRESP_SW_VER_MAJOR 50;
BA_ "GenSigTimeoutTime_SRR01RR" SG_ 390 RL_CAN_TX_MUX_FRESP_SW_VER_MAJOR 150;
BA_ "GenSigCycleTime" SG_ 390 RL_CAN_TX_MUX_FCTA_CAL_VER_MINOR 50;
BA_ "GenSigTimeoutTime_SRR01RR" SG_ 390 RL_CAN_TX_MUX_FCTA_CAL_VER_MINOR 150;
BA_ "GenSigCycleTime" SG_ 390 RL_CAN_TX_MUX_FCTA_CAL_VER_MAJOR 50;
BA_ "GenSigTimeoutTime_SRR01RR" SG_ 390 RL_CAN_TX_MUX_FCTA_CAL_VER_MAJOR 150;
BA_ "GenSigCycleTime" SG_ 390 RL_CAN_TX_MUX_FCTA_SW_VER_MINOR 50;
BA_ "GenSigTimeoutTime_SRR01RR" SG_ 390 RL_CAN_TX_MUX_FCTA_SW_VER_MINOR 150;
BA_ "GenSigCycleTime" SG_ 390 RL_CAN_TX_MUX_FCTA_SW_VER_MAJOR 50;
BA_ "GenSigTimeoutTime_SRR01RR" SG_ 390 RL_CAN_TX_MUX_FCTA_SW_VER_MAJOR 150;
BA_ "GenSigCycleTime" SG_ 390 RL_CAN_TX_MUX_VCS_OFFSET_LONG 50;
BA_ "GenSigTimeoutTime_SRR01RR" SG_ 390 RL_CAN_TX_MUX_VCS_OFFSET_LONG 150;
BA_ "GenSigStartValue" SG_ 390 RL_CAN_TX_MUX_VCS_OFFSET_LONG 65535;
BA_ "GenSigCycleTime" SG_ 390 RL_CAN_TX_MUX_VCS_OFFSET_LAT 50;
BA_ "GenSigTimeoutTime_SRR01RR" SG_ 390 RL_CAN_TX_MUX_VCS_OFFSET_LAT 150;
BA_ "GenSigStartValue" SG_ 390 RL_CAN_TX_MUX_VCS_OFFSET_LAT 32767.5;
BA_ "GenSigCycleTime" SG_ 390 RL_CAN_TX_MUX_CORE_VERSION 50;
BA_ "GenSigTimeoutTime_SRR01RR" SG_ 390 RL_CAN_TX_MUX_CORE_VERSION 150;
BA_ "GenSigCycleTime" SG_ 390 RL_CAN_TX_MUX_SENSOR_POLARITY 50;
BA_ "GenSigTimeoutTime_SRR01RR" SG_ 390 RL_CAN_TX_MUX_SENSOR_POLARITY 150;
BA_ "GenSigCycleTime" SG_ 390 RL_CAN_TX_MUX_SENSOR_LAT_OFFSET 50;
BA_ "GenSigTimeoutTime_SRR01RR" SG_ 390 RL_CAN_TX_MUX_SENSOR_LAT_OFFSET 150;
BA_ "GenSigCycleTime" SG_ 390 RL_CAN_TX_MUX_SENSOR_LONG_OFFSET 50;
BA_ "GenSigTimeoutTime_SRR01RR" SG_ 390 RL_CAN_TX_MUX_SENSOR_LONG_OFFSET 150;
BA_ "GenSigCycleTime" SG_ 390 RL_CAN_TX_MUX_SNSR_ANGLE_OFFSET 50;
BA_ "GenSigTimeoutTime_SRR01RR" SG_ 390 RL_CAN_TX_MUX_SNSR_ANGLE_OFFSET 150;
BA_ "GenSigCycleTime" SG_ 390 RL_CAN_TX_MUX_KINK_ANGL_VER_MNR 50;
BA_ "GenSigTimeoutTime_SRR01RR" SG_ 390 RL_CAN_TX_MUX_KINK_ANGL_VER_MNR 150;
BA_ "GenSigCycleTime" SG_ 390 RL_CAN_TX_MUX_KINK_ANGL_VER_MJR 50;
BA_ "GenSigTimeoutTime_SRR01RR" SG_ 390 RL_CAN_TX_MUX_KINK_ANGL_VER_MJR 150;
BA_ "GenSigCycleTime" SG_ 390 RL_CAN_TX_MUX_ID 50;
BA_ "GenSigTimeoutTime_SRR01RR" SG_ 390 RL_CAN_TX_MUX_ID 150;
BA_ "GenSigCmt" SG_ 391 RL_CAN_NUMBER_OF_DET "Number of detections sent";
BA_ "GenSigCmt" SG_ 391 RL_CAN_SCAN_INDEX_FUSED "Scan index fused";
BA_ "GenSigCmt" SG_ 391 RL_CAN_LOOK_ID "Indicates the look type values 1 to 4 base on medium/long look and near/far look";
BA_ "GenSigCmt" SG_ 391 RL_CAN_LOOK_INDEX "Scan index for SODFL";
BA_ "GenSigCmt" SG_ 392 RL_CAN_RANGE_COVERAGE "CAN range coverage";
BA_ "GenSigCmt" SG_ 392 RL_CAN_DOPPLER_COVERAGE "CAN range coverage";
BA_ "GenSigStartValue" SG_ 392 RL_CAN_DOPPLER_COVERAGE 32768;
BA_ "GenSigCmt" SG_ 392 RL_CAN_FOV_HOR "CAN range coverage";
BA_ "GenSigCmt" SG_ 392 RL_CAN_FOV_VER "CAN range coverage";
BA_ "GenSigCmt" SG_ 393 RL_CAN_ACTIVE_FAULTS "Active faults";
BA_ "GenSigCmt" SG_ 394 RL_CAN_LATCH_FAULTS "Active Latch Faults";
BA_ "GenSigCycleTime" SG_ 448 RR_CAN_TX_VEH_SPEED_DIRECTION 50;
BA_ "GenSigTimeoutTime_SRR01RR" SG_ 448 RR_CAN_TX_VEH_SPEED_DIRECTION 150;
BA_ "GenSigCycleTime" SG_ 448 RR_CAN_TX_RADIUS_CURVATURE 50;
BA_ "GenSigTimeoutTime_SRR01RR" SG_ 448 RR_CAN_TX_RADIUS_CURVATURE 150;
BA_ "GenSigCycleTime" SG_ 448 RR_CAN_TX_STEERING_ANGLE_SIGN 50;
BA_ "GenSigTimeoutTime_SRR01RR" SG_ 448 RR_CAN_TX_STEERING_ANGLE_SIGN 150;
BA_ "GenSigCycleTime" SG_ 448 RR_CAN_TX_STEERING_ANGLE 50;
BA_ "GenSigTimeoutTime_SRR01RR" SG_ 448 RR_CAN_TX_STEERING_ANGLE 150;
BA_ "GenSigCycleTime" SG_ 448 RR_CAN_TX_YAW_RATE_CALC 50;
BA_ "GenSigTimeoutTime_SRR01RR" SG_ 448 RR_CAN_TX_YAW_RATE_CALC 150;
BA_ "GenSigCycleTime" SG_ 448 RR_CAN_TX_VEHICLE_SPEED_CALC 50;
BA_ "GenSigTimeoutTime_SRR01RR" SG_ 448 RR_CAN_TX_VEHICLE_SPEED_CALC 150;
BA_ "GenSigCycleTime" SG_ 448 RR_CAN_TX_SCAN_INDEX 50;
BA_ "GenSigTimeoutTime_SRR01RR" SG_ 448 RR_CAN_TX_SCAN_INDEX 150;
BA_ "GenSigCycleTime" SG_ 449 RR_CAN_TX_SW_VERSION_DSP 50;
BA_ "GenSigTimeoutTime_SRR01RR" SG_ 449 RR_CAN_TX_SW_VERSION_DSP 150;
BA_ "GenSigCycleTime" SG_ 449 RR_CAN_TX_PCAN_PROTOCOL_MINOR 50;
BA_ "GenSigTimeoutTime_SRR01RR" SG_ 449 RR_CAN_TX_PCAN_PROTOCOL_MINOR 150;
BA_ "GenSigCycleTime" SG_ 449 RR_CAN_TX_PCAN_PROTOCOL_MAJOR 50;
BA_ "GenSigTimeoutTime_SRR01RR" SG_ 449 RR_CAN_TX_PCAN_PROTOCOL_MAJOR 150;
BA_ "GenSigCycleTime" SG_ 449 RR_CAN_TX_SW_VERSION_ARM 50;
BA_ "GenSigTimeoutTime_SRR01RR" SG_ 449 RR_CAN_TX_SW_VERSION_ARM 150;
BA_ "GenSigCycleTime" SG_ 449 RR_CAN_TX_HW_VERSION 50;
BA_ "GenSigTimeoutTime_SRR01RR" SG_ 449 RR_CAN_TX_HW_VERSION 150;
BA_ "GenSigCycleTime" SG_ 450 RR_CAN_TX_SERIAL_NUMBER_SEQUENCE 50;
BA_ "GenSigTimeoutTime_SRR01RR" SG_ 450 RR_CAN_TX_SERIAL_NUMBER_SEQUENCE 150;
BA_ "GenSigCycleTime" SG_ 450 RR_CAN_TX_SERIAL_NUM_JULIAN_YEAR 50;
BA_ "GenSigTimeoutTime_SRR01RR" SG_ 450 RR_CAN_TX_SERIAL_NUM_JULIAN_YEAR 150;
BA_ "GenSigCycleTime" SG_ 450 RR_CAN_TX_SERIAL_NUM_JULIAN_DAY 50;
BA_ "GenSigTimeoutTime_SRR01RR" SG_ 450 RR_CAN_TX_SERIAL_NUM_JULIAN_DAY 150;
BA_ "GenSigCycleTime" SG_ 450 RR_CAN_TX_ARM_THROUGHPUT 50;
BA_ "GenSigTimeoutTime_SRR01RR" SG_ 450 RR_CAN_TX_ARM_THROUGHPUT 150;
BA_ "GenSigCycleTime" SG_ 450 RR_CAN_TX_SYSTEM_STATUS 50;
BA_ "GenSigTimeoutTime_SRR01RR" SG_ 450 RR_CAN_TX_SYSTEM_STATUS 150;
BA_ "GenSigCycleTime" SG_ 450 RR_CAN_TX_LOOK_TYPE_1 50;
BA_ "GenSigTimeoutTime_SRR01RR" SG_ 450 RR_CAN_TX_LOOK_TYPE_1 150;
BA_ "GenSigCycleTime" SG_ 450 RR_CAN_TX_OVERHEAT_ERROR 50;
BA_ "GenSigTimeoutTime_SRR01RR" SG_ 450 RR_CAN_TX_OVERHEAT_ERROR 150;
BA_ "GenSigCycleTime" SG_ 450 RR_CAN_TX_RANGE_PERF_ERROR 50;
BA_ "GenSigTimeoutTime_SRR01RR" SG_ 450 RR_CAN_TX_RANGE_PERF_ERROR 150;
BA_ "GenSigCycleTime" SG_ 450 RR_CAN_TX_COMM_ERROR 50;
BA_ "GenSigTimeoutTime_SRR01RR" SG_ 450 RR_CAN_TX_COMM_ERROR 150;
BA_ "GenSigCycleTime" SG_ 450 RR_CAN_TX_INTERNAL_ERROR 50;
BA_ "GenSigTimeoutTime_SRR01RR" SG_ 450 RR_CAN_TX_INTERNAL_ERROR 150;
BA_ "GenSigCycleTime" SG_ 450 RR_CAN_TX_XCVR_OPERATIONAL 50;
BA_ "GenSigTimeoutTime_SRR01RR" SG_ 450 RR_CAN_TX_XCVR_OPERATIONAL 150;
BA_ "GenSigCycleTime" SG_ 451 RR_CAN_TX_DRIVING_ENVIRONMENT 50;
BA_ "GenSigTimeoutTime_SRR01RR" SG_ 451 RR_CAN_TX_DRIVING_ENVIRONMENT 150;
BA_ "GenSigCycleTime" SG_ 451 RR_CAN_TX_ROLLING_COUNT_1 50;
BA_ "GenSigTimeoutTime_SRR01RR" SG_ 451 RR_CAN_TX_ROLLING_COUNT_1 150;
BA_ "GenSigCycleTime" SG_ 451 RR_CAN_TX_Temperature 50;
BA_ "GenSigTimeoutTime_SRR01RR" SG_ 451 RR_CAN_TX_Temperature 150;
BA_ "GenSigCycleTime" SG_ 451 RR_CAN_TX_YAW_RATE_BIAS 50;
BA_ "GenSigTimeoutTime_SRR01RR" SG_ 451 RR_CAN_TX_YAW_RATE_BIAS 150;
BA_ "GenSigCycleTime" SG_ 451 RR_CAN_TX_VEH_SPD_COMP_FACTOR 50;
BA_ "GenSigTimeoutTime_SRR01RR" SG_ 451 RR_CAN_TX_VEH_SPD_COMP_FACTOR 150;
BA_ "GenSigCycleTime" SG_ 451 RR_CAN_TX_AUTO_ALIGN_QUA_FACTOR 50;
BA_ "GenSigTimeoutTime_SRR01RR" SG_ 451 RR_CAN_TX_AUTO_ALIGN_QUA_FACTOR 150;
BA_ "GenSigCycleTime" SG_ 451 RR_CAN_TX_Alignment_MODE 50;
BA_ "GenSigTimeoutTime_SRR01RR" SG_ 451 RR_CAN_TX_Alignment_MODE 150;
BA_ "GenSigCycleTime" SG_ 451 RR_CAN_TX_CURRENT_MISALIGN_ANGLE 50;
BA_ "GenSigTimeoutTime_SRR01RR" SG_ 451 RR_CAN_TX_CURRENT_MISALIGN_ANGLE 150;
BA_ "GenSigCycleTime" SG_ 451 RR_CAN_TX_SAVED_MISALIGN_ANGLE 50;
BA_ "GenSigTimeoutTime_SRR01RR" SG_ 451 RR_CAN_TX_SAVED_MISALIGN_ANGLE 150;
BA_ "GenSigCycleTime" SG_ 452 RR_Supply_2_3v_Out_Of_Range_Flt 50;
BA_ "GenSigTimeoutTime_SRR01RR" SG_ 452 RR_Supply_2_3v_Out_Of_Range_Flt 150;
BA_ "GenSigCycleTime" SG_ 452 RR_Supply_1_25v_Out_Of_Range_Flt 50;
BA_ "GenSigTimeoutTime_SRR01RR" SG_ 452 RR_Supply_1_25v_Out_Of_Range_Flt 150;
BA_ "GenSigCycleTime" SG_ 452 RR_Software_Incompatible_Flt 50;
BA_ "GenSigTimeoutTime_SRR01RR" SG_ 452 RR_Software_Incompatible_Flt 150;
BA_ "GenSigCycleTime" SG_ 452 RR_Host_Spi_Checksum_Flt 50;
BA_ "GenSigTimeoutTime_SRR01RR" SG_ 452 RR_Host_Spi_Checksum_Flt 150;
BA_ "GenSigCycleTime" SG_ 452 RR_Loss_Of_Comm_With_Dsp_Flt 50;
BA_ "GenSigTimeoutTime_SRR01RR" SG_ 452 RR_Loss_Of_Comm_With_Dsp_Flt 150;
BA_ "GenSigCycleTime" SG_ 452 RR_No_Communication_With_Arm_Flt 50;
BA_ "GenSigTimeoutTime_SRR01RR" SG_ 452 RR_No_Communication_With_Arm_Flt 150;
BA_ "GenSigCycleTime" SG_ 452 RR_Communication_With_Host_Flt 50;
BA_ "GenSigTimeoutTime_SRR01RR" SG_ 452 RR_Communication_With_Host_Flt 150;
BA_ "GenSigCycleTime" SG_ 452 RR_Communication_With_Arm_Flt 50;
BA_ "GenSigTimeoutTime_SRR01RR" SG_ 452 RR_Communication_With_Arm_Flt 150;
BA_ "GenSigCycleTime" SG_ 452 RR_Dsp_Loop_Overrun_Flt_Dsp 50;
BA_ "GenSigTimeoutTime_SRR01RR" SG_ 452 RR_Dsp_Loop_Overrun_Flt_Dsp 150;
BA_ "GenSigCycleTime" SG_ 452 RR_Tuning_Sensitivity_Flt 50;
BA_ "GenSigTimeoutTime_SRR01RR" SG_ 452 RR_Tuning_Sensitivity_Flt 150;
BA_ "GenSigCycleTime" SG_ 452 RR_Saturated_Tuning_Freq_Flt 50;
BA_ "GenSigTimeoutTime_SRR01RR" SG_ 452 RR_Saturated_Tuning_Freq_Flt 150;
BA_ "GenSigCycleTime" SG_ 452 RR_Local_Oscillator_Power_Flt 50;
BA_ "GenSigTimeoutTime_SRR01RR" SG_ 452 RR_Local_Oscillator_Power_Flt 150;
BA_ "GenSigCycleTime" SG_ 452 RR_Transmitter_Power_Flt 50;
BA_ "GenSigTimeoutTime_SRR01RR" SG_ 452 RR_Transmitter_Power_Flt 150;
BA_ "GenSigCycleTime" SG_ 452 RR_Radar_Data_Sync_Flt 50;
BA_ "GenSigTimeoutTime_SRR01RR" SG_ 452 RR_Radar_Data_Sync_Flt 150;
BA_ "GenSigCycleTime" SG_ 452 RR_Dsp_Spi_Hardware_Flt 50;
BA_ "GenSigTimeoutTime_SRR01RR" SG_ 452 RR_Dsp_Spi_Hardware_Flt 150;
BA_ "GenSigCycleTime" SG_ 452 RR_Transmitter_Device_Spi_Flt 50;
BA_ "GenSigTimeoutTime_SRR01RR" SG_ 452 RR_Transmitter_Device_Spi_Flt 150;
BA_ "GenSigCycleTime" SG_ 452 RR_Receiver_Device_Spi_Flt 50;
BA_ "GenSigTimeoutTime_SRR01RR" SG_ 452 RR_Receiver_Device_Spi_Flt 150;
BA_ "GenSigCycleTime" SG_ 452 RR_Freq_Synthe_Device_Spi_Flt 50;
BA_ "GenSigTimeoutTime_SRR01RR" SG_ 452 RR_Freq_Synthe_Device_Spi_Flt 150;
BA_ "GenSigCycleTime" SG_ 452 RR_Analog_Cnvrtr_Device_Spi_Flt 50;
BA_ "GenSigTimeoutTime_SRR01RR" SG_ 452 RR_Analog_Cnvrtr_Device_Spi_Flt 150;
BA_ "GenSigCycleTime" SG_ 452 RR_Transmitter_Id_Flt 50;
BA_ "GenSigTimeoutTime_SRR01RR" SG_ 452 RR_Transmitter_Id_Flt 150;
BA_ "GenSigCycleTime" SG_ 452 RR_Ecu_Temperature_High_Flt 50;
BA_ "GenSigTimeoutTime_SRR01RR" SG_ 452 RR_Ecu_Temperature_High_Flt 150;
BA_ "GenSigCycleTime" SG_ 452 RR_Transmitter_Temp_High_Flt 50;
BA_ "GenSigTimeoutTime_SRR01RR" SG_ 452 RR_Transmitter_Temp_High_Flt 150;
BA_ "GenSigCycleTime" SG_ 452 RR_Alignment_Routine_Failed_Flt 50;
BA_ "GenSigTimeoutTime_SRR01RR" SG_ 452 RR_Alignment_Routine_Failed_Flt 150;
BA_ "GenSigCycleTime" SG_ 452 RR_Unreasonable_Radar_Data 50;
BA_ "GenSigTimeoutTime_SRR01RR" SG_ 452 RR_Unreasonable_Radar_Data 150;
BA_ "GenSigCycleTime" SG_ 452 RR_Sensor_Blocked_Flt 50;
BA_ "GenSigTimeoutTime_SRR01RR" SG_ 452 RR_Sensor_Blocked_Flt 150;
BA_ "GenSigCycleTime" SG_ 452 RR_Vertical_Alignt_Out_Of_Range 50;
BA_ "GenSigTimeoutTime_SRR01RR" SG_ 452 RR_Vertical_Alignt_Out_Of_Range 150;
BA_ "GenSigCycleTime" SG_ 452 RR_Horizontal_Align_Out_Of_Range 50;
BA_ "GenSigTimeoutTime_SRR01RR" SG_ 452 RR_Horizontal_Align_Out_Of_Range 150;
BA_ "GenSigCycleTime" SG_ 452 RR_Factory_Alignment_Mode 50;
BA_ "GenSigTimeoutTime_SRR01RR" SG_ 452 RR_Factory_Alignment_Mode 150;
BA_ "GenSigCycleTime" SG_ 452 RR_Battery_Low_Flt 50;
BA_ "GenSigTimeoutTime_SRR01RR" SG_ 452 RR_Battery_Low_Flt 150;
BA_ "GenSigCycleTime" SG_ 452 RR_Battery_High_Flt 50;
BA_ "GenSigTimeoutTime_SRR01RR" SG_ 452 RR_Battery_High_Flt 150;
BA_ "GenSigCycleTime" SG_ 452 RR_Ecu_Position_Config_Flt 50;
BA_ "GenSigTimeoutTime_SRR01RR" SG_ 452 RR_Ecu_Position_Config_Flt 150;
BA_ "GenSigCycleTime" SG_ 452 RR_Supply_1_1v_Out_Of_Range_Flt 50;
BA_ "GenSigTimeoutTime_SRR01RR" SG_ 452 RR_Supply_1_1v_Out_Of_Range_Flt 150;
BA_ "GenSigCycleTime" SG_ 452 RR_Supply_1_8v_Out_Of_Range_Flt 50;
BA_ "GenSigTimeoutTime_SRR01RR" SG_ 452 RR_Supply_1_8v_Out_Of_Range_Flt 150;
BA_ "GenSigCycleTime" SG_ 452 RR_Thermistor_Out_Of_Range_Flt 50;
BA_ "GenSigTimeoutTime_SRR01RR" SG_ 452 RR_Thermistor_Out_Of_Range_Flt 150;
BA_ "GenSigCycleTime" SG_ 452 RR_Supply_5v_Out_Of_Range_Flt 50;
BA_ "GenSigTimeoutTime_SRR01RR" SG_ 452 RR_Supply_5v_Out_Of_Range_Flt 150;
BA_ "GenSigCycleTime" SG_ 452 RR_Pcan_Init_Missing_Message_Flt 50;
BA_ "GenSigTimeoutTime_SRR01RR" SG_ 452 RR_Pcan_Init_Missing_Message_Flt 150;
BA_ "GenSigCycleTime" SG_ 452 RR_Pcan_Trk_Data_Unreasnble_Flt 50;
BA_ "GenSigTimeoutTime_SRR01RR" SG_ 452 RR_Pcan_Trk_Data_Unreasnble_Flt 150;
BA_ "GenSigCycleTime" SG_ 452 RR_Pcan_Data_Range_Check_Flt 50;
BA_ "GenSigTimeoutTime_SRR01RR" SG_ 452 RR_Pcan_Data_Range_Check_Flt 150;
BA_ "GenSigCycleTime" SG_ 452 RR_Pcan_Missing_Message_Flt 50;
BA_ "GenSigTimeoutTime_SRR01RR" SG_ 452 RR_Pcan_Missing_Message_Flt 150;
BA_ "GenSigCycleTime" SG_ 452 RR_Pcan_Hw_Rx_Buffer_Flt 50;
BA_ "GenSigTimeoutTime_SRR01RR" SG_ 452 RR_Pcan_Hw_Rx_Buffer_Flt 150;
BA_ "GenSigCycleTime" SG_ 452 RR_Pcan_Sw_Buffer_Flt 50;
BA_ "GenSigTimeoutTime_SRR01RR" SG_ 452 RR_Pcan_Sw_Buffer_Flt 150;
BA_ "GenSigCycleTime" SG_ 452 RR_Pcan_Bus_Off 50;
BA_ "GenSigTimeoutTime_SRR01RR" SG_ 452 RR_Pcan_Bus_Off 150;
BA_ "GenSigCycleTime" SG_ 452 RR_Host_Instrctn_Set_Check_Flt 50;
BA_ "GenSigTimeoutTime_SRR01RR" SG_ 452 RR_Host_Instrctn_Set_Check_Flt 150;
BA_ "GenSigCycleTime" SG_ 452 RR_Host_Stack_Overflow_Flt 50;
BA_ "GenSigTimeoutTime_SRR01RR" SG_ 452 RR_Host_Stack_Overflow_Flt 150;
BA_ "GenSigCycleTime" SG_ 452 RR_Sensor_Watchdog_Flt 50;
BA_ "GenSigTimeoutTime_SRR01RR" SG_ 452 RR_Sensor_Watchdog_Flt 150;
BA_ "GenSigCycleTime" SG_ 452 RR_Sensor_Pll_Lock_Flt 50;
BA_ "GenSigTimeoutTime_SRR01RR" SG_ 452 RR_Sensor_Pll_Lock_Flt 150;
BA_ "GenSigCycleTime" SG_ 452 RR_Host_Pll_Lock_Flt 50;
BA_ "GenSigTimeoutTime_SRR01RR" SG_ 452 RR_Host_Pll_Lock_Flt 150;
BA_ "GenSigCycleTime" SG_ 452 RR_Sensor_Ram_Memory_Test_Flt 50;
BA_ "GenSigTimeoutTime_SRR01RR" SG_ 452 RR_Sensor_Ram_Memory_Test_Flt 150;
BA_ "GenSigCycleTime" SG_ 452 RR_Host_Ram_Memory_Test_Flt 50;
BA_ "GenSigTimeoutTime_SRR01RR" SG_ 452 RR_Host_Ram_Memory_Test_Flt 150;
BA_ "GenSigCycleTime" SG_ 452 RR_Snsr_Custmr_Cal_Flsh_Chksum 50;
BA_ "GenSigTimeoutTime_SRR01RR" SG_ 452 RR_Snsr_Custmr_Cal_Flsh_Chksum 150;
BA_ "GenSigCycleTime" SG_ 452 RR_Dsp_Usc_Validation_Flt 50;
BA_ "GenSigTimeoutTime_SRR01RR" SG_ 452 RR_Dsp_Usc_Validation_Flt 150;
BA_ "GenSigCycleTime" SG_ 452 RR_Sensor_App_Flash_Checksum_Flt 50;
BA_ "GenSigTimeoutTime_SRR01RR" SG_ 452 RR_Sensor_App_Flash_Checksum_Flt 150;
BA_ "GenSigCycleTime" SG_ 452 RR_Host_Kp_Alv_Flsh_Chcksm_Flt 50;
BA_ "GenSigTimeoutTime_SRR01RR" SG_ 452 RR_Host_Kp_Alv_Flsh_Chcksm_Flt 150;
BA_ "GenSigCycleTime" SG_ 452 RR_Host_Pgm_Cal_Flsh_Chcksum_Flt 50;
BA_ "GenSigTimeoutTime_SRR01RR" SG_ 452 RR_Host_Pgm_Cal_Flsh_Chcksum_Flt 150;
BA_ "GenSigCycleTime" SG_ 452 RR_Host_App_Flash_Checksum_Flt 50;
BA_ "GenSigTimeoutTime_SRR01RR" SG_ 452 RR_Host_App_Flash_Checksum_Flt 150;
BA_ "GenSigCycleTime" SG_ 453 RR_USC_Load_Error 50;
BA_ "GenSigTimeoutTime_SRR01RR" SG_ 453 RR_USC_Load_Error 150;
BA_ "GenSigCycleTime" SG_ 453 RR_SMC_Load_Error 50;
BA_ "GenSigTimeoutTime_SRR01RR" SG_ 453 RR_SMC_Load_Error 150;
BA_ "GenSigCycleTime" SG_ 453 RR_TX_Temperature_Flt 50;
BA_ "GenSigTimeoutTime_SRR01RR" SG_ 453 RR_TX_Temperature_Flt 150;
BA_ "GenSigCycleTime" SG_ 453 RR_Dsp_Unit_Cal_Blk_Chcksm_Error 50;
BA_ "GenSigTimeoutTime_SRR01RR" SG_ 453 RR_Dsp_Unit_Cal_Blk_Chcksm_Error 150;
BA_ "GenSigCycleTime" SG_ 453 RR_Dsp_Unit_Cal_Checksum_Error 50;
BA_ "GenSigTimeoutTime_SRR01RR" SG_ 453 RR_Dsp_Unit_Cal_Checksum_Error 150;
BA_ "GenSigCycleTime" SG_ 453 RR_Vertical_Misalignment_error 50;
BA_ "GenSigTimeoutTime_SRR01RR" SG_ 453 RR_Vertical_Misalignment_error 150;
BA_ "GenSigCycleTime" SG_ 453 RR_RTN_SPI_Transfer_Error 50;
BA_ "GenSigTimeoutTime_SRR01RR" SG_ 453 RR_RTN_SPI_Transfer_Error 150;
BA_ "GenSigCycleTime" SG_ 453 RR_RRN_SPI_Transfer_Error 50;
BA_ "GenSigTimeoutTime_SRR01RR" SG_ 453 RR_RRN_SPI_Transfer_Error 150;
BA_ "GenSigCycleTime" SG_ 453 RR_Linearizer_SPI_Transfer_Error 50;
BA_ "GenSigTimeoutTime_SRR01RR" SG_ 453 RR_Linearizer_SPI_Transfer_Error 150;
BA_ "GenSigCycleTime" SG_ 453 RR_ADC_SPI_Transfer_Error 50;
BA_ "GenSigTimeoutTime_SRR01RR" SG_ 453 RR_ADC_SPI_Transfer_Error 150;
BA_ "GenSigCycleTime" SG_ 453 RR_Transmitter_ID_Error 50;
BA_ "GenSigTimeoutTime_SRR01RR" SG_ 453 RR_Transmitter_ID_Error 150;
BA_ "GenSigCycleTime" SG_ 453 RR_Dsp_Loop_Overrun_Error 50;
BA_ "GenSigTimeoutTime_SRR01RR" SG_ 453 RR_Dsp_Loop_Overrun_Error 150;
BA_ "GenSigCycleTime" SG_ 453 RR_Saturated_Tuning_Freq_Error 50;
BA_ "GenSigTimeoutTime_SRR01RR" SG_ 453 RR_Saturated_Tuning_Freq_Error 150;
BA_ "GenSigCycleTime" SG_ 453 RR_Radar_Data_sync_error 50;
BA_ "GenSigTimeoutTime_SRR01RR" SG_ 453 RR_Radar_Data_sync_error 150;
BA_ "GenSigCycleTime" SG_ 453 RR_Dsp_Tuning_Sensitivity_Error 50;
BA_ "GenSigTimeoutTime_SRR01RR" SG_ 453 RR_Dsp_Tuning_Sensitivity_Error 150;
BA_ "GenSigCycleTime" SG_ 453 RR_Radar_LO_Power_Error 50;
BA_ "GenSigTimeoutTime_SRR01RR" SG_ 453 RR_Radar_LO_Power_Error 150;
BA_ "GenSigCycleTime" SG_ 453 RR_Radar_TX_Power_Error 50;
BA_ "GenSigTimeoutTime_SRR01RR" SG_ 453 RR_Radar_TX_Power_Error 150;
BA_ "GenSigCycleTime" SG_ 453 RR_Timer_Create_Error 50;
BA_ "GenSigTimeoutTime_SRR01RR" SG_ 453 RR_Timer_Create_Error 150;
BA_ "GenSigCycleTime" SG_ 453 RR_Thread_Create_Error 50;
BA_ "GenSigTimeoutTime_SRR01RR" SG_ 453 RR_Thread_Create_Error 150;
BA_ "GenSigCycleTime" SG_ 453 RR_ARM_Calibration_Error 50;
BA_ "GenSigTimeoutTime_SRR01RR" SG_ 453 RR_ARM_Calibration_Error 150;
BA_ "GenSigCycleTime" SG_ 453 RR_SPI_FEE_Error 50;
BA_ "GenSigTimeoutTime_SRR01RR" SG_ 453 RR_SPI_FEE_Error 150;
BA_ "GenSigCycleTime" SG_ 453 RR_SPI_Comm_Error 50;
BA_ "GenSigTimeoutTime_SRR01RR" SG_ 453 RR_SPI_Comm_Error 150;
BA_ "GenSigCycleTime" SG_ 453 RR_Socket_Write_Error 50;
BA_ "GenSigTimeoutTime_SRR01RR" SG_ 453 RR_Socket_Write_Error 150;
BA_ "GenSigCycleTime" SG_ 453 RR_Socket_Read_error 50;
BA_ "GenSigTimeoutTime_SRR01RR" SG_ 453 RR_Socket_Read_error 150;
BA_ "GenSigCycleTime" SG_ 453 RR_Socket_Init_Error 50;
BA_ "GenSigTimeoutTime_SRR01RR" SG_ 453 RR_Socket_Init_Error 150;
BA_ "GenSigCycleTime" SG_ 453 RR_Signal_Wait_Error 50;
BA_ "GenSigTimeoutTime_SRR01RR" SG_ 453 RR_Signal_Wait_Error 150;
BA_ "GenSigCycleTime" SG_ 453 RR_Signal_Send_Error 50;
BA_ "GenSigTimeoutTime_SRR01RR" SG_ 453 RR_Signal_Send_Error 150;
BA_ "GenSigCycleTime" SG_ 453 RR_Signal_Create_Error 50;
BA_ "GenSigTimeoutTime_SRR01RR" SG_ 453 RR_Signal_Create_Error 150;
BA_ "GenSigCycleTime" SG_ 453 RR_Shared_Mem_Write_Error 50;
BA_ "GenSigTimeoutTime_SRR01RR" SG_ 453 RR_Shared_Mem_Write_Error 150;
BA_ "GenSigCycleTime" SG_ 453 RR_Shared_Mem_Read_Error 50;
BA_ "GenSigTimeoutTime_SRR01RR" SG_ 453 RR_Shared_Mem_Read_Error 150;
BA_ "GenSigCycleTime" SG_ 453 RR_Shared_Mem_Config_Error 50;
BA_ "GenSigTimeoutTime_SRR01RR" SG_ 453 RR_Shared_Mem_Config_Error 150;
BA_ "GenSigCycleTime" SG_ 453 RR_Share_Mem_Init_Error 50;
BA_ "GenSigTimeoutTime_SRR01RR" SG_ 453 RR_Share_Mem_Init_Error 150;
BA_ "GenSigCycleTime" SG_ 453 RR_RAM_Test_Error 50;
BA_ "GenSigTimeoutTime_SRR01RR" SG_ 453 RR_RAM_Test_Error 150;
BA_ "GenSigCycleTime" SG_ 453 RR_Num_Errors 50;
BA_ "GenSigTimeoutTime_SRR01RR" SG_ 453 RR_Num_Errors 150;
BA_ "GenSigCycleTime" SG_ 453 RR_MMAP_Memory_Error 50;
BA_ "GenSigTimeoutTime_SRR01RR" SG_ 453 RR_MMAP_Memory_Error 150;
BA_ "GenSigCycleTime" SG_ 453 RR_ISR_Attach_Error 50;
BA_ "GenSigTimeoutTime_SRR01RR" SG_ 453 RR_ISR_Attach_Error 150;
BA_ "GenSigCycleTime" SG_ 453 RR_IPC_DRV_Write_Error 50;
BA_ "GenSigTimeoutTime_SRR01RR" SG_ 453 RR_IPC_DRV_Write_Error 150;
BA_ "GenSigCycleTime" SG_ 453 RR_IPC_DRV_Trigger_Error 50;
BA_ "GenSigTimeoutTime_SRR01RR" SG_ 453 RR_IPC_DRV_Trigger_Error 150;
BA_ "GenSigCycleTime" SG_ 453 RR_IPC_DRV_Sync_Error 50;
BA_ "GenSigTimeoutTime_SRR01RR" SG_ 453 RR_IPC_DRV_Sync_Error 150;
BA_ "GenSigCycleTime" SG_ 453 RR_IPC_DRV_Read_Error 50;
BA_ "GenSigTimeoutTime_SRR01RR" SG_ 453 RR_IPC_DRV_Read_Error 150;
BA_ "GenSigCycleTime" SG_ 453 RR_IPC_DRV_Init_Error 50;
BA_ "GenSigTimeoutTime_SRR01RR" SG_ 453 RR_IPC_DRV_Init_Error 150;
BA_ "GenSigCycleTime" SG_ 453 RR_Interrupt_Enable_Error 50;
BA_ "GenSigTimeoutTime_SRR01RR" SG_ 453 RR_Interrupt_Enable_Error 150;
BA_ "GenSigCycleTime" SG_ 453 RR_HIL_Format_Error 50;
BA_ "GenSigTimeoutTime_SRR01RR" SG_ 453 RR_HIL_Format_Error 150;
BA_ "GenSigCycleTime" SG_ 453 RR_Flash_Filesystem_Error 50;
BA_ "GenSigTimeoutTime_SRR01RR" SG_ 453 RR_Flash_Filesystem_Error 150;
BA_ "GenSigCycleTime" SG_ 453 RR_Error_none 50;
BA_ "GenSigTimeoutTime_SRR01RR" SG_ 453 RR_Error_none 150;
BA_ "GenSigCycleTime" SG_ 453 RR_Dsp_Load_Read_Error 50;
BA_ "GenSigTimeoutTime_SRR01RR" SG_ 453 RR_Dsp_Load_Read_Error 150;
BA_ "GenSigCycleTime" SG_ 453 RR_Dsp_Load_Open_Error 50;
BA_ "GenSigTimeoutTime_SRR01RR" SG_ 453 RR_Dsp_Load_Open_Error 150;
BA_ "GenSigCycleTime" SG_ 453 RR_Dsp_Load_Address_Error 50;
BA_ "GenSigTimeoutTime_SRR01RR" SG_ 453 RR_Dsp_Load_Address_Error 150;
BA_ "GenSigCycleTime" SG_ 453 RR_Dsp_ISP_Write_Error 50;
BA_ "GenSigTimeoutTime_SRR01RR" SG_ 453 RR_Dsp_ISP_Write_Error 150;
BA_ "GenSigCycleTime" SG_ 453 RR_Dsp_IPC_Read_Error 50;
BA_ "GenSigTimeoutTime_SRR01RR" SG_ 453 RR_Dsp_IPC_Read_Error 150;
BA_ "GenSigCycleTime" SG_ 453 RR_Dsp_IPC_Init 50;
BA_ "GenSigTimeoutTime_SRR01RR" SG_ 453 RR_Dsp_IPC_Init 150;
BA_ "GenSigCycleTime" SG_ 453 RR_Dsp_Init_Error 50;
BA_ "GenSigTimeoutTime_SRR01RR" SG_ 453 RR_Dsp_Init_Error 150;
BA_ "GenSigCycleTime" SG_ 453 RR_Dsp_DRV_Start_Error 50;
BA_ "GenSigTimeoutTime_SRR01RR" SG_ 453 RR_Dsp_DRV_Start_Error 150;
BA_ "GenSigCycleTime" SG_ 453 RR_Dsp_DRV_Load_Error 50;
BA_ "GenSigTimeoutTime_SRR01RR" SG_ 453 RR_Dsp_DRV_Load_Error 150;
BA_ "GenSigCycleTime" SG_ 453 RR_Dsp_DRV_Init_Error 50;
BA_ "GenSigTimeoutTime_SRR01RR" SG_ 453 RR_Dsp_DRV_Init_Error 150;
BA_ "GenSigCycleTime" SG_ 453 RR_Dsp_DRV_Init2_error 50;
BA_ "GenSigTimeoutTime_SRR01RR" SG_ 453 RR_Dsp_DRV_Init2_error 150;
BA_ "GenSigCycleTime" SG_ 453 RR_Dsp_DRV_Init1_error 50;
BA_ "GenSigTimeoutTime_SRR01RR" SG_ 453 RR_Dsp_DRV_Init1_error 150;
BA_ "GenSigCycleTime" SG_ 453 RR_CAN_XMT_Error 50;
BA_ "GenSigTimeoutTime_SRR01RR" SG_ 453 RR_CAN_XMT_Error 150;
BA_ "GenSigCycleTime" SG_ 453 RR_CAN_RCV_Error 50;
BA_ "GenSigTimeoutTime_SRR01RR" SG_ 453 RR_CAN_RCV_Error 150;
BA_ "GenSigCycleTime" SG_ 453 RR_CAN_Hardware_Error 50;
BA_ "GenSigTimeoutTime_SRR01RR" SG_ 453 RR_CAN_Hardware_Error 150;
BA_ "GenSigCycleTime" SG_ 453 RR_Always_True 50;
BA_ "GenSigTimeoutTime_SRR01RR" SG_ 453 RR_Always_True 150;
BA_ "GenSigCycleTime" SG_ 454 RR_CAN_TX_MUX_SVK_CAL_DATA_5 50;
BA_ "GenSigTimeoutTime_SRR01RR" SG_ 454 RR_CAN_TX_MUX_SVK_CAL_DATA_5 150;
BA_ "GenSigCycleTime" SG_ 454 RR_CAN_TX_MUX_SVK_CAL_DATA_4 50;
BA_ "GenSigTimeoutTime_SRR01RR" SG_ 454 RR_CAN_TX_MUX_SVK_CAL_DATA_4 150;
BA_ "GenSigCycleTime" SG_ 454 RR_CAN_TX_MUX_SVK_CAL_DATA_3 50;
BA_ "GenSigTimeoutTime_SRR01RR" SG_ 454 RR_CAN_TX_MUX_SVK_CAL_DATA_3 150;
BA_ "GenSigCycleTime" SG_ 454 RR_CAN_TX_MUX_SVK_CAL_DATA_2 50;
BA_ "GenSigTimeoutTime_SRR01RR" SG_ 454 RR_CAN_TX_MUX_SVK_CAL_DATA_2 150;
BA_ "GenSigCycleTime" SG_ 454 RR_CAN_TX_MUX_SVK_CAL_DATA_1 50;
BA_ "GenSigTimeoutTime_SRR01RR" SG_ 454 RR_CAN_TX_MUX_SVK_CAL_DATA_1 150;
BA_ "GenSigCycleTime" SG_ 454 RR_CAN_TX_MUX_SVK_CAL_DATA_0 50;
BA_ "GenSigTimeoutTime_SRR01RR" SG_ 454 RR_CAN_TX_MUX_SVK_CAL_DATA_0 150;
BA_ "GenSigCycleTime" SG_ 454 RR_CAN_TX_MUX_SVK_CAL_MSG_CNT 50;
BA_ "GenSigTimeoutTime_SRR01RR" SG_ 454 RR_CAN_TX_MUX_SVK_CAL_MSG_CNT 150;
BA_ "GenSigCycleTime" SG_ 454 RR_CAN_TX_MUX_RCWM_CAL_MSG_CNT 50;
BA_ "GenSigTimeoutTime_SRR01RR" SG_ 454 RR_CAN_TX_MUX_RCWM_CAL_MSG_CNT 150;
BA_ "GenSigCycleTime" SG_ 454 RR_CAN_TX_MUX_RCWM_CAL_DATA_0 50;
BA_ "GenSigTimeoutTime_SRR01RR" SG_ 454 RR_CAN_TX_MUX_RCWM_CAL_DATA_0 150;
BA_ "GenSigCycleTime" SG_ 454 RR_CAN_TX_MUX_RCWM_CAL_DATA_1 50;
BA_ "GenSigTimeoutTime_SRR01RR" SG_ 454 RR_CAN_TX_MUX_RCWM_CAL_DATA_1 150;
BA_ "GenSigCycleTime" SG_ 454 RR_CAN_TX_MUX_RCWM_CAL_DATA_2 50;
BA_ "GenSigTimeoutTime_SRR01RR" SG_ 454 RR_CAN_TX_MUX_RCWM_CAL_DATA_2 150;
BA_ "GenSigCycleTime" SG_ 454 RR_CAN_TX_MUX_RCWM_CAL_DATA_3 50;
BA_ "GenSigTimeoutTime_SRR01RR" SG_ 454 RR_CAN_TX_MUX_RCWM_CAL_DATA_3 150;
BA_ "GenSigCycleTime" SG_ 454 RR_CAN_TX_MUX_RCWM_CAL_DATA_4 50;
BA_ "GenSigTimeoutTime_SRR01RR" SG_ 454 RR_CAN_TX_MUX_RCWM_CAL_DATA_4 150;
BA_ "GenSigCycleTime" SG_ 454 RR_CAN_TX_MUX_RCWM_CAL_DATA_5 50;
BA_ "GenSigTimeoutTime_SRR01RR" SG_ 454 RR_CAN_TX_MUX_RCWM_CAL_DATA_5 150;
BA_ "GenSigCycleTime" SG_ 454 RR_CAN_TX_MUX_RECW_CAL_MSG_CNT 50;
BA_ "GenSigTimeoutTime_SRR01RR" SG_ 454 RR_CAN_TX_MUX_RECW_CAL_MSG_CNT 150;
BA_ "GenSigCycleTime" SG_ 454 RR_CAN_TX_MUX_RECW_CAL_DATA_0 50;
BA_ "GenSigTimeoutTime_SRR01RR" SG_ 454 RR_CAN_TX_MUX_RECW_CAL_DATA_0 150;
BA_ "GenSigCycleTime" SG_ 454 RR_CAN_TX_MUX_RECW_CAL_DATA_1 50;
BA_ "GenSigTimeoutTime_SRR01RR" SG_ 454 RR_CAN_TX_MUX_RECW_CAL_DATA_1 150;
BA_ "GenSigCycleTime" SG_ 454 RR_CAN_TX_MUX_RECW_CAL_DATA_2 50;
BA_ "GenSigTimeoutTime_SRR01RR" SG_ 454 RR_CAN_TX_MUX_RECW_CAL_DATA_2 150;
BA_ "GenSigCycleTime" SG_ 454 RR_CAN_TX_MUX_RECW_CAL_DATA_3 50;
BA_ "GenSigTimeoutTime_SRR01RR" SG_ 454 RR_CAN_TX_MUX_RECW_CAL_DATA_3 150;
BA_ "GenSigCycleTime" SG_ 454 RR_CAN_TX_MUX_RECW_CAL_DATA_4 50;
BA_ "GenSigTimeoutTime_SRR01RR" SG_ 454 RR_CAN_TX_MUX_RECW_CAL_DATA_4 150;
BA_ "GenSigCycleTime" SG_ 454 RR_CAN_TX_MUX_RECW_CAL_DATA_5 50;
BA_ "GenSigTimeoutTime_SRR01RR" SG_ 454 RR_CAN_TX_MUX_RECW_CAL_DATA_5 150;
BA_ "GenSigCycleTime" SG_ 454 RR_CAN_TX_MUX_FRESPCE_CALMSG_CNT 50;
BA_ "GenSigTimeoutTime_SRR01RR" SG_ 454 RR_CAN_TX_MUX_FRESPCE_CALMSG_CNT 150;
BA_ "GenSigCycleTime" SG_ 454 RR_CAN_TX_MUX_FRESPCE_CAL_DATA_0 50;
BA_ "GenSigTimeoutTime_SRR01RR" SG_ 454 RR_CAN_TX_MUX_FRESPCE_CAL_DATA_0 150;
BA_ "GenSigCycleTime" SG_ 454 RR_CAN_TX_MUX_FRESPCE_CAL_DATA_1 50;
BA_ "GenSigTimeoutTime_SRR01RR" SG_ 454 RR_CAN_TX_MUX_FRESPCE_CAL_DATA_1 150;
BA_ "GenSigCycleTime" SG_ 454 RR_CAN_TX_MUX_FRESPCE_CAL_DATA_2 50;
BA_ "GenSigTimeoutTime_SRR01RR" SG_ 454 RR_CAN_TX_MUX_FRESPCE_CAL_DATA_2 150;
BA_ "GenSigCycleTime" SG_ 454 RR_CAN_TX_MUX_FRESPCE_CAL_DATA_3 50;
BA_ "GenSigTimeoutTime_SRR01RR" SG_ 454 RR_CAN_TX_MUX_FRESPCE_CAL_DATA_3 150;
BA_ "GenSigCycleTime" SG_ 454 RR_CAN_TX_MUX_FRESPCE_CAL_DATA_4 50;
BA_ "GenSigTimeoutTime_SRR01RR" SG_ 454 RR_CAN_TX_MUX_FRESPCE_CAL_DATA_4 150;
BA_ "GenSigCycleTime" SG_ 454 RR_CAN_TX_MUX_FRESPCE_CAL_DATA_5 50;
BA_ "GenSigTimeoutTime_SRR01RR" SG_ 454 RR_CAN_TX_MUX_FRESPCE_CAL_DATA_5 150;
BA_ "GenSigCycleTime" SG_ 454 RR_CAN_TX_MUX_LCDA_CAL_MSG_CNT 50;
BA_ "GenSigTimeoutTime_SRR01RR" SG_ 454 RR_CAN_TX_MUX_LCDA_CAL_MSG_CNT 150;
BA_ "GenSigCycleTime" SG_ 454 RR_CAN_TX_MUX_LCDA_CAL_DATA_0 50;
BA_ "GenSigTimeoutTime_SRR01RR" SG_ 454 RR_CAN_TX_MUX_LCDA_CAL_DATA_0 150;
BA_ "GenSigCycleTime" SG_ 454 RR_CAN_TX_MUX_LCDA_CAL_DATA_1 50;
BA_ "GenSigTimeoutTime_SRR01RR" SG_ 454 RR_CAN_TX_MUX_LCDA_CAL_DATA_1 150;
BA_ "GenSigCycleTime" SG_ 454 RR_CAN_TX_MUX_LCDA_CAL_DATA_2 50;
BA_ "GenSigTimeoutTime_SRR01RR" SG_ 454 RR_CAN_TX_MUX_LCDA_CAL_DATA_2 150;
BA_ "GenSigCycleTime" SG_ 454 RR_CAN_TX_MUX_LCDA_CAL_DATA_3 50;
BA_ "GenSigTimeoutTime_SRR01RR" SG_ 454 RR_CAN_TX_MUX_LCDA_CAL_DATA_3 150;
BA_ "GenSigCycleTime" SG_ 454 RR_CAN_TX_MUX_LCDA_CAL_DATA_4 50;
BA_ "GenSigTimeoutTime_SRR01RR" SG_ 454 RR_CAN_TX_MUX_LCDA_CAL_DATA_4 150;
BA_ "GenSigCycleTime" SG_ 454 RR_CAN_TX_MUX_LCDA_CAL_DATA_5 50;
BA_ "GenSigTimeoutTime_SRR01RR" SG_ 454 RR_CAN_TX_MUX_LCDA_CAL_DATA_5 150;
BA_ "GenSigCycleTime" SG_ 454 RR_CAN_TX_MUX_CTA_CAL_MSG_CNT 50;
BA_ "GenSigTimeoutTime_SRR01RR" SG_ 454 RR_CAN_TX_MUX_CTA_CAL_MSG_CNT 150;
BA_ "GenSigCycleTime" SG_ 454 RR_CAN_TX_MUX_CTA_CAL_DATA_0 50;
BA_ "GenSigTimeoutTime_SRR01RR" SG_ 454 RR_CAN_TX_MUX_CTA_CAL_DATA_0 150;
BA_ "GenSigCycleTime" SG_ 454 RR_CAN_TX_MUX_CTA_CAL_DATA_1 50;
BA_ "GenSigTimeoutTime_SRR01RR" SG_ 454 RR_CAN_TX_MUX_CTA_CAL_DATA_1 150;
BA_ "GenSigCycleTime" SG_ 454 RR_CAN_TX_MUX_CTA_CAL_DATA_2 50;
BA_ "GenSigTimeoutTime_SRR01RR" SG_ 454 RR_CAN_TX_MUX_CTA_CAL_DATA_2 150;
BA_ "GenSigCycleTime" SG_ 454 RR_CAN_TX_MUX_CTA_CAL_DATA_3 50;
BA_ "GenSigTimeoutTime_SRR01RR" SG_ 454 RR_CAN_TX_MUX_CTA_CAL_DATA_3 150;
BA_ "GenSigCycleTime" SG_ 454 RR_CAN_TX_MUX_CTA_CAL_DATA_4 50;
BA_ "GenSigTimeoutTime_SRR01RR" SG_ 454 RR_CAN_TX_MUX_CTA_CAL_DATA_4 150;
BA_ "GenSigCycleTime" SG_ 454 RR_CAN_TX_MUX_CTA_CAL_DATA_5 50;
BA_ "GenSigTimeoutTime_SRR01RR" SG_ 454 RR_CAN_TX_MUX_CTA_CAL_DATA_5 150;
BA_ "GenSigCycleTime" SG_ 454 RR_CAN_TX_MUX_LOOKID_CAL_MSG_CNT 50;
BA_ "GenSigTimeoutTime_SRR01RR" SG_ 454 RR_CAN_TX_MUX_LOOKID_CAL_MSG_CNT 150;
BA_ "GenSigCycleTime" SG_ 454 RR_CAN_TX_MUX_LOOKID_CAL_DATA_0 50;
BA_ "GenSigTimeoutTime_SRR01RR" SG_ 454 RR_CAN_TX_MUX_LOOKID_CAL_DATA_0 150;
BA_ "GenSigCycleTime" SG_ 454 RR_CAN_TX_MUX_LOOKID_CAL_DATA_1 50;
BA_ "GenSigTimeoutTime_SRR01RR" SG_ 454 RR_CAN_TX_MUX_LOOKID_CAL_DATA_1 150;
BA_ "GenSigCycleTime" SG_ 454 RR_CAN_TX_MUX_LOOKID_CAL_DATA_2 50;
BA_ "GenSigTimeoutTime_SRR01RR" SG_ 454 RR_CAN_TX_MUX_LOOKID_CAL_DATA_2 150;
BA_ "GenSigCycleTime" SG_ 454 RR_CAN_TX_MUX_LOOKID_CAL_DATA_3 50;
BA_ "GenSigTimeoutTime_SRR01RR" SG_ 454 RR_CAN_TX_MUX_LOOKID_CAL_DATA_3 150;
BA_ "GenSigCycleTime" SG_ 454 RR_CAN_TX_MUX_LOOKID_CAL_DATA_4 50;
BA_ "GenSigTimeoutTime_SRR01RR" SG_ 454 RR_CAN_TX_MUX_LOOKID_CAL_DATA_4 150;
BA_ "GenSigCycleTime" SG_ 454 RR_CAN_TX_MUX_LOOKID_CAL_DATA_5 50;
BA_ "GenSigTimeoutTime_SRR01RR" SG_ 454 RR_CAN_TX_MUX_LOOKID_CAL_DATA_5 150;
BA_ "GenSigCycleTime" SG_ 454 RR_CAN_TX_MUX_ALIGNMT_CALMSG_CNT 50;
BA_ "GenSigTimeoutTime_SRR01RR" SG_ 454 RR_CAN_TX_MUX_ALIGNMT_CALMSG_CNT 150;
BA_ "GenSigCycleTime" SG_ 454 RR_CAN_TX_MUX_ALIGNMT_CAL_DATA_0 50;
BA_ "GenSigTimeoutTime_SRR01RR" SG_ 454 RR_CAN_TX_MUX_ALIGNMT_CAL_DATA_0 150;
BA_ "GenSigCycleTime" SG_ 454 RR_CAN_TX_MUX_ALIGNMT_CAL_DATA_1 50;
BA_ "GenSigTimeoutTime_SRR01RR" SG_ 454 RR_CAN_TX_MUX_ALIGNMT_CAL_DATA_1 150;
BA_ "GenSigCycleTime" SG_ 454 RR_CAN_TX_MUX_ALIGNMT_CAL_DATA_2 50;
BA_ "GenSigTimeoutTime_SRR01RR" SG_ 454 RR_CAN_TX_MUX_ALIGNMT_CAL_DATA_2 150;
BA_ "GenSigCycleTime" SG_ 454 RR_CAN_TX_MUX_ALIGNMT_CAL_DATA_3 50;
BA_ "GenSigTimeoutTime_SRR01RR" SG_ 454 RR_CAN_TX_MUX_ALIGNMT_CAL_DATA_3 150;
BA_ "GenSigCycleTime" SG_ 454 RR_CAN_TX_MUX_ALIGNMT_CAL_DATA_4 50;
BA_ "GenSigTimeoutTime_SRR01RR" SG_ 454 RR_CAN_TX_MUX_ALIGNMT_CAL_DATA_4 150;
BA_ "GenSigCycleTime" SG_ 454 RR_CAN_TX_MUX_ALIGNMT_CAL_DATA_5 50;
BA_ "GenSigTimeoutTime_SRR01RR" SG_ 454 RR_CAN_TX_MUX_ALIGNMT_CAL_DATA_5 150;
BA_ "GenSigCycleTime" SG_ 454 RR_CAN_TX_MUX_TRKER_CAL_MSG_CNT 50;
BA_ "GenSigTimeoutTime_SRR01RR" SG_ 454 RR_CAN_TX_MUX_TRKER_CAL_MSG_CNT 150;
BA_ "GenSigCycleTime" SG_ 454 RR_CAN_TX_MUX_TRKER_CAL_DATA_0 50;
BA_ "GenSigTimeoutTime_SRR01RR" SG_ 454 RR_CAN_TX_MUX_TRKER_CAL_DATA_0 150;
BA_ "GenSigCycleTime" SG_ 454 RR_CAN_TX_MUX_TRKER_CAL_DATA_1 50;
BA_ "GenSigTimeoutTime_SRR01RR" SG_ 454 RR_CAN_TX_MUX_TRKER_CAL_DATA_1 150;
BA_ "GenSigCycleTime" SG_ 454 RR_CAN_TX_MUX_TRKER_CAL_DATA_2 50;
BA_ "GenSigTimeoutTime_SRR01RR" SG_ 454 RR_CAN_TX_MUX_TRKER_CAL_DATA_2 150;
BA_ "GenSigCycleTime" SG_ 454 RR_CAN_TX_MUX_TRKER_CAL_DATA_3 50;
BA_ "GenSigTimeoutTime_SRR01RR" SG_ 454 RR_CAN_TX_MUX_TRKER_CAL_DATA_3 150;
BA_ "GenSigCycleTime" SG_ 454 RR_CAN_TX_MUX_TRKER_CAL_DATA_4 50;
BA_ "GenSigTimeoutTime_SRR01RR" SG_ 454 RR_CAN_TX_MUX_TRKER_CAL_DATA_4 150;
BA_ "GenSigCycleTime" SG_ 454 RR_CAN_TX_MUX_TRKER_CAL_DATA_5 50;
BA_ "GenSigTimeoutTime_SRR01RR" SG_ 454 RR_CAN_TX_MUX_TRKER_CAL_DATA_5 150;
BA_ "GenSigCycleTime" SG_ 454 RR_CAN_TX_MUX_SMC_CAL_MSG_CNT 50;
BA_ "GenSigTimeoutTime_SRR01RR" SG_ 454 RR_CAN_TX_MUX_SMC_CAL_MSG_CNT 150;
BA_ "GenSigCycleTime" SG_ 454 RR_CAN_TX_MUX_SMC_CAL_DATA_0 50;
BA_ "GenSigTimeoutTime_SRR01RR" SG_ 454 RR_CAN_TX_MUX_SMC_CAL_DATA_0 150;
BA_ "GenSigCycleTime" SG_ 454 RR_CAN_TX_MUX_SMC_CAL_DATA_1 50;
BA_ "GenSigTimeoutTime_SRR01RR" SG_ 454 RR_CAN_TX_MUX_SMC_CAL_DATA_1 150;
BA_ "GenSigCycleTime" SG_ 454 RR_CAN_TX_MUX_SMC_CAL_DATA_2 50;
BA_ "GenSigTimeoutTime_SRR01RR" SG_ 454 RR_CAN_TX_MUX_SMC_CAL_DATA_2 150;
BA_ "GenSigCycleTime" SG_ 454 RR_CAN_TX_MUX_SMC_CAL_DATA_3 50;
BA_ "GenSigTimeoutTime_SRR01RR" SG_ 454 RR_CAN_TX_MUX_SMC_CAL_DATA_3 150;
BA_ "GenSigCycleTime" SG_ 454 RR_CAN_TX_MUX_SMC_CAL_DATA_4 50;
BA_ "GenSigTimeoutTime_SRR01RR" SG_ 454 RR_CAN_TX_MUX_SMC_CAL_DATA_4 150;
BA_ "GenSigCycleTime" SG_ 454 RR_CAN_TX_MUX_SMC_CAL_DATA_5 50;
BA_ "GenSigTimeoutTime_SRR01RR" SG_ 454 RR_CAN_TX_MUX_SMC_CAL_DATA_5 150;
BA_ "GenSigCycleTime" SG_ 454 RR_CAN_TX_MUX_USC_CAL_MSG_CNT 50;
BA_ "GenSigTimeoutTime_SRR01RR" SG_ 454 RR_CAN_TX_MUX_USC_CAL_MSG_CNT 150;
BA_ "GenSigCycleTime" SG_ 454 RR_CAN_TX_MUX_USC_CAL_DATA_0 50;
BA_ "GenSigTimeoutTime_SRR01RR" SG_ 454 RR_CAN_TX_MUX_USC_CAL_DATA_0 150;
BA_ "GenSigCycleTime" SG_ 454 RR_CAN_TX_MUX_USC_CAL_DATA_1 50;
BA_ "GenSigTimeoutTime_SRR01RR" SG_ 454 RR_CAN_TX_MUX_USC_CAL_DATA_1 150;
BA_ "GenSigCycleTime" SG_ 454 RR_CAN_TX_MUX_USC_CAL_DATA_2 50;
BA_ "GenSigTimeoutTime_SRR01RR" SG_ 454 RR_CAN_TX_MUX_USC_CAL_DATA_2 150;
BA_ "GenSigCycleTime" SG_ 454 RR_CAN_TX_MUX_USC_CAL_DATA_3 50;
BA_ "GenSigTimeoutTime_SRR01RR" SG_ 454 RR_CAN_TX_MUX_USC_CAL_DATA_3 150;
BA_ "GenSigCycleTime" SG_ 454 RR_CAN_TX_MUX_USC_CAL_DATA_4 50;
BA_ "GenSigTimeoutTime_SRR01RR" SG_ 454 RR_CAN_TX_MUX_USC_CAL_DATA_4 150;
BA_ "GenSigCycleTime" SG_ 454 RR_CAN_TX_MUX_USC_CAL_DATA_5 50;
BA_ "GenSigTimeoutTime_SRR01RR" SG_ 454 RR_CAN_TX_MUX_USC_CAL_DATA_5 150;
BA_ "GenSigCycleTime" SG_ 454 RR_CAN_TX_MUX_ALIGN_CAL_VER_MNR 50;
BA_ "GenSigTimeoutTime_SRR01RR" SG_ 454 RR_CAN_TX_MUX_ALIGN_CAL_VER_MNR 150;
BA_ "GenSigCycleTime" SG_ 454 RR_CAN_TX_MUX_ALIGN_CAL_VER_MJR 50;
BA_ "GenSigTimeoutTime_SRR01RR" SG_ 454 RR_CAN_TX_MUX_ALIGN_CAL_VER_MJR 150;
BA_ "GenSigCycleTime" SG_ 454 RR_CAN_TX_MUX_ALIGN_SW_VER_MINOR 50;
BA_ "GenSigTimeoutTime_SRR01RR" SG_ 454 RR_CAN_TX_MUX_ALIGN_SW_VER_MINOR 150;
BA_ "GenSigCycleTime" SG_ 454 RR_CAN_TX_MUX_ALIGN_SW_VER_MAJOR 50;
BA_ "GenSigTimeoutTime_SRR01RR" SG_ 454 RR_CAN_TX_MUX_ALIGN_SW_VER_MAJOR 150;
BA_ "GenSigCycleTime" SG_ 454 RR_CAN_TX_MUX_USC_CAL_VER_MAJOR 50;
BA_ "GenSigTimeoutTime_SRR01RR" SG_ 454 RR_CAN_TX_MUX_USC_CAL_VER_MAJOR 150;
BA_ "GenSigCycleTime" SG_ 454 RR_CAN_TX_MUX_TRKR_CAL_VER_MINOR 50;
BA_ "GenSigTimeoutTime_SRR01RR" SG_ 454 RR_CAN_TX_MUX_TRKR_CAL_VER_MINOR 150;
BA_ "GenSigCycleTime" SG_ 454 RR_CAN_TX_MUX_TRKR_CAL_VER_MAJOR 50;
BA_ "GenSigTimeoutTime_SRR01RR" SG_ 454 RR_CAN_TX_MUX_TRKR_CAL_VER_MAJOR 150;
BA_ "GenSigCycleTime" SG_ 454 RR_CAN_TX_MUX_TRKR_SW_VER_MINOR 50;
BA_ "GenSigTimeoutTime_SRR01RR" SG_ 454 RR_CAN_TX_MUX_TRKR_SW_VER_MINOR 150;
BA_ "GenSigCycleTime" SG_ 454 RR_CAN_TX_MUX_TRKR_SW_VER_MAJOR 50;
BA_ "GenSigTimeoutTime_SRR01RR" SG_ 454 RR_CAN_TX_MUX_TRKR_SW_VER_MAJOR 150;
BA_ "GenSigCycleTime" SG_ 454 RR_CAN_TX_MUX_SMC_CAL_VER_MINOR 50;
BA_ "GenSigTimeoutTime_SRR01RR" SG_ 454 RR_CAN_TX_MUX_SMC_CAL_VER_MINOR 150;
BA_ "GenSigCycleTime" SG_ 454 RR_CAN_TX_MUX_SMC_CAL_VER_MAJOR 50;
BA_ "GenSigTimeoutTime_SRR01RR" SG_ 454 RR_CAN_TX_MUX_SMC_CAL_VER_MAJOR 150;
BA_ "GenSigCycleTime" SG_ 454 RR_CAN_TX_MUX_RECW_CAL_VER_MINOR 50;
BA_ "GenSigTimeoutTime_SRR01RR" SG_ 454 RR_CAN_TX_MUX_RECW_CAL_VER_MINOR 150;
BA_ "GenSigCycleTime" SG_ 454 RR_CAN_TX_MUX_RECW_CAL_VER_MAJOR 50;
BA_ "GenSigTimeoutTime_SRR01RR" SG_ 454 RR_CAN_TX_MUX_RECW_CAL_VER_MAJOR 150;
BA_ "GenSigCycleTime" SG_ 454 RR_CAN_TX_MUX_RECW_SW_VER_MINOR 50;
BA_ "GenSigTimeoutTime_SRR01RR" SG_ 454 RR_CAN_TX_MUX_RECW_SW_VER_MINOR 150;
BA_ "GenSigCycleTime" SG_ 454 RR_CAN_TX_MUX_RECW_SW_VER_MAJOR 50;
BA_ "GenSigTimeoutTime_SRR01RR" SG_ 454 RR_CAN_TX_MUX_RECW_SW_VER_MAJOR 150;
BA_ "GenSigCycleTime" SG_ 454 RR_CAN_TX_MUX_RCWM_CAL_VER_MINOR 50;
BA_ "GenSigTimeoutTime_SRR01RR" SG_ 454 RR_CAN_TX_MUX_RCWM_CAL_VER_MINOR 150;
BA_ "GenSigCycleTime" SG_ 454 RR_CAN_TX_MUX_RCWM_CAL_VER_MAJOR 50;
BA_ "GenSigTimeoutTime_SRR01RR" SG_ 454 RR_CAN_TX_MUX_RCWM_CAL_VER_MAJOR 150;
BA_ "GenSigCycleTime" SG_ 454 RR_CAN_TX_MUX_RCWM_SW_VER_MINOR 50;
BA_ "GenSigTimeoutTime_SRR01RR" SG_ 454 RR_CAN_TX_MUX_RCWM_SW_VER_MINOR 150;
BA_ "GenSigCycleTime" SG_ 454 RR_CAN_TX_MUX_RCWM_SW_VER_MAJOR 50;
BA_ "GenSigTimeoutTime_SRR01RR" SG_ 454 RR_CAN_TX_MUX_RCWM_SW_VER_MAJOR 150;
BA_ "GenSigCycleTime" SG_ 454 RR_CAN_TX_MUX_RCTA_CAL_VER_MINOR 50;
BA_ "GenSigTimeoutTime_SRR01RR" SG_ 454 RR_CAN_TX_MUX_RCTA_CAL_VER_MINOR 150;
BA_ "GenSigCycleTime" SG_ 454 RR_CAN_TX_MUX_RCTA_CAL_VER_MAJOR 50;
BA_ "GenSigTimeoutTime_SRR01RR" SG_ 454 RR_CAN_TX_MUX_RCTA_CAL_VER_MAJOR 150;
BA_ "GenSigCycleTime" SG_ 454 RR_CAN_TX_MUX_RCTA_SW_VER_MINOR 50;
BA_ "GenSigTimeoutTime_SRR01RR" SG_ 454 RR_CAN_TX_MUX_RCTA_SW_VER_MINOR 150;
BA_ "GenSigCycleTime" SG_ 454 RR_CAN_TX_MUX_RCTA_SW_VER_MAJOR 50;
BA_ "GenSigTimeoutTime_SRR01RR" SG_ 454 RR_CAN_TX_MUX_RCTA_SW_VER_MAJOR 150;
BA_ "GenSigCycleTime" SG_ 454 RR_CAN_TX_MUX_LCDA_CAL_VER_MINOR 50;
BA_ "GenSigTimeoutTime_SRR01RR" SG_ 454 RR_CAN_TX_MUX_LCDA_CAL_VER_MINOR 150;
BA_ "GenSigCycleTime" SG_ 454 RR_CAN_TX_MUX_LCDA_CAL_VER_MAJOR 50;
BA_ "GenSigTimeoutTime_SRR01RR" SG_ 454 RR_CAN_TX_MUX_LCDA_CAL_VER_MAJOR 150;
BA_ "GenSigCycleTime" SG_ 454 RR_CAN_TX_MUX_LCDA_SW_VER_MINOR 50;
BA_ "GenSigTimeoutTime_SRR01RR" SG_ 454 RR_CAN_TX_MUX_LCDA_SW_VER_MINOR 150;
BA_ "GenSigCycleTime" SG_ 454 RR_CAN_TX_MUX_LCDA_SW_VER_MAJOR 50;
BA_ "GenSigTimeoutTime_SRR01RR" SG_ 454 RR_CAN_TX_MUX_LCDA_SW_VER_MAJOR 150;
BA_ "GenSigCycleTime" SG_ 454 RR_CAN_TX_MUX_FRESP_CAL_VER_MNR 50;
BA_ "GenSigTimeoutTime_SRR01RR" SG_ 454 RR_CAN_TX_MUX_FRESP_CAL_VER_MNR 150;
BA_ "GenSigCycleTime" SG_ 454 RR_CAN_TX_MUX_FRESP_CAL_VER_MJR 50;
BA_ "GenSigTimeoutTime_SRR01RR" SG_ 454 RR_CAN_TX_MUX_FRESP_CAL_VER_MJR 150;
BA_ "GenSigCycleTime" SG_ 454 RR_CAN_TX_MUX_FRESP_SW_VER_MINOR 50;
BA_ "GenSigTimeoutTime_SRR01RR" SG_ 454 RR_CAN_TX_MUX_FRESP_SW_VER_MINOR 150;
BA_ "GenSigCycleTime" SG_ 454 RR_CAN_TX_MUX_FRESP_SW_VER_MAJOR 50;
BA_ "GenSigTimeoutTime_SRR01RR" SG_ 454 RR_CAN_TX_MUX_FRESP_SW_VER_MAJOR 150;
BA_ "GenSigCycleTime" SG_ 454 RR_CAN_TX_MUX_FCTA_CAL_VER_MINOR 50;
BA_ "GenSigTimeoutTime_SRR01RR" SG_ 454 RR_CAN_TX_MUX_FCTA_CAL_VER_MINOR 150;
BA_ "GenSigCycleTime" SG_ 454 RR_CAN_TX_MUX_FCTA_CAL_VER_MAJOR 50;
BA_ "GenSigTimeoutTime_SRR01RR" SG_ 454 RR_CAN_TX_MUX_FCTA_CAL_VER_MAJOR 150;
BA_ "GenSigCycleTime" SG_ 454 RR_CAN_TX_MUX_FCTA_SW_VER_MINOR 50;
BA_ "GenSigTimeoutTime_SRR01RR" SG_ 454 RR_CAN_TX_MUX_FCTA_SW_VER_MINOR 150;
BA_ "GenSigCycleTime" SG_ 454 RR_CAN_TX_MUX_FCTA_SW_VER_MAJOR 50;
BA_ "GenSigTimeoutTime_SRR01RR" SG_ 454 RR_CAN_TX_MUX_FCTA_SW_VER_MAJOR 150;
BA_ "GenSigCycleTime" SG_ 454 RR_CAN_TX_MUX_VCS_OFFSET_LONG 50;
BA_ "GenSigTimeoutTime_SRR01RR" SG_ 454 RR_CAN_TX_MUX_VCS_OFFSET_LONG 150;
BA_ "GenSigStartValue" SG_ 454 RR_CAN_TX_MUX_VCS_OFFSET_LONG 65535;
BA_ "GenSigCycleTime" SG_ 454 RR_CAN_TX_MUX_VCS_OFFSET_LAT 50;
BA_ "GenSigTimeoutTime_SRR01RR" SG_ 454 RR_CAN_TX_MUX_VCS_OFFSET_LAT 150;
BA_ "GenSigStartValue" SG_ 454 RR_CAN_TX_MUX_VCS_OFFSET_LAT 32767.5;
BA_ "GenSigCycleTime" SG_ 454 RR_CAN_TX_MUX_CORE_VERSION 50;
BA_ "GenSigTimeoutTime_SRR01RR" SG_ 454 RR_CAN_TX_MUX_CORE_VERSION 150;
BA_ "GenSigCycleTime" SG_ 454 RR_CAN_TX_MUX_SENSOR_POLARITY 50;
BA_ "GenSigTimeoutTime_SRR01RR" SG_ 454 RR_CAN_TX_MUX_SENSOR_POLARITY 150;
BA_ "GenSigCycleTime" SG_ 454 RR_CAN_TX_MUX_SENSOR_LAT_OFFSET 50;
BA_ "GenSigTimeoutTime_SRR01RR" SG_ 454 RR_CAN_TX_MUX_SENSOR_LAT_OFFSET 150;
BA_ "GenSigCycleTime" SG_ 454 RR_CAN_TX_MUX_SENSOR_LONG_OFFSET 50;
BA_ "GenSigTimeoutTime_SRR01RR" SG_ 454 RR_CAN_TX_MUX_SENSOR_LONG_OFFSET 150;
BA_ "GenSigCycleTime" SG_ 454 RR_CAN_TX_MUX_SNSR_ANGLE_OFFSET 50;
BA_ "GenSigTimeoutTime_SRR01RR" SG_ 454 RR_CAN_TX_MUX_SNSR_ANGLE_OFFSET 150;
BA_ "GenSigCycleTime" SG_ 454 RR_CAN_TX_MUX_KINK_ANGL_VER_MNR 50;
BA_ "GenSigTimeoutTime_SRR01RR" SG_ 454 RR_CAN_TX_MUX_KINK_ANGL_VER_MNR 150;
BA_ "GenSigCycleTime" SG_ 454 RR_CAN_TX_MUX_KINK_ANGL_VER_MJR 50;
BA_ "GenSigTimeoutTime_SRR01RR" SG_ 454 RR_CAN_TX_MUX_KINK_ANGL_VER_MJR 150;
BA_ "GenSigCycleTime" SG_ 454 RR_CAN_TX_MUX_ID 50;
BA_ "GenSigTimeoutTime_SRR01RR" SG_ 454 RR_CAN_TX_MUX_ID 150;
BA_ "GenSigCmt" SG_ 455 RR_CAN_NUMBER_OF_DET "Number of detections sent";
BA_ "GenSigCmt" SG_ 455 RR_CAN_SCAN_INDEX_FUSED "Scan index fused";
BA_ "GenSigCmt" SG_ 455 RR_CAN_LOOK_ID "Indicates the look type values 1 to 4 base on medium/long look and near/far look";
BA_ "GenSigCmt" SG_ 455 RR_CAN_LOOK_INDEX "Scan index for SODFR";
BA_ "GenSigCmt" SG_ 456 RR_CAN_RANGE_COVERAGE "CAN range coverage";
BA_ "GenSigCmt" SG_ 456 RR_CAN_DOPPLER_COVERAGE "CAN range coverage";
BA_ "GenSigStartValue" SG_ 456 RR_CAN_DOPPLER_COVERAGE 32768;
BA_ "GenSigCmt" SG_ 456 RR_CAN_FOV_HOR "CAN range coverage";
BA_ "GenSigCmt" SG_ 456 RR_CAN_FOV_VER "CAN range coverage";
BA_ "GenSigCmt" SG_ 457 RR_CAN_ACTIVE_FAULTS "Active faults";
BA_ "GenSigCmt" SG_ 458 RR_CAN_LATCH_FAULTS "Active Latch Faults";
VAL_ 395 RL_Horizontal_Alignment_Status 15 "Undefined" 14 "Undefined" 13 "Low Amplitude (Flat-plate only)" 12 "No Peak (Flat-plate only)" 11 "Fail Ver and Hor OutOfRange" 10 "Fail Vertical Align OutOfRange" 9 "Fail Horizontal Align OutOfRange" 8 "Fail Time Out" 7 "Fail Only SODR Target Found" 6 "Fail Only SODL Target Found" 5 "Fail Variance Too Large" 4 "Fail Deviation Too Large" 3 "Fail No Target" 2 "Success" 1 "Busy" 0 "Off" ;
VAL_ 395 RL_Vertical_Alignment_Status 15 "Undefined" 14 "Undefined" 13 "Low Amplitude (Flat-plate only)" 12 "No Peak (Flat-plate only)" 11 "Fail Ver and Hor OutOfRange" 10 "Fail Vertical Align OutOfRange" 9 "Fail Horizontal Align OutOfRange" 8 "Fail Time Out" 7 "Fail Only SODR Target Found" 6 "Fail Only SODL Target Found" 5 "Fail Variance Too Large" 4 "Fail Deviation Too Large" 3 "Fail No Target" 2 "Success" 1 "Busy" 0 "Off" ;
VAL_ 395 RL_Vertical_Alignment_State 6 "Static alignment flat-plate" 5 "Static alignment 2-target" 4 "Static alignment 1-target" 3 "Service alignment" 2 "Short track alignment" 1 "Auto alignment" 0 "Off" ;
VAL_ 395 RL_Horizontal_Alignment_State 6 "Static alignment flat-plate" 5 "Static alignment 2-target" 4 "Static alignment 1-target" 3 "Service alignment" 2 "Short track alignment" 1 "Auto alignment" 0 "Off" ;
VAL_ 395 RL_Align_Vertical_QF 3 "Accurate" 2 "Innacurate" 1 "Temporarily undefined (Faulty)" 0 "Undefined" ;
VAL_ 395 RL_Align_Horizontal_QF 3 "Accurate" 2 "Innacurate" 1 "Temporarily undefined (Faulty)" 0 "Undefined" ;
VAL_ 459 RR_Horizontal_Alignment_Status 15 "Undefined" 14 "Undefined" 13 "Low Amplitude (Flat-plate only)" 12 "No Peak (Flat-plate only)" 11 "Fail Ver and Hor OutOfRange" 10 "Fail Vertical Align OutOfRange" 9 "Fail Horizontal Align OutOfRange" 8 "Fail Time Out" 7 "Fail Only SODR Target Found" 6 "Fail Only SODL Target Found" 5 "Fail Variance Too Large" 4 "Fail Deviation Too Large" 3 "Fail No Target" 2 "Success" 1 "Busy" 0 "Off" ;
VAL_ 459 RR_Vertical_Alignment_Status 15 "Undefined" 14 "Undefined" 13 "Low Amplitude (Flat-plate only)" 12 "No Peak (Flat-plate only)" 11 "Fail Ver and Hor OutOfRange" 10 "Fail Vertical Align OutOfRange" 9 "Fail Horizontal Align OutOfRange" 8 "Fail Time Out" 7 "Fail Only SODR Target Found" 6 "Fail Only SODL Target Found" 5 "Fail Variance Too Large" 4 "Fail Deviation Too Large" 3 "Fail No Target" 2 "Success" 1 "Busy" 0 "Off" ;
VAL_ 459 RR_Vertical_Alignment_State 6 "Static alignment flat-plate" 5 "Static alignment 2-target" 4 "Static alignment 1-target" 3 "Service alignment" 2 "Short track alignment" 1 "Auto alignment" 0 "Off" ;
VAL_ 459 RR_Horizontal_Alignment_State 6 "Static alignment flat-plate" 5 "Static alignment 2-target" 4 "Static alignment 1-target" 3 "Service alignment" 2 "Short track alignment" 1 "Auto alignment" 0 "Off" ;
VAL_ 459 RR_Align_Vertical_QF 3 "Accurate" 2 "Innacurate" 1 "Temporarily undefined (Faulty)" 0 "Undefined" ;
VAL_ 459 RR_Align_Horizontal_QF 3 "Accurate" 2 "Innacurate" 1 "Temporarily undefined (Faulty)" 0 "Undefined" ;
VAL_ 513 SRR_CAN_YAW_RATE_CALC_QF 3 "Accurate" 2 "Innaccurate" 1 "Temporarily Undefined" 0 "Undefined" ;
VAL_ 513 SRR_CAN_VEHICLE_SPEED_CALC_QF 3 "Accurate" 2 "Innaccurate" 1 "Temporarily Undefined" 0 "Undefined" ;
VAL_ 4 ADAS_SRR_Trig_Control 1 "Front Bus" 0 "Rear Bus" ;
VAL_ 514 SRR_CAN_VEH_BATT_VOLT 255 "Fault" ;
VAL_ 514 SRR_CAN_IGN_STATUS 15 "Invalid" 8 "Start" 4 "Run" 2 "Accessory" 1 "Off" 0 "Unknown" ;
VAL_ 514 SRR_CAN_GEAR_POSITION 15 "Fault" 14 "Unknown_Position" 13 "NotUsed_2" 12 "NotUsed_1" 11 "sixth" 10 "fifth" 9 "fourth" 8 "third" 7 "second" 6 "first" 5 "Low" 4 "Sport_DriveSport" 3 "Drive" 2 "Neutral" 1 "Reverse" 0 "Park" ;
VAL_ 514 SRR_CAN_WIPER_STATUS 1 "On" 0 "Off" ;
VAL_ 514 SRR_PwPckTq_D_Stat 3 "PwPckOn_TqAvailable" 2 "StartInPrgrss_TqNotAvail" 1 "PwPckOn_TqNotAvailable" 0 "PwPckOff_TqNotAvailable" ;
VAL_ 514 SRR_CcStat_D_Actl 7 "Undefined_2" 6 "Undefined_1" 5 "Active" 4 "Active_Que_Assist" 3 "Standby" 2 "Standby_Denied" 1 "Denied" 0 "Off" ;
VAL_ 514 SRR_ElPw_D_Stat 7 "NotUsed_3" 6 "NotUsed_2" 5 "NotUsed_1" 4 "Fault_Limited" 3 "LV_Event_In_Progress" 2 "Not_Supported_Imminent" 1 "Supported" 0 "Not_Supported" ;
VAL_ 514 SRR_VehOverGnd_V_Est 65535 "Invalid" 65534 "Unknown" ;
VAL_ 514 SRR_CAN_LROS_DrivingDirection 4 "-" 2 "Forward" 1 "Backward" 0 "Unknown" ;
VAL_ 514 SRR_CAN_LROS_DrivingReverse 1 "Reverse" 0 "Not_Reverse" ;
VAL_ 385 RL_CAN_TX_SW_VERSION_DSP 71426 "2.23.1" 71170 "2.22.1" 5890 "2.23" ;
VAL_ 385 RL_CAN_TX_SW_VERSION_ARM 66827 "1.5.11" 66826 "1.5.10" ;
VAL_ 391 RL_Sensor_Position 4 "Rear Left" 3 "Rear Right" 2 "Front Left" 1 "Front Right" 0 "Unknown" ;
VAL_ 391 RL_Sensor_Position_Lock 1 "Unlocked" 0 "Locked" ;
VAL_ 449 RR_CAN_TX_SW_VERSION_DSP 71426 "2.23.1" 71170 "2.22.1" 5890 "2.23" ;
VAL_ 449 RR_CAN_TX_SW_VERSION_ARM 66827 "1.5.11" 66826 "1.5.10" ;
VAL_ 455 RR_Sensor_Position 4 "Rear Left" 3 "Rear Right" 2 "Front Left" 1 "Front Right" 0 "Unknown" ;
VAL_ 455 RR_Sensor_Position_Lock 1 "Unlocked" 0 "Locked" ;
